VERSION ""

NS_ :

BS_:

BU_: Bat1 OpticalSensor TelemetryNode Master SensorF SensorR BrakeF BrakeR PDU TestBench MDB1 MDB2 MDB3 MDB4 MDB5 MDB6 Track CLU

BO_ 1474 SensorR_SDO_Req_Up: 8 TelemetryNode
 SG_ SensorR_OD_posDeviationOptic m3589 : 16|16@1+ (0.1,0) [0|6553.5] ""  SensorR
 SG_ SensorR_OD_posDeviationEncoder m3588 : 16|16@1+ (0.1,0) [0|6553.5] ""  SensorR
 SG_ SensorR_OD_velDeviationOptic m3587 : 16|16@1+ (0.1,0) [0|6553.5] ""  SensorR
 SG_ SensorR_OD_velDeviationEncoder m3586 : 16|16@1+ (0.1,0) [0|6553.5] ""  SensorR
 SG_ SensorR_OD_accDeviation m3585 : 16|16@1+ (0.1,0) [0|6553.5] ""  SensorR
 SG_ SensorR_OD_EnableSignalGene_0000 m3332 : 16|8@1+ (1,0) [0|255] ""  SensorR
 SG_ SensorR_OD_PositionGlitch m3331 : 16|16@1+ (0.1,0) [0|6553.5] ""  SensorR
 SG_ SensorR_OD_ReflectorDistance m3330 : 16|16@1+ (0.1,0) [0|6553.5] ""  SensorR
 SG_ SensorR_OD_StripeMode m3329 : 16|8@1+ (1,0) [0|255] ""  SensorR
 SG_ SensorR_OD_opc_lowpass_TcI m3123 : 16|16@1+ (0.01,0) [0|655.35] "s"  SensorR
 SG_ SensorR_OD_opc_lowpass_Tcf m3122 : 16|16@1+ (0.01,0) [0|655.35] "s"  SensorR
 SG_ SensorR_OD_opc_F_decrease m3121 : 16|16@1+ (0.01,0) [0|655.35] "F/s"  SensorR
 SG_ SensorR_OD_opc_v_threshold m3120 : 16|16@1+ (0.01,0) [0|655.35] "m/s"  SensorR
 SG_ SensorR_OD_opc_v_max m3113 : 16|16@1+ (0.01,0) [0|655.35] "m/s"  SensorR
 SG_ SensorR_OD_opc_T_acc m3112 : 16|16@1+ (0.1,0) [0|6553.5] "s"  SensorR
 SG_ SensorR_OD_opc_F_max m3111 : 16|16@1+ (1,0) [0|65535] "N"  SensorR
 SG_ SensorR_OD_opc_t_run_max m3110 : 16|16@1+ (0.1,0) [0|6553.5] "s"  SensorR
 SG_ SensorR_OD_opc_brakeFlag m3109 : 16|8@1+ (1,0) [0|255] ""  SensorR
 SG_ SensorR_OD_DebugCVOPCfreq m3108 : 16|16@1+ (0.1,-3200) [-3200|3353.5] ""  SensorR
 SG_ SensorR_OD_DebugCascadedIreq m3107 : 16|16@1+ (0.1,-3200) [-3200|3353.5] ""  SensorR
 SG_ SensorR_OD_opc_ratelimiter_f m3106 : 16|16@1+ (0.1,-3200) [-3200|3353.5] ""  SensorR
 SG_ SensorR_OD_maxRunDistance m3105 : 16|16@1+ (0.05,-1600) [-1600|1676.75] "m"  SensorR
 SG_ SensorR_OD_FinishedDelay m3104 : 16|16@1+ (1,0) [0|65535] "ms"  SensorR
 SG_ SensorR_OD_Current4Stopping m3097 : 16|16@1+ (0.1,0) [0|6553.5] "A"  SensorR
 SG_ SensorR_OD_AdaptModelByCurrent m3096 : 16|8@1+ (1,0) [0|255] ""  SensorR
 SG_ SensorR_OD_CVOPCTcFreq m3095 : 16|16@1+ (1,0) [0|65535] "ms"  SensorR
 SG_ SensorR_OD_CVOPCImin m3094 : 16|16@1+ (1,0) [0|65535] ""  SensorR
 SG_ SensorR_OD_CascadedKpDecrea_0000 m3093 : 16|16@1+ (0.1,0) [0|6553.5] "A/s"  SensorR
 SG_ SensorR_OD_CascadedKpIncrea_0000 m3092 : 16|16@1+ (0.1,0) [0|6553.5] "A/s"  SensorR
 SG_ SensorR_OD_CascadedFreqCurUpdate m3091 : 16|16@1+ (0.001,0) [0|65.535] "s"  SensorR
 SG_ SensorR_OD_CascadedMaxSetFo_0000 m3090 : 16|16@1+ (0.1,0) [0|6553.5] "Newton"  SensorR
 SG_ SensorR_OD_CurrentForConsta_0000 m3089 : 16|16@1+ (0.01,0) [0|655.35] "A"  SensorR
 SG_ SensorR_OD_AccAtCurrentMeasured m3088 : 16|16@1+ (0.01,0) [0|655.35] "m/s^2"  SensorR
 SG_ SensorR_OD_CVOPCHystereseF m3081 : 16|16@1+ (0.1,0) [0|6553.5] "Newton"  SensorR
 SG_ SensorR_OD_CVOPCReduceCurre_0000 m3080 : 16|16@1+ (0.01,0) [0|655.35] ""  SensorR
 SG_ SensorR_OD_CVOPCDeltaVelHig_0000 m3079 : 16|16@1+ (0.01,0) [0|655.35] "m/s"  SensorR
 SG_ SensorR_OD_CVOPCSmoothingDe_0000 m3078 : 16|16@1+ (0.01,0) [0|655.35] "m/s"  SensorR
 SG_ SensorR_OD_CVOPCTcI m3077 : 16|16@1+ (1,0) [0|65535] "ms"  SensorR
 SG_ SensorR_OD_CVOPCTcf m3076 : 16|16@1+ (1,0) [0|65535] "ms"  SensorR
 SG_ SensorR_OD_CVOPCImax m3075 : 16|16@1+ (1,0) [0|65535] ""  SensorR
 SG_ SensorR_OD_VelocityController m3074 : 16|8@1+ (1,0) [0|255] ""  SensorR
 SG_ SensorR_OD_TC_f m3073 : 16|16@1+ (1,0) [0|65535] "ms"  SensorR
 SG_ SensorR_OD_TC_I m3072 : 16|16@1+ (1,0) [0|65535] "ms"  SensorR
 SG_ SensorR_OD_EstimatedRunLength m2826 : 16|16@1+ (0.05,-1600) [-1600|1676.75] "m"  SensorR
 SG_ SensorR_OD_RunProfile_V4 m2825 : 16|16@1+ (0.01,-327) [-327|328.35] "m/s"  SensorR
 SG_ SensorR_OD_RunProfile_T4 m2824 : 16|16@1+ (10,0) [0|655350] "ms"  SensorR
 SG_ SensorR_OD_RunProfile_V3 m2823 : 16|16@1+ (0.01,-327) [-327|328.35] "m/s"  SensorR
 SG_ SensorR_OD_RunProfile_T3 m2822 : 16|16@1+ (10,0) [0|655350] "ms"  SensorR
 SG_ SensorR_OD_RunProfile_V2 m2821 : 16|16@1+ (0.01,-327) [-327|328.35] "m/s"  SensorR
 SG_ SensorR_OD_RunProfile_T2 m2820 : 16|16@1+ (10,0) [0|655350] "ms"  SensorR
 SG_ SensorR_OD_RunProfile_V1 m2819 : 16|16@1+ (0.01,-327) [-327|328.35] "m/s"  SensorR
 SG_ SensorR_OD_RunProfile_T1 m2818 : 16|16@1+ (10,0) [0|655350] "ms"  SensorR
 SG_ SensorR_OD_RunProfile_V0 m2817 : 16|16@1+ (0.01,-327) [-327|328.35] "m/s"  SensorR
 SG_ SensorR_OD_RunProfile_T0 m2816 : 16|16@1+ (10,0) [0|655350] "ms"  SensorR
 SG_ SensorR_OD_SetFinish m2637 : 16|8@1+ (1,0) [0|255] ""  SensorR
 SG_ SensorR_OD_RunMode m2636 : 16|8@1+ (1,0) [0|255] ""  SensorR
 SG_ SensorR_OD_VdcReduceFactor m2635 : 16|16@1+ (0.1,0) [0|6553.5] ""  SensorR
 SG_ SensorR_OD_MaxRequiredVelocity m2634 : 16|16@1+ (0.1,0) [0|6553.5] "m/s"  SensorR
 SG_ SensorR_OD_WarningThreshhol_0000 m2633 : 16|16@1+ (0.001,0) [0|65.535] "s"  SensorR
 SG_ SensorR_OD_MaxCtrlErrorDuration m2632 : 16|16@1+ (0.01,0) [0|655.35] "s"  SensorR
 SG_ SensorR_OD_MaxCtrlError m2631 : 16|16@1+ (0.01,0) [0|655.35] "m/s"  SensorR
 SG_ SensorR_OD_FminCtrl m2630 : 16|16@1+ (1.0,0) [0|65535.0] "N"  SensorR
 SG_ SensorR_OD_FmaxCtrl m2629 : 16|16@1+ (1.0,0) [0|65535.0] "N"  SensorR
 SG_ SensorR_OD_PodMass m2628 : 16|16@1+ (0.1,0) [0|6553.5] "kg"  SensorR
 SG_ SensorR_OD_CurrentReq m2627 : 16|16@1+ (0.1,0) [0|6553.5] "A"  SensorR
 SG_ SensorR_OD_CtrlMode m2626 : 16|8@1+ (1,0) [0|255] ""  SensorR
 SG_ SensorR_OD_OpcKi m2625 : 16|16@1+ (0.01,0) [0|655.35] ""  SensorR
 SG_ SensorR_OD_OpcKp m2624 : 16|16@1+ (0.01,0) [0|655.35] ""  SensorR
 SG_ SensorR_OD_ExecTimeReadSensors m2611 : 16|16@1+ (0.01,0) [0|655.35] "ms"  SensorR
 SG_ SensorR_OD_ExecTimeControl m2610 : 16|16@1+ (0.01,0) [0|655.35] "ms"  SensorR
 SG_ SensorR_OD_ExecTimeStateEst m2609 : 16|16@1+ (0.01,0) [0|655.35] "ms"  SensorR
 SG_ SensorR_OD_ExecTimeOverall m2608 : 16|16@1+ (0.01,0) [0|655.35] "ms"  SensorR
 SG_ SensorR_OD_IMU3_Temperature m2599 : 16|16@1+ (0.01,-100) [-100|555.35] ""  SensorR
 SG_ SensorR_OD_IMU2_Temperature m2598 : 16|16@1+ (0.01,-100) [-100|555.35] ""  SensorR
 SG_ SensorR_OD_IMU1_Temperature m2597 : 16|16@1+ (0.01,-100) [-100|555.35] ""  SensorR
 SG_ SensorR_OD_IMU_number m2592 : 16|8@1+ (1,0) [0|255] ""  SensorR
 SG_ SensorR_OD_EncoderResetPosition m2586 : 16|8@1+ (1,0) [0|255] ""  SensorR
 SG_ SensorR_OD_EncoderWheelDiameter m2576 : 16|16@1+ (0.005,0) [1|300] "mm"  SensorR
 SG_ SensorR_OD_samplingInterval m2048 : 16|16@1+ (0.01,0) [0.01|100] "ms"  SensorR
 SG_ SensorR_OD_CAN2_DelayedTxMe_0000 m1129 : 16|24@1+ (1,0) [0|16777215] ""  SensorR
 SG_ SensorR_OD_CAN2_ErrorStatus m1128 : 16|8@1+ (1,0) [0|255] ""  SensorR
 SG_ SensorR_OD_CAN2_DiscardedTx_0000 m1127 : 16|24@1+ (1,0) [0|16777215] ""  SensorR
 SG_ SensorR_OD_CAN2_Status m1126 : 16|8@1+ (1,0) [0|255] ""  SensorR
 SG_ SensorR_OD_CAN2_Baudrate m1124 : 16|16@1+ (1,0) [125|1000] "kbps"  SensorR
 SG_ SensorR_OD_CAN2_autoErrorReset m1123 : 16|8@1+ (1,0) [0|255] ""  SensorR
 SG_ SensorR_OD_CAN2_lastErrorCode m1122 : 16|32@1+ (1,0) [0|4294967295] ""  SensorR
 SG_ SensorR_OD_CAN2_RxErrCnt m1121 : 16|8@1+ (1,0) [0|255] ""  SensorR
 SG_ SensorR_OD_CAN2_TxErrCnt m1120 : 16|8@1+ (1,0) [0|255] ""  SensorR
 SG_ SensorR_OD_CAN1_DelayedTxMe_0000 m1113 : 16|24@1+ (1,0) [0|16777215] ""  SensorR
 SG_ SensorR_OD_CAN1_ErrorStatus m1112 : 16|8@1+ (1,0) [0|255] ""  SensorR
 SG_ SensorR_OD_CAN1_DiscardedTx_0000 m1111 : 16|24@1+ (1,0) [0|16777215] ""  SensorR
 SG_ SensorR_OD_CAN1_Status m1110 : 16|8@1+ (1,0) [0|255] ""  SensorR
 SG_ SensorR_OD_CAN1_Baudrate m1108 : 16|16@1+ (1,0) [125|1000] "kbps"  SensorR
 SG_ SensorR_OD_CAN1_autoErrorReset m1107 : 16|8@1+ (1,0) [0|255] ""  SensorR
 SG_ SensorR_OD_CAN1_lastErrorCode m1106 : 16|32@1+ (1,0) [0|4294967295] ""  SensorR
 SG_ SensorR_OD_CAN1_RxErrCnt m1105 : 16|8@1+ (1,0) [0|255] ""  SensorR
 SG_ SensorR_OD_CAN1_TxErrCnt m1104 : 16|8@1+ (1,0) [0|255] ""  SensorR
 SG_ SensorR_OD_BuildTime m1073 : 16|24@1+ (1,0) [0|16777215] ""  SensorR
 SG_ SensorR_OD_BuildDate m1072 : 16|32@1+ (1,0) [0|4294967295] ""  SensorR
 SG_ SensorR_OD_ChipUID2 m1057 : 16|48@1+ (1,0) [0|281474976710655] ""  SensorR
 SG_ SensorR_OD_ChipUID1 m1056 : 16|48@1+ (1,0) [0|281474976710655] ""  SensorR
 SG_ SensorR_OD_SdcOut m1046 : 16|8@1+ (1,0) [0|255] ""  SensorR
 SG_ SensorR_OD_SdcIn m1045 : 16|8@1+ (1,0) [0|255] ""  SensorR
 SG_ SensorR_OD_runtime m1044 : 16|24@1+ (1,0) [0|16777215] "ms"  SensorR
 SG_ SensorR_OD_InputVoltage m1043 : 16|16@1+ (0.001,0) [0|65.535] "V"  SensorR
 SG_ SensorR_OD_BoardTemp m1042 : 16|16@1+ (0.01,-30) [-30|625.35] "°C"  SensorR
 SG_ SensorR_OD_MemFree m1041 : 16|16@1+ (4,0) [0|262140] "bytes"  SensorR
 SG_ SensorR_OD_CpuUsage m1040 : 16|8@1+ (0.5,0) [0|100] "%"  SensorR
 SG_ SensorR_OD_OdEntrySendInterval m33 : 16|16@1+ (1,0) [0|65535] "ms"  SensorR
 SG_ SensorR_OD_SendOdOnBootup m32 : 16|8@1+ (1,0) [0|255] ""  SensorR
 SG_ SensorR_OD_HeartbeatInterval m16 : 16|16@1+ (1,0) [0|65535] "ms"  SensorR
 SG_ SensorR_OD_DbcVersion m5 : 16|16@1+ (1,0) [0|65535] ""  SensorR
 SG_ SensorR_OD_StackVersion m4 : 16|16@1+ (1,0) [0|65535] ""  SensorR
 SG_ SensorR_OD_ProtocolVersion m3 : 16|16@1+ (1,0) [0|65535] ""  SensorR
 SG_ SensorR_OD_NodeStatus m2 : 16|8@1+ (1,0) [0|255] ""  SensorR
 SG_ SensorR_OD_NodeID m1 : 16|8@1+ (1,0) [0|255] ""  SensorR
 SG_ SensorR_SDO_ID M : 0|12@1+ (1,0) [0|4095] ""  SensorR

BO_ 1538 SensorR_SDO_Req_Down: 2 TelemetryNode
 SG_ SensorR_SDO_ID M : 0|12@1+ (1,0) [0|4095] ""  SensorR

BO_ 1794 SensorR_Heartbeat: 1 SensorR
 SG_ SensorR_NodeState : 0|8@1+ (1,0) [0|0] ""  Master,TelemetryNode

BO_ 1858 SensorR_BTL_TX: 8 SensorR

BO_ 1922 SensorR_BTL_RX: 8 TelemetryNode

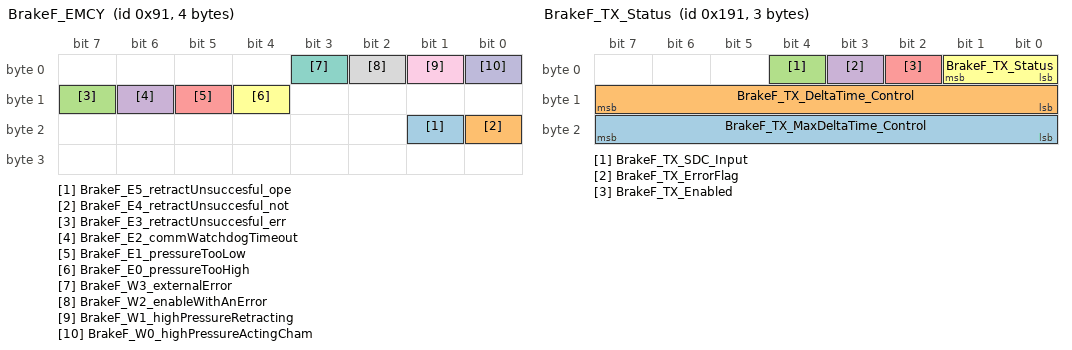
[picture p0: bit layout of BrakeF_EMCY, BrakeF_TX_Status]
BO_ 145 BrakeF_EMCY: 4 BrakeF
 SG_ BrakeF_E5_retractUnsuccesful_ope : 17|1@1+ (1,0) [0|0] ""  Master,TelemetryNode
 SG_ BrakeF_E4_retractUnsuccesful_not : 16|1@1+ (1,0) [0|0] ""  Master,TelemetryNode
 SG_ BrakeF_E3_retractUnsuccesful_err : 15|1@1+ (1,0) [0|0] ""  Master,TelemetryNode
 SG_ BrakeF_E2_commWatchdogTimeout : 14|1@1+ (1,0) [0|0] ""  Master,TelemetryNode
 SG_ BrakeF_E1_pressureTooLow : 13|1@1+ (1,0) [0|0] ""  Master,TelemetryNode
 SG_ BrakeF_E0_pressureTooHigh : 12|1@1+ (1,0) [0|0] ""  Master,TelemetryNode
 SG_ BrakeF_W3_externalError : 3|1@1+ (1,0) [0|0] ""  Master,TelemetryNode
 SG_ BrakeF_W2_enableWithAnError : 2|1@1+ (1,0) [0|0] ""  Master,TelemetryNode
 SG_ BrakeF_W1_highPressureRetracting : 1|1@1+ (1,0) [0|0] ""  Master,TelemetryNode
 SG_ BrakeF_W0_highPressureActingCham : 0|1@1+ (1,0) [0|0] ""  Master,TelemetryNode

BO_ 401 BrakeF_TX_Status: 3 BrakeF
 SG_ BrakeF_TX_MaxDeltaTime_Control : 16|8@1+ (1,0) [0|255] "ms" Vector__XXX
 SG_ BrakeF_TX_DeltaTime_Control : 8|8@1+ (1,0) [0|255] "ms" Vector__XXX
 SG_ BrakeF_TX_SDC_Input : 4|1@1+ (1,0) [0|0] "" Vector__XXX
 SG_ BrakeF_TX_ErrorFlag : 3|1@1+ (1,0) [0|0] ""  SensorF
 SG_ BrakeF_TX_Enabled : 2|1@1+ (1,0) [0|0] ""  SensorF
 SG_ BrakeF_TX_Status : 0|2@1+ (1,0) [0|0] ""  SensorF

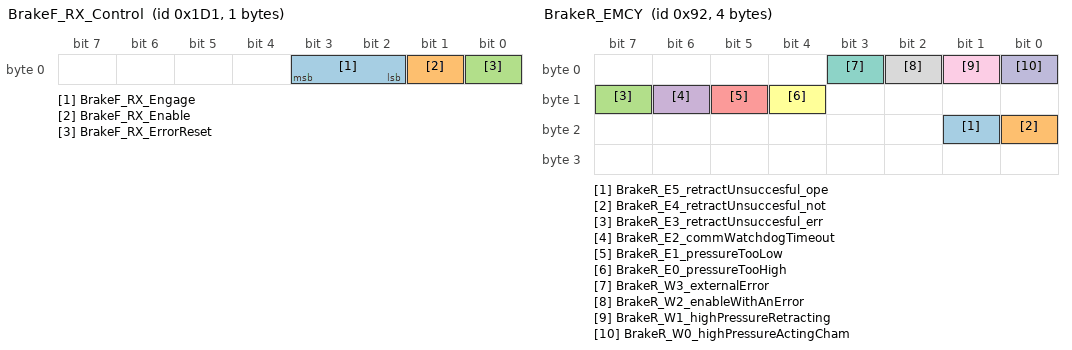
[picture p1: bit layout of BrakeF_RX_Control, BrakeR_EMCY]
BO_ 465 BrakeF_RX_Control: 1 SensorF
 SG_ BrakeF_RX_Engage : 2|2@1+ (1,0) [0|0] "" Vector__XXX
 SG_ BrakeF_RX_Enable : 1|1@1+ (1,0) [0|0] "" Vector__XXX
 SG_ BrakeF_RX_ErrorReset : 0|1@1+ (1,0) [0|0] "" Vector__XXX

BO_ 529 BrakeF_TX_PDO2: 0 BrakeF

BO_ 593 BrakeF_RX_PDO2: 0 Vector__XXX

BO_ 657 BrakeF_TX_PDO3: 0 BrakeF

BO_ 721 BrakeF_RX_PDO3: 0 Vector__XXX

BO_ 785 BrakeF_TX_PDO4: 0 BrakeF

BO_ 849 BrakeF_RX_PDO4: 0 Vector__XXX

BO_ 913 BrakeF_TX_PDO5: 0 BrakeF

BO_ 977 BrakeF_TX_PDO6: 0 BrakeF

BO_ 1105 BrakeF_TX_PDO8: 0 BrakeF

BO_ 1169 BrakeF_TX_PDO9: 0 BrakeF

BO_ 1233 BrakeF_TX_PDO10: 0 BrakeF

BO_ 1297 BrakeF_TX_PDO11: 0 BrakeF

BO_ 1361 BrakeF_TX_PDO12: 0 BrakeF

BO_ 1425 BrakeF_SDO_Resp: 8 BrakeF
 SG_ BrakeF_OD_BrakeStatus m2304 : 16|8@1+ (1,0) [0|255] ""  TelemetryNode
 SG_ BrakeF_OD_CoolingPressure m2816 : 16|16@1+ (0.01,-100) [-100|555.35] ""  TelemetryNode
 SG_ BrakeF_OD_valveUpperTolerance m2053 : 16|16@1+ (0.005,0) [0|327.675] "bar"  TelemetryNode
 SG_ BrakeF_OD_commWatchdog m2052 : 16|16@1+ (1,0) [0|65535] "ms"  TelemetryNode
 SG_ BrakeF_OD_counterLimit m2051 : 16|8@1+ (1,0) [0|255] ""  TelemetryNode
 SG_ BrakeF_OD_delay m2050 : 16|8@1+ (0.5,0) [0|127.5] "ms"  TelemetryNode
 SG_ BrakeF_OD_tankUpperControlLimit m2049 : 16|16@1+ (0.005,0) [0|327.675] "bar"  TelemetryNode
 SG_ BrakeF_OD_tankLowerControlLimit m2048 : 16|16@1+ (0.005,0) [0|327.675] "bar"  TelemetryNode
 SG_ BrakeF_OD_CAN2_DelayedTxMessages m1129 : 16|24@1+ (1,0) [0|16777215] ""  TelemetryNode
 SG_ BrakeF_OD_CAN2_ErrorStatus m1128 : 16|8@1+ (1,0) [0|255] ""  TelemetryNode
 SG_ BrakeF_OD_CAN2_DiscardedTxMessag m1127 : 16|24@1+ (1,0) [0|16777215] ""  TelemetryNode
 SG_ BrakeF_OD_CAN2_Status m1126 : 16|8@1+ (1,0) [0|255] ""  TelemetryNode
 SG_ BrakeF_OD_CAN2_Baudrate m1124 : 16|16@1+ (1,0) [125|1000] "kbps"  TelemetryNode
 SG_ BrakeF_OD_CAN2_autoErrorReset m1123 : 16|8@1+ (1,0) [0|255] ""  TelemetryNode
 SG_ BrakeF_OD_CAN2_lastErrorCode m1122 : 16|32@1+ (1,0) [0|4294967295] ""  TelemetryNode
 SG_ BrakeF_OD_CAN2_RxErrCnt m1121 : 16|8@1+ (1,0) [0|255] ""  TelemetryNode
 SG_ BrakeF_OD_CAN2_TxErrCnt m1120 : 16|8@1+ (1,0) [0|255] ""  TelemetryNode
 SG_ BrakeF_OD_CAN1_DelayedTxMessages m1113 : 16|24@1+ (1,0) [0|16777215] ""  TelemetryNode
 SG_ BrakeF_OD_CAN1_ErrorStatus m1112 : 16|8@1+ (1,0) [0|255] ""  TelemetryNode
 SG_ BrakeF_OD_CAN1_DiscardedTxMessag m1111 : 16|24@1+ (1,0) [0|16777215] ""  TelemetryNode
 SG_ BrakeF_OD_CAN1_Status m1110 : 16|8@1+ (1,0) [0|255] ""  TelemetryNode
 SG_ BrakeF_OD_CAN1_Baudrate m1108 : 16|16@1+ (1,0) [125|1000] "kbps"  TelemetryNode
 SG_ BrakeF_OD_CAN1_autoErrorReset m1107 : 16|8@1+ (1,0) [0|255] ""  TelemetryNode
 SG_ BrakeF_OD_CAN1_lastErrorCode m1106 : 16|32@1+ (1,0) [0|4294967295] ""  TelemetryNode
 SG_ BrakeF_OD_CAN1_RxErrCnt m1105 : 16|8@1+ (1,0) [0|255] ""  TelemetryNode
 SG_ BrakeF_OD_CAN1_TxErrCnt m1104 : 16|8@1+ (1,0) [0|255] ""  TelemetryNode
 SG_ BrakeF_OD_BuildTime m1073 : 16|24@1+ (1,0) [0|16777215] ""  TelemetryNode
 SG_ BrakeF_OD_BuildDate m1072 : 16|32@1+ (1,0) [0|4294967295] ""  TelemetryNode
 SG_ BrakeF_OD_ChipUID2 m1057 : 16|48@1+ (1,0) [0|281474976710655] ""  TelemetryNode
 SG_ BrakeF_OD_ChipUID1 m1056 : 16|48@1+ (1,0) [0|281474976710655] ""  TelemetryNode
 SG_ BrakeF_OD_SdcOut m1046 : 16|8@1+ (1,0) [0|255] ""  TelemetryNode
 SG_ BrakeF_OD_SdcIn m1045 : 16|8@1+ (1,0) [0|255] ""  TelemetryNode
 SG_ BrakeF_OD_runtime m1044 : 16|24@1+ (1,0) [0|16777215] "ms"  TelemetryNode
 SG_ BrakeF_OD_InputVoltage m1043 : 16|16@1+ (0.001,0) [0|65.535] "V"  TelemetryNode
 SG_ BrakeF_OD_BoardTemp m1042 : 16|16@1+ (0.01,-30) [-30|625.35] "°C"  TelemetryNode
 SG_ BrakeF_OD_MemFree m1041 : 16|16@1+ (4,0) [0|262140] "bytes"  TelemetryNode
 SG_ BrakeF_OD_CpuUsage m1040 : 16|8@1+ (0.5,0) [0|100] "%"  TelemetryNode
 SG_ BrakeF_OD_OdEntrySendInterval m33 : 16|16@1+ (1,0) [0|65535] "ms"  TelemetryNode
 SG_ BrakeF_OD_SendOdOnBootup m32 : 16|8@1+ (1,0) [0|255] ""  TelemetryNode
 SG_ BrakeF_OD_HeartbeatInterval m16 : 16|16@1+ (1,0) [0|65535] "ms"  TelemetryNode
 SG_ BrakeF_OD_DbcVersion m5 : 16|16@1+ (1,0) [0|65535] ""  TelemetryNode
 SG_ BrakeF_OD_StackVersion m4 : 16|16@1+ (1,0) [0|65535] ""  TelemetryNode
 SG_ BrakeF_OD_ProtocolVersion m3 : 16|16@1+ (1,0) [0|65535] ""  TelemetryNode
 SG_ BrakeF_OD_NodeStatus m2 : 16|8@1+ (1,0) [0|255] ""  TelemetryNode
 SG_ BrakeF_OD_NodeID m1 : 16|8@1+ (1,0) [0|255] ""  TelemetryNode
 SG_ BrakeF_SDO_RespCode : 12|4@1+ (1,0) [0|0] ""  TelemetryNode
 SG_ BrakeF_SDO_ID M : 0|12@1+ (1,0) [0|4095] ""  TelemetryNode

BO_ 1489 BrakeF_SDO_Req_Up: 8 TelemetryNode
 SG_ BrakeF_OD_BrakeStatus m2304 : 16|8@1+ (1,0) [0|255] ""  BrakeF
 SG_ BrakeF_OD_CoolingPressure m2816 : 16|16@1+ (0.01,-100) [-100|555.35] ""  BrakeF
 SG_ BrakeF_OD_valveUpperTolerance m2053 : 16|16@1+ (0.005,0) [0|327.675] "bar"  BrakeF
 SG_ BrakeF_OD_commWatchdog m2052 : 16|16@1+ (1,0) [0|65535] "ms"  BrakeF
 SG_ BrakeF_OD_counterLimit m2051 : 16|8@1+ (1,0) [0|255] ""  BrakeF
 SG_ BrakeF_OD_delay m2050 : 16|8@1+ (0.5,0) [0|127.5] "ms"  BrakeF
 SG_ BrakeF_OD_tankUpperControlLimit m2049 : 16|16@1+ (0.005,0) [0|327.675] "bar"  BrakeF
 SG_ BrakeF_OD_tankLowerControlLimit m2048 : 16|16@1+ (0.005,0) [0|327.675] "bar"  BrakeF
 SG_ BrakeF_OD_CAN2_DelayedTxMessages m1129 : 16|24@1+ (1,0) [0|16777215] ""  BrakeF
 SG_ BrakeF_OD_CAN2_ErrorStatus m1128 : 16|8@1+ (1,0) [0|255] ""  BrakeF
 SG_ BrakeF_OD_CAN2_DiscardedTxM_0000 m1127 : 16|24@1+ (1,0) [0|16777215] ""  BrakeF
 SG_ BrakeF_OD_CAN2_Status m1126 : 16|8@1+ (1,0) [0|255] ""  BrakeF
 SG_ BrakeF_OD_CAN2_Baudrate m1124 : 16|16@1+ (1,0) [125|1000] "kbps"  BrakeF
 SG_ BrakeF_OD_CAN2_autoErrorReset m1123 : 16|8@1+ (1,0) [0|255] ""  BrakeF
 SG_ BrakeF_OD_CAN2_lastErrorCode m1122 : 16|32@1+ (1,0) [0|4294967295] ""  BrakeF
 SG_ BrakeF_OD_CAN2_RxErrCnt m1121 : 16|8@1+ (1,0) [0|255] ""  BrakeF
 SG_ BrakeF_OD_CAN2_TxErrCnt m1120 : 16|8@1+ (1,0) [0|255] ""  BrakeF
 SG_ BrakeF_OD_CAN1_DelayedTxMessages m1113 : 16|24@1+ (1,0) [0|16777215] ""  BrakeF
 SG_ BrakeF_OD_CAN1_ErrorStatus m1112 : 16|8@1+ (1,0) [0|255] ""  BrakeF
 SG_ BrakeF_OD_CAN1_DiscardedTxM_0000 m1111 : 16|24@1+ (1,0) [0|16777215] ""  BrakeF
 SG_ BrakeF_OD_CAN1_Status m1110 : 16|8@1+ (1,0) [0|255] ""  BrakeF
 SG_ BrakeF_OD_CAN1_Baudrate m1108 : 16|16@1+ (1,0) [125|1000] "kbps"  BrakeF
 SG_ BrakeF_OD_CAN1_autoErrorReset m1107 : 16|8@1+ (1,0) [0|255] ""  BrakeF
 SG_ BrakeF_OD_CAN1_lastErrorCode m1106 : 16|32@1+ (1,0) [0|4294967295] ""  BrakeF
 SG_ BrakeF_OD_CAN1_RxErrCnt m1105 : 16|8@1+ (1,0) [0|255] ""  BrakeF
 SG_ BrakeF_OD_CAN1_TxErrCnt m1104 : 16|8@1+ (1,0) [0|255] ""  BrakeF
 SG_ BrakeF_OD_BuildTime m1073 : 16|24@1+ (1,0) [0|16777215] ""  BrakeF
 SG_ BrakeF_OD_BuildDate m1072 : 16|32@1+ (1,0) [0|4294967295] ""  BrakeF
 SG_ BrakeF_OD_ChipUID2 m1057 : 16|48@1+ (1,0) [0|281474976710655] ""  BrakeF
 SG_ BrakeF_OD_ChipUID1 m1056 : 16|48@1+ (1,0) [0|281474976710655] ""  BrakeF
 SG_ BrakeF_OD_SdcOut m1046 : 16|8@1+ (1,0) [0|255] ""  BrakeF
 SG_ BrakeF_OD_SdcIn m1045 : 16|8@1+ (1,0) [0|255] ""  BrakeF
 SG_ BrakeF_OD_runtime m1044 : 16|24@1+ (1,0) [0|16777215] "ms"  BrakeF
 SG_ BrakeF_OD_InputVoltage m1043 : 16|16@1+ (0.001,0) [0|65.535] "V"  BrakeF
 SG_ BrakeF_OD_BoardTemp m1042 : 16|16@1+ (0.01,-30) [-30|625.35] "°C"  BrakeF
 SG_ BrakeF_OD_MemFree m1041 : 16|16@1+ (4,0) [0|262140] "bytes"  BrakeF
 SG_ BrakeF_OD_CpuUsage m1040 : 16|8@1+ (0.5,0) [0|100] "%"  BrakeF
 SG_ BrakeF_OD_OdEntrySendInterval m33 : 16|16@1+ (1,0) [0|65535] "ms"  BrakeF
 SG_ BrakeF_OD_SendOdOnBootup m32 : 16|8@1+ (1,0) [0|255] ""  BrakeF
 SG_ BrakeF_OD_HeartbeatInterval m16 : 16|16@1+ (1,0) [0|65535] "ms"  BrakeF
 SG_ BrakeF_OD_DbcVersion m5 : 16|16@1+ (1,0) [0|65535] ""  BrakeF
 SG_ BrakeF_OD_StackVersion m4 : 16|16@1+ (1,0) [0|65535] ""  BrakeF
 SG_ BrakeF_OD_ProtocolVersion m3 : 16|16@1+ (1,0) [0|65535] ""  BrakeF
 SG_ BrakeF_OD_NodeStatus m2 : 16|8@1+ (1,0) [0|255] ""  BrakeF
 SG_ BrakeF_OD_NodeID m1 : 16|8@1+ (1,0) [0|255] ""  BrakeF
 SG_ BrakeF_SDO_ID M : 0|12@1+ (1,0) [0|4095] ""  BrakeF

BO_ 1553 BrakeF_SDO_Req_Down: 2 TelemetryNode
 SG_ BrakeF_SDO_ID M : 0|12@1+ (1,0) [0|4095] ""  BrakeF

BO_ 1809 BrakeF_Heartbeat: 1 BrakeF
 SG_ BrakeF_NodeState : 0|8@1+ (1,0) [0|0] ""  SensorF,Master,TelemetryNode

BO_ 1873 BrakeF_BTL_TX: 8 BrakeF

BO_ 1937 BrakeF_BTL_RX: 8 TelemetryNode

BO_ 146 BrakeR_EMCY: 4 BrakeR
 SG_ BrakeR_E5_retractUnsuccesful_ope : 17|1@1+ (1,0) [0|0] ""  Master,TelemetryNode
 SG_ BrakeR_E4_retractUnsuccesful_not : 16|1@1+ (1,0) [0|0] ""  Master,TelemetryNode
 SG_ BrakeR_E3_retractUnsuccesful_err : 15|1@1+ (1,0) [0|0] ""  Master,TelemetryNode
 SG_ BrakeR_E2_commWatchdogTimeout : 14|1@1+ (1,0) [0|0] ""  Master,TelemetryNode
 SG_ BrakeR_E1_pressureTooLow : 13|1@1+ (1,0) [0|0] ""  Master,TelemetryNode
 SG_ BrakeR_E0_pressureTooHigh : 12|1@1+ (1,0) [0|0] ""  Master,TelemetryNode
 SG_ BrakeR_W3_externalError : 3|1@1+ (1,0) [0|0] ""  Master,TelemetryNode
 SG_ BrakeR_W2_enableWithAnError : 2|1@1+ (1,0) [0|0] ""  Master,TelemetryNode
 SG_ BrakeR_W1_highPressureRetracting : 1|1@1+ (1,0) [0|0] ""  Master,TelemetryNode
 SG_ BrakeR_W0_highPressureActingCham : 0|1@1+ (1,0) [0|0] ""  Master,TelemetryNode

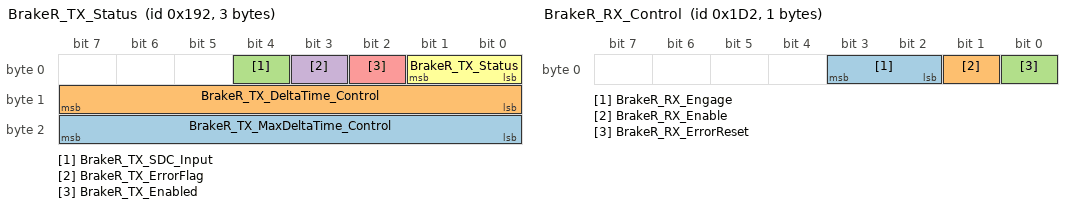
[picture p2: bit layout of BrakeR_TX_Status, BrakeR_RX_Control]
BO_ 402 BrakeR_TX_Status: 3 BrakeR
 SG_ BrakeR_TX_MaxDeltaTime_Control : 16|8@1+ (1,0) [0|255] "ms" Vector__XXX
 SG_ BrakeR_TX_DeltaTime_Control : 8|8@1+ (1,0) [0|255] "ms" Vector__XXX
 SG_ BrakeR_TX_SDC_Input : 4|1@1+ (1,0) [0|0] "" Vector__XXX
 SG_ BrakeR_TX_ErrorFlag : 3|1@1+ (1,0) [0|0] "" Vector__XXX
 SG_ BrakeR_TX_Enabled : 2|1@1+ (1,0) [0|0] "" Vector__XXX
 SG_ BrakeR_TX_Status : 0|2@1+ (1,0) [0|0] "" Vector__XXX

BO_ 466 BrakeR_RX_Control: 1 SensorF
 SG_ BrakeR_RX_Engage : 2|2@1+ (1,0) [0|0] "" Vector__XXX
 SG_ BrakeR_RX_Enable : 1|1@1+ (1,0) [0|0] "" Vector__XXX
 SG_ BrakeR_RX_ErrorReset : 0|1@1+ (1,0) [0|0] "" Vector__XXX

BO_ 530 BrakeR_TX_PDO2: 0 BrakeR

BO_ 594 BrakeR_RX_PDO2: 0 Vector__XXX

BO_ 658 BrakeR_TX_PDO3: 0 BrakeR

BO_ 722 BrakeR_RX_PDO3: 0 Vector__XXX

BO_ 786 BrakeR_TX_PDO4: 0 BrakeR

BO_ 850 BrakeR_RX_PDO4: 0 Vector__XXX

BO_ 914 BrakeR_TX_PDO5: 0 BrakeR

BO_ 978 BrakeR_TX_PDO6: 0 BrakeR

BO_ 1042 BrakeR_TX_PDO7: 0 BrakeR

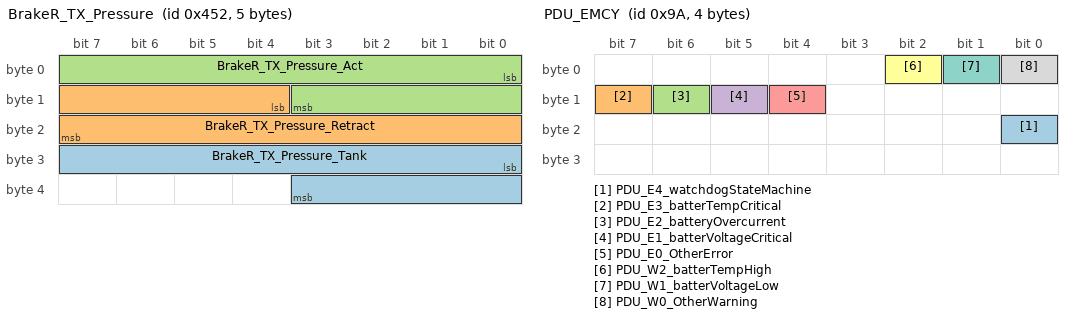
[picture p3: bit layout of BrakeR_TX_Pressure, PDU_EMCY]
BO_ 1106 BrakeR_TX_Pressure: 5 BrakeR
 SG_ BrakeR_TX_Pressure_Tank : 24|12@1+ (0.005,-2) [-2|18.475] "bar" Vector__XXX
 SG_ BrakeR_TX_Pressure_Retract : 12|12@1+ (0.005,-2) [-2|18.475] "bar" Vector__XXX
 SG_ BrakeR_TX_Pressure_Act : 0|12@1+ (0.005,-2) [-2|18.475] "bar" Vector__XXX

BO_ 1170 BrakeR_TX_PDO9: 0 BrakeR

BO_ 1234 BrakeR_TX_PDO10: 0 BrakeR

BO_ 1298 BrakeR_TX_PDO11: 0 BrakeR

BO_ 1362 BrakeR_TX_PDO12: 0 BrakeR

BO_ 1426 BrakeR_SDO_Resp: 8 BrakeR
 SG_ BrakeR_OD_valveUpperTolerance m2053 : 16|16@1+ (0.005,0) [0|327.675] "bar"  TelemetryNode
 SG_ BrakeR_OD_commWatchdog m2052 : 16|16@1+ (1,0) [0|65535] "ms"  TelemetryNode
 SG_ BrakeR_OD_counterLimit m2051 : 16|8@1+ (1,0) [0|255] ""  TelemetryNode
 SG_ BrakeR_OD_delay m2050 : 16|8@1+ (0.5,0) [0|127.5] "ms"  TelemetryNode
 SG_ BrakeR_OD_tankUpperControlLimit m2049 : 16|16@1+ (0.005,0) [0|327.675] "bar"  TelemetryNode
 SG_ BrakeR_OD_tankLowerControlLimit m2048 : 16|16@1+ (0.005,0) [0|327.675] "bar"  TelemetryNode
 SG_ BrakeR_OD_CAN2_DelayedTxMessages m1129 : 16|24@1+ (1,0) [0|16777215] ""  TelemetryNode
 SG_ BrakeR_OD_CAN2_ErrorStatus m1128 : 16|8@1+ (1,0) [0|255] ""  TelemetryNode
 SG_ BrakeR_OD_CAN2_DiscardedTxMessag m1127 : 16|24@1+ (1,0) [0|16777215] ""  TelemetryNode
 SG_ BrakeR_OD_CAN2_Status m1126 : 16|8@1+ (1,0) [0|255] ""  TelemetryNode
 SG_ BrakeR_OD_CAN2_Baudrate m1124 : 16|16@1+ (1,0) [125|1000] "kbps"  TelemetryNode
 SG_ BrakeR_OD_CAN2_autoErrorReset m1123 : 16|8@1+ (1,0) [0|255] ""  TelemetryNode
 SG_ BrakeR_OD_CAN2_lastErrorCode m1122 : 16|32@1+ (1,0) [0|4294967295] ""  TelemetryNode
 SG_ BrakeR_OD_CAN2_RxErrCnt m1121 : 16|8@1+ (1,0) [0|255] ""  TelemetryNode
 SG_ BrakeR_OD_CAN2_TxErrCnt m1120 : 16|8@1+ (1,0) [0|255] ""  TelemetryNode
 SG_ BrakeR_OD_CAN1_DelayedTxMessages m1113 : 16|24@1+ (1,0) [0|16777215] ""  TelemetryNode
 SG_ BrakeR_OD_CAN1_ErrorStatus m1112 : 16|8@1+ (1,0) [0|255] ""  TelemetryNode
 SG_ BrakeR_OD_CAN1_DiscardedTxMessag m1111 : 16|24@1+ (1,0) [0|16777215] ""  TelemetryNode
 SG_ BrakeR_OD_CAN1_Status m1110 : 16|8@1+ (1,0) [0|255] ""  TelemetryNode
 SG_ BrakeR_OD_CAN1_Baudrate m1108 : 16|16@1+ (1,0) [125|1000] "kbps"  TelemetryNode
 SG_ BrakeR_OD_CAN1_autoErrorReset m1107 : 16|8@1+ (1,0) [0|255] ""  TelemetryNode
 SG_ BrakeR_OD_CAN1_lastErrorCode m1106 : 16|32@1+ (1,0) [0|4294967295] ""  TelemetryNode
 SG_ BrakeR_OD_CAN1_RxErrCnt m1105 : 16|8@1+ (1,0) [0|255] ""  TelemetryNode
 SG_ BrakeR_OD_CAN1_TxErrCnt m1104 : 16|8@1+ (1,0) [0|255] ""  TelemetryNode
 SG_ BrakeR_OD_BuildTime m1073 : 16|24@1+ (1,0) [0|16777215] ""  TelemetryNode
 SG_ BrakeR_OD_BuildDate m1072 : 16|32@1+ (1,0) [0|4294967295] ""  TelemetryNode
 SG_ BrakeR_OD_ChipUID2 m1057 : 16|48@1+ (1,0) [0|281474976710655] ""  TelemetryNode
 SG_ BrakeR_OD_ChipUID1 m1056 : 16|48@1+ (1,0) [0|281474976710655] ""  TelemetryNode
 SG_ BrakeR_OD_SdcOut m1046 : 16|8@1+ (1,0) [0|255] ""  TelemetryNode
 SG_ BrakeR_OD_SdcIn m1045 : 16|8@1+ (1,0) [0|255] ""  TelemetryNode
 SG_ BrakeR_OD_runtime m1044 : 16|24@1+ (1,0) [0|16777215] "ms"  TelemetryNode
 SG_ BrakeR_OD_InputVoltage m1043 : 16|16@1+ (0.001,0) [0|65.535] "V"  TelemetryNode
 SG_ BrakeR_OD_BoardTemp m1042 : 16|16@1+ (0.01,-30) [-30|625.35] "°C"  TelemetryNode
 SG_ BrakeR_OD_MemFree m1041 : 16|16@1+ (4,0) [0|262140] "bytes"  TelemetryNode
 SG_ BrakeR_OD_CpuUsage m1040 : 16|8@1+ (0.5,0) [0|100] "%"  TelemetryNode
 SG_ BrakeR_OD_OdEntrySendInterval m33 : 16|16@1+ (1,0) [0|65535] "ms"  TelemetryNode
 SG_ BrakeR_OD_SendOdOnBootup m32 : 16|8@1+ (1,0) [0|255] ""  TelemetryNode
 SG_ BrakeR_OD_HeartbeatInterval m16 : 16|16@1+ (1,0) [0|65535] "ms"  TelemetryNode
 SG_ BrakeR_OD_DbcVersion m5 : 16|16@1+ (1,0) [0|65535] ""  TelemetryNode
 SG_ BrakeR_OD_StackVersion m4 : 16|16@1+ (1,0) [0|65535] ""  TelemetryNode
 SG_ BrakeR_OD_ProtocolVersion m3 : 16|16@1+ (1,0) [0|65535] ""  TelemetryNode
 SG_ BrakeR_OD_NodeStatus m2 : 16|8@1+ (1,0) [0|255] ""  TelemetryNode
 SG_ BrakeR_OD_NodeID m1 : 16|8@1+ (1,0) [0|255] ""  TelemetryNode
 SG_ BrakeR_SDO_RespCode : 12|4@1+ (1,0) [0|0] ""  TelemetryNode
 SG_ BrakeR_SDO_ID M : 0|12@1+ (1,0) [0|4095] ""  TelemetryNode

BO_ 1490 BrakeR_SDO_Req_Up: 8 TelemetryNode
 SG_ BrakeR_OD_valveUpperTolerance m2053 : 16|16@1+ (0.005,0) [0|327.675] "bar"  BrakeR
 SG_ BrakeR_OD_commWatchdog m2052 : 16|16@1+ (1,0) [0|65535] "ms"  BrakeR
 SG_ BrakeR_OD_counterLimit m2051 : 16|8@1+ (1,0) [0|255] ""  BrakeR
 SG_ BrakeR_OD_delay m2050 : 16|8@1+ (0.5,0) [0|127.5] "ms"  BrakeR
 SG_ BrakeR_OD_tankUpperControlLimit m2049 : 16|16@1+ (0.005,0) [0|327.675] "bar"  BrakeR
 SG_ BrakeR_OD_tankLowerControlLimit m2048 : 16|16@1+ (0.005,0) [0|327.675] "bar"  BrakeR
 SG_ BrakeR_OD_CAN2_DelayedTxMessages m1129 : 16|24@1+ (1,0) [0|16777215] ""  BrakeR
 SG_ BrakeR_OD_CAN2_ErrorStatus m1128 : 16|8@1+ (1,0) [0|255] ""  BrakeR
 SG_ BrakeR_OD_CAN2_DiscardedTxM_0000 m1127 : 16|24@1+ (1,0) [0|16777215] ""  BrakeR
 SG_ BrakeR_OD_CAN2_Status m1126 : 16|8@1+ (1,0) [0|255] ""  BrakeR
 SG_ BrakeR_OD_CAN2_Baudrate m1124 : 16|16@1+ (1,0) [125|1000] "kbps"  BrakeR
 SG_ BrakeR_OD_CAN2_autoErrorReset m1123 : 16|8@1+ (1,0) [0|255] ""  BrakeR
 SG_ BrakeR_OD_CAN2_lastErrorCode m1122 : 16|32@1+ (1,0) [0|4294967295] ""  BrakeR
 SG_ BrakeR_OD_CAN2_RxErrCnt m1121 : 16|8@1+ (1,0) [0|255] ""  BrakeR
 SG_ BrakeR_OD_CAN2_TxErrCnt m1120 : 16|8@1+ (1,0) [0|255] ""  BrakeR
 SG_ BrakeR_OD_CAN1_DelayedTxMessages m1113 : 16|24@1+ (1,0) [0|16777215] ""  BrakeR
 SG_ BrakeR_OD_CAN1_ErrorStatus m1112 : 16|8@1+ (1,0) [0|255] ""  BrakeR
 SG_ BrakeR_OD_CAN1_DiscardedTxM_0000 m1111 : 16|24@1+ (1,0) [0|16777215] ""  BrakeR
 SG_ BrakeR_OD_CAN1_Status m1110 : 16|8@1+ (1,0) [0|255] ""  BrakeR
 SG_ BrakeR_OD_CAN1_Baudrate m1108 : 16|16@1+ (1,0) [125|1000] "kbps"  BrakeR
 SG_ BrakeR_OD_CAN1_autoErrorReset m1107 : 16|8@1+ (1,0) [0|255] ""  BrakeR
 SG_ BrakeR_OD_CAN1_lastErrorCode m1106 : 16|32@1+ (1,0) [0|4294967295] ""  BrakeR
 SG_ BrakeR_OD_CAN1_RxErrCnt m1105 : 16|8@1+ (1,0) [0|255] ""  BrakeR
 SG_ BrakeR_OD_CAN1_TxErrCnt m1104 : 16|8@1+ (1,0) [0|255] ""  BrakeR
 SG_ BrakeR_OD_BuildTime m1073 : 16|24@1+ (1,0) [0|16777215] ""  BrakeR
 SG_ BrakeR_OD_BuildDate m1072 : 16|32@1+ (1,0) [0|4294967295] ""  BrakeR
 SG_ BrakeR_OD_ChipUID2 m1057 : 16|48@1+ (1,0) [0|281474976710655] ""  BrakeR
 SG_ BrakeR_OD_ChipUID1 m1056 : 16|48@1+ (1,0) [0|281474976710655] ""  BrakeR
 SG_ BrakeR_OD_SdcOut m1046 : 16|8@1+ (1,0) [0|255] ""  BrakeR
 SG_ BrakeR_OD_SdcIn m1045 : 16|8@1+ (1,0) [0|255] ""  BrakeR
 SG_ BrakeR_OD_runtime m1044 : 16|24@1+ (1,0) [0|16777215] "ms"  BrakeR
 SG_ BrakeR_OD_InputVoltage m1043 : 16|16@1+ (0.001,0) [0|65.535] "V"  BrakeR
 SG_ BrakeR_OD_BoardTemp m1042 : 16|16@1+ (0.01,-30) [-30|625.35] "°C"  BrakeR
 SG_ BrakeR_OD_MemFree m1041 : 16|16@1+ (4,0) [0|262140] "bytes"  BrakeR
 SG_ BrakeR_OD_CpuUsage m1040 : 16|8@1+ (0.5,0) [0|100] "%"  BrakeR
 SG_ BrakeR_OD_OdEntrySendInterval m33 : 16|16@1+ (1,0) [0|65535] "ms"  BrakeR
 SG_ BrakeR_OD_SendOdOnBootup m32 : 16|8@1+ (1,0) [0|255] ""  BrakeR
 SG_ BrakeR_OD_HeartbeatInterval m16 : 16|16@1+ (1,0) [0|65535] "ms"  BrakeR
 SG_ BrakeR_OD_DbcVersion m5 : 16|16@1+ (1,0) [0|65535] ""  BrakeR
 SG_ BrakeR_OD_StackVersion m4 : 16|16@1+ (1,0) [0|65535] ""  BrakeR
 SG_ BrakeR_OD_ProtocolVersion m3 : 16|16@1+ (1,0) [0|65535] ""  BrakeR
 SG_ BrakeR_OD_NodeStatus m2 : 16|8@1+ (1,0) [0|255] ""  BrakeR
 SG_ BrakeR_OD_NodeID m1 : 16|8@1+ (1,0) [0|255] ""  BrakeR
 SG_ BrakeR_SDO_ID M : 0|12@1+ (1,0) [0|4095] ""  BrakeR

BO_ 1554 BrakeR_SDO_Req_Down: 2 TelemetryNode
 SG_ BrakeR_SDO_ID M : 0|12@1+ (1,0) [0|4095] ""  BrakeR

BO_ 1810 BrakeR_Heartbeat: 1 BrakeR
 SG_ BrakeR_NodeState : 0|8@1+ (1,0) [0|0] ""  Master,TelemetryNode

BO_ 1874 BrakeR_BTL_TX: 8 BrakeR

BO_ 1938 BrakeR_BTL_RX: 8 TelemetryNode

BO_ 154 PDU_EMCY: 4 PDU
 SG_ PDU_E4_watchdogStateMachine : 16|1@1+ (1,0) [0|0] ""  Master,TelemetryNode
 SG_ PDU_E3_batterTempCritical : 15|1@1+ (1,0) [0|0] ""  Master,TelemetryNode
 SG_ PDU_E2_batteryOvercurrent : 14|1@1+ (1,0) [0|0] ""  Master,TelemetryNode
 SG_ PDU_E1_batterVoltageCritical : 13|1@1+ (1,0) [0|0] ""  Master,TelemetryNode
 SG_ PDU_E0_OtherError : 12|1@1+ (1,0) [0|0] ""  Master,TelemetryNode
 SG_ PDU_W2_batterTempHigh : 2|1@1+ (1,0) [0|0] ""  Master,TelemetryNode
 SG_ PDU_W1_batterVoltageLow : 1|1@1+ (1,0) [0|0] ""  Master,TelemetryNode
 SG_ PDU_W0_OtherWarning : 0|1@1+ (1,0) [0|0] ""  Master,TelemetryNode

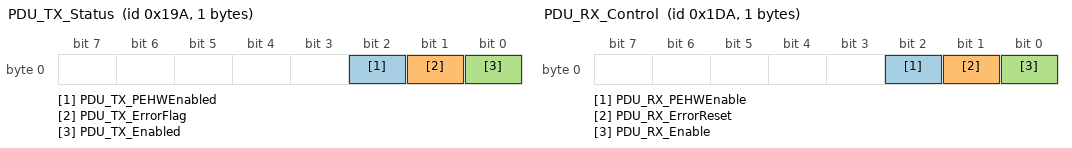
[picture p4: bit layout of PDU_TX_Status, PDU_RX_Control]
BO_ 410 PDU_TX_Status: 1 PDU
 SG_ PDU_TX_PEHWEnabled : 2|1@1+ (1,0) [0|0] ""  SensorF
 SG_ PDU_TX_ErrorFlag : 1|1@1+ (1,0) [0|0] ""  SensorF
 SG_ PDU_TX_Enabled : 0|1@1+ (1,0) [0|0] ""  SensorF

BO_ 474 PDU_RX_Control: 1 SensorF
 SG_ PDU_RX_PEHWEnable : 2|1@1+ (1,0) [0|0] ""  PDU
 SG_ PDU_RX_ErrorReset : 1|1@1+ (1,0) [0|0] ""  PDU
 SG_ PDU_RX_Enable : 0|1@1+ (1,0) [0|0] ""  PDU

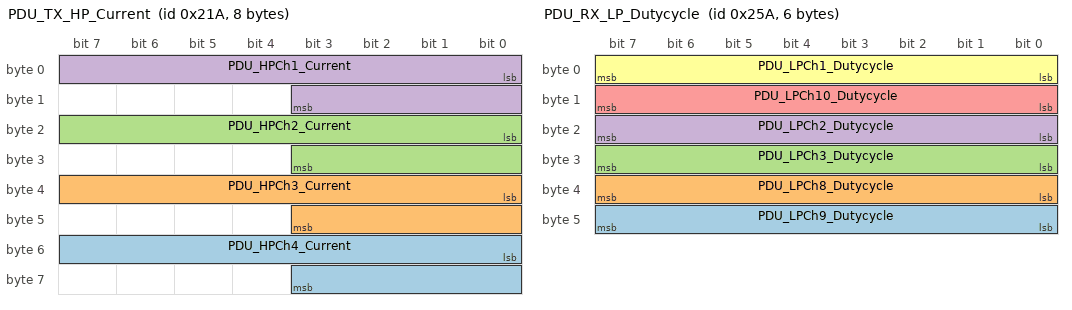
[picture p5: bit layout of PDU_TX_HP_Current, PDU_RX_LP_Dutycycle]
BO_ 538 PDU_TX_HP_Current: 8 PDU
 SG_ PDU_HPCh4_Current : 48|12@1+ (0.004,0) [0|16.38] "A"  SensorF
 SG_ PDU_HPCh3_Current : 32|12@1+ (0.004,0) [0|16.38] "A"  SensorF
 SG_ PDU_HPCh2_Current : 16|12@1+ (0.004,0) [0|16.38] "A"  SensorF
 SG_ PDU_HPCh1_Current : 0|12@1+ (0.004,0) [0|16.38] "A"  SensorF

BO_ 602 PDU_RX_LP_Dutycycle: 6 SensorF
 SG_ PDU_LPCh9_Dutycycle : 40|8@1+ (0.5,0) [0|100] "%" Vector__XXX
 SG_ PDU_LPCh8_Dutycycle : 32|8@1+ (0.5,0) [0|100] "%" Vector__XXX
 SG_ PDU_LPCh3_Dutycycle : 24|8@1+ (0.5,0) [0|100] "%" Vector__XXX
 SG_ PDU_LPCh2_Dutycycle : 16|8@1+ (0.5,0) [0|100] "%" Vector__XXX
 SG_ PDU_LPCh10_Dutycycle : 8|8@1+ (0.5,0) [0|100] "%" Vector__XXX
 SG_ PDU_LPCh1_Dutycycle : 0|8@1+ (0.5,0) [0|100] "%" Vector__XXX

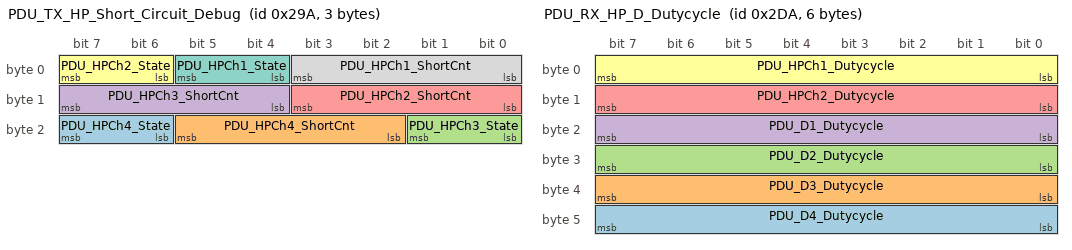
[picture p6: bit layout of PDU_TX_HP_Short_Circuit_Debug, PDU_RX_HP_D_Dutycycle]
BO_ 666 PDU_TX_HP_Short_Circuit_Debug: 3 PDU
 SG_ PDU_HPCh4_State : 22|2@1+ (1,0) [0|3] "" Vector__XXX
 SG_ PDU_HPCh4_ShortCnt : 18|4@1+ (1,0) [0|15] "" Vector__XXX
 SG_ PDU_HPCh3_State : 16|2@1+ (1,0) [0|3] "" Vector__XXX
 SG_ PDU_HPCh3_ShortCnt : 12|4@1+ (1,0) [0|15] "" Vector__XXX
 SG_ PDU_HPCh2_ShortCnt : 8|4@1+ (1,0) [0|15] "" Vector__XXX
 SG_ PDU_HPCh2_State : 6|2@1+ (1,0) [0|3] "" Vector__XXX
 SG_ PDU_HPCh1_State : 4|2@1+ (1,0) [0|3] "" Vector__XXX
 SG_ PDU_HPCh1_ShortCnt : 0|4@1+ (1,0) [0|15] "" Vector__XXX

BO_ 730 PDU_RX_HP_D_Dutycycle: 6 SensorF
 SG_ PDU_D4_Dutycycle : 40|8@1+ (0.5,0) [0|100] "%" Vector__XXX
 SG_ PDU_D3_Dutycycle : 32|8@1+ (0.5,0) [0|100] "%" Vector__XXX
 SG_ PDU_D2_Dutycycle : 24|8@1+ (0.5,0) [0|100] "%" Vector__XXX
 SG_ PDU_D1_Dutycycle : 16|8@1+ (0.5,0) [0|100] "%" Vector__XXX
 SG_ PDU_HPCh2_Dutycycle : 8|8@1+ (0.5,0) [0|100] "%" Vector__XXX
 SG_ PDU_HPCh1_Dutycycle : 0|8@1+ (0.5,0) [0|100] "%" Vector__XXX

BO_ 794 PDU_TX_PDO4: 0 PDU

BO_ 858 PDU_RX_Manual_Control: 3 Vector__XXX
 SG_ PDU_SDC_Enable : 18|1@1+ (1,0) [0|0] "" Vector__XXX
 SG_ PDU_D4_Enable : 17|1@1+ (1,0) [0|1] "" Vector__XXX
 SG_ PDU_D3_Enable : 16|1@1+ (1,0) [0|1] "" Vector__XXX
 SG_ PDU_D2_Enable : 15|1@1+ (1,0) [0|1] "" Vector__XXX
 SG_ PDU_D1_Enable : 14|1@1+ (1,0) [0|1] "" Vector__XXX
 SG_ PDU_HPCh4_Enable : 13|1@1+ (1,0) [0|1] "" Vector__XXX
 SG_ PDU_HPCh3_Enable : 12|1@1+ (1,0) [0|1] "" Vector__XXX
 SG_ PDU_HPCh2_Enable : 11|1@1+ (1,0) [0|1] "" Vector__XXX
 SG_ PDU_HPCh1_Enable : 10|1@1+ (1,0) [0|1] "" Vector__XXX
 SG_ PDU_LPCh10_Enable : 9|1@1+ (1,0) [0|1] "" Vector__XXX
 SG_ PDU_LPCh9_Enable : 8|1@1+ (1,0) [0|1] "" Vector__XXX
 SG_ PDU_LPCh8_Enable : 7|1@1+ (1,0) [0|1] "" Vector__XXX
 SG_ PDU_LPCh7_Enable : 6|1@1+ (1,0) [0|1] "" Vector__XXX
 SG_ PDU_LPCh6_Enable : 5|1@1+ (1,0) [0|1] "" Vector__XXX
 SG_ PDU_LPCh5_Enable : 4|1@1+ (1,0) [0|1] "" Vector__XXX
 SG_ PDU_LPCh4_Enable : 3|1@1+ (1,0) [0|1] "" Vector__XXX
 SG_ PDU_LPCh3_Enable : 2|1@1+ (1,0) [0|1] "" Vector__XXX
 SG_ PDU_LPCh2_Enable : 1|1@1+ (1,0) [0|1] "" Vector__XXX
 SG_ PDU_LPCh1_Enable : 0|1@1+ (1,0) [0|1] "" Vector__XXX

BO_ 922 PDU_TX_PDO5: 0 PDU

BO_ 986 PDU_TX_PDO6: 0 PDU

BO_ 1050 PDU_TX_PDO7: 0 PDU

BO_ 1114 PDU_TX_PDO8: 0 PDU

BO_ 1178 PDU_TX_LP_Short_Circuit_Debug: 8 PDU
 SG_ PDU_LPCh9_State : 58|2@1+ (1,0) [0|3] "" Vector__XXX
 SG_ PDU_LPCh8_State : 56|2@1+ (1,0) [0|3] "" Vector__XXX
 SG_ PDU_LPCh7_State : 54|2@1+ (1,0) [0|3] "" Vector__XXX
 SG_ PDU_LPCh6_State : 52|2@1+ (1,0) [0|3] "" Vector__XXX
 SG_ PDU_LPCh5_State : 50|2@1+ (1,0) [0|3] "" Vector__XXX
 SG_ PDU_LPCh4_State : 48|2@1+ (1,0) [0|3] "" Vector__XXX
 SG_ PDU_LPCh3_State : 46|2@1+ (1,0) [0|3] "" Vector__XXX
 SG_ PDU_LPCh2_State : 44|2@1+ (1,0) [0|3] "" Vector__XXX
 SG_ PDU_LPCh1_State : 42|2@1+ (1,0) [0|3] "" Vector__XXX
 SG_ PDU_LPCh10_State : 40|2@1+ (1,0) [0|3] "" Vector__XXX
 SG_ PDU_LPCh9_ShortCnt : 36|4@1+ (1,0) [0|15] "" Vector__XXX
 SG_ PDU_LPCh8_ShortCnt : 32|4@1+ (1,0) [0|15] "" Vector__XXX
 SG_ PDU_LPCh7_ShortCnt : 28|4@1+ (1,0) [0|15] "" Vector__XXX
 SG_ PDU_LPCh6_ShortCnt : 24|4@1+ (1,0) [0|15] "" Vector__XXX
 SG_ PDU_LPCh5_ShortCnt : 20|4@1+ (1,0) [0|15] "" Vector__XXX
 SG_ PDU_LPCh4_ShortCnt : 16|4@1+ (1,0) [0|15] "" Vector__XXX
 SG_ PDU_LPCh3_ShortCnt : 12|4@1+ (1,0) [0|15] "" Vector__XXX
 SG_ PDU_LPCh2_ShortCnt : 8|4@1+ (1,0) [0|15] "" Vector__XXX
 SG_ PDU_LPCh1_ShortCnt : 4|4@1+ (1,0) [0|15] "" Vector__XXX
 SG_ PDU_LPCh10_ShortCnt : 0|4@1+ (1,0) [0|15] "" Vector__XXX

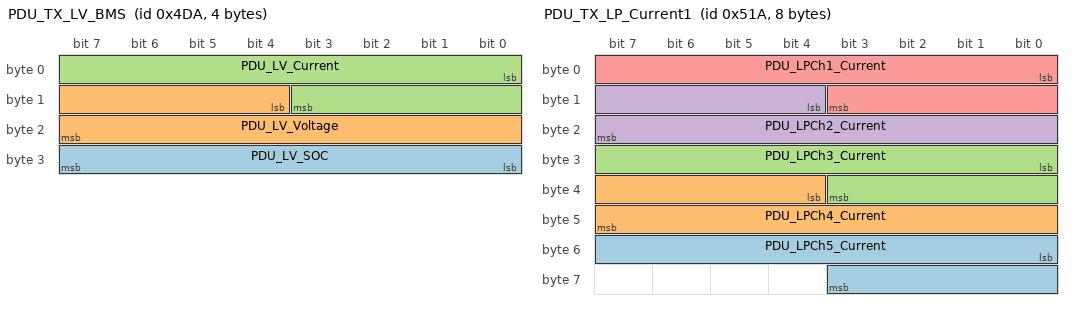
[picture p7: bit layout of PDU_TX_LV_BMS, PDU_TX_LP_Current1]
BO_ 1242 PDU_TX_LV_BMS: 4 PDU
 SG_ PDU_LV_SOC : 24|8@1- (1,0) [0|100] "%" Vector__XXX
 SG_ PDU_LV_Voltage : 12|12@1+ (0.01,0) [0|40.95] "V" Vector__XXX
 SG_ PDU_LV_Current : 0|12@1+ (0.01,0) [0|40.95] "A" Vector__XXX

BO_ 1306 PDU_TX_LP_Current1: 8 PDU
 SG_ PDU_LPCh5_Current : 48|12@1+ (0.002,0) [0|8.19] "A"  SensorF
 SG_ PDU_LPCh4_Current : 36|12@1+ (0.002,0) [0|8.19] "A"  SensorF
 SG_ PDU_LPCh3_Current : 24|12@1+ (0.002,0) [0|8.19] "A"  SensorF
 SG_ PDU_LPCh2_Current : 12|12@1+ (0.002,0) [0|8.19] "A"  SensorF
 SG_ PDU_LPCh1_Current : 0|12@1+ (0.002,0) [0|8.19] "A"  SensorF

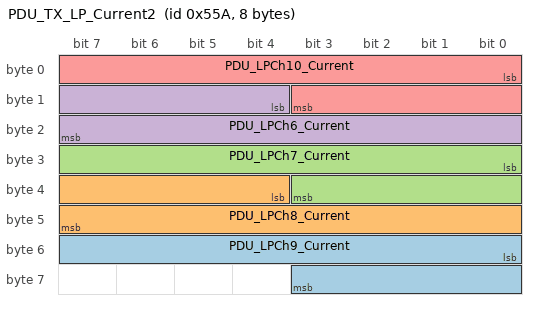
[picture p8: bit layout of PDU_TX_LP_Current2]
BO_ 1370 PDU_TX_LP_Current2: 8 PDU
 SG_ PDU_LPCh9_Current : 48|12@1+ (0.002,0) [0|8.19] "A"  SensorF
 SG_ PDU_LPCh8_Current : 36|12@1+ (0.002,0) [0|8.19] "A"  SensorF
 SG_ PDU_LPCh7_Current : 24|12@1+ (0.002,0) [0|8.19] "A"  SensorF
 SG_ PDU_LPCh6_Current : 12|12@1+ (0.002,0) [0|8.19] "A"  SensorF
 SG_ PDU_LPCh10_Current : 0|12@1+ (0.002,0) [0|8.19] "A"  SensorF

BO_ 1434 PDU_SDO_Resp: 8 PDU
 SG_ PDU_OD_CoolingPumpEnabled m2816 : 16|8@1+ (1,0) [0|255] ""  TelemetryNode
 SG_ PDU_OD_LedCommands m2562 : 16|16@1+ (1,0) [0|65535] ""  TelemetryNode
 SG_ PDU_OD_projectXXEnabled m2560 : 16|8@1+ (1,0) [0|255] ""  TelemetryNode
 SG_ PDU_OD_watchdogTimeout m2306 : 16|16@1+ (1,0) [0|65535] "ms"  TelemetryNode
 SG_ PDU_OD_statusSendInterval m2305 : 16|16@1+ (1,0) [0|65535] "ms"  TelemetryNode
 SG_ PDU_OD_currentReadInterval m2304 : 16|16@1+ (1,0) [0|65535] "ms"  TelemetryNode
 SG_ PDU_OD_batteryOvercurrent m2128 : 16|16@1+ (0.01,0) [0|655.35] "A"  TelemetryNode
 SG_ PDU_OD_overTempCritical m2051 : 16|16@1+ (0.1,0) [0|6553.5] "degrees"  TelemetryNode
 SG_ PDU_OD_overTempWarn m2050 : 16|16@1+ (0.1,0) [0|6553.5] "degrees"  TelemetryNode
 SG_ PDU_OD_batterVoltageCritical m2049 : 16|16@1+ (0.01,0) [0|655.35] "V"  TelemetryNode
 SG_ PDU_OD_batterVoltageLow m2048 : 16|16@1+ (0.01,0) [0|655.35] "V"  TelemetryNode
 SG_ PDU_OD_CAN2_DelayedTxMessages m1129 : 16|24@1+ (1,0) [0|16777215] ""  TelemetryNode
 SG_ PDU_OD_CAN2_ErrorStatus m1128 : 16|8@1+ (1,0) [0|255] ""  TelemetryNode
 SG_ PDU_OD_CAN2_DiscardedTxMessages m1127 : 16|24@1+ (1,0) [0|16777215] ""  TelemetryNode
 SG_ PDU_OD_CAN2_Status m1126 : 16|8@1+ (1,0) [0|255] ""  TelemetryNode
 SG_ PDU_OD_CAN2_Baudrate m1124 : 16|16@1+ (1,0) [125|1000] "kbps"  TelemetryNode
 SG_ PDU_OD_CAN2_autoErrorReset m1123 : 16|8@1+ (1,0) [0|255] ""  TelemetryNode
 SG_ PDU_OD_CAN2_lastErrorCode m1122 : 16|32@1+ (1,0) [0|4294967295] ""  TelemetryNode
 SG_ PDU_OD_CAN2_RxErrCnt m1121 : 16|8@1+ (1,0) [0|255] ""  TelemetryNode
 SG_ PDU_OD_CAN2_TxErrCnt m1120 : 16|8@1+ (1,0) [0|255] ""  TelemetryNode
 SG_ PDU_OD_CAN1_DelayedTxMessages m1113 : 16|24@1+ (1,0) [0|16777215] ""  TelemetryNode
 SG_ PDU_OD_CAN1_ErrorStatus m1112 : 16|8@1+ (1,0) [0|255] ""  TelemetryNode
 SG_ PDU_OD_CAN1_DiscardedTxMessages m1111 : 16|24@1+ (1,0) [0|16777215] ""  TelemetryNode
 SG_ PDU_OD_CAN1_Status m1110 : 16|8@1+ (1,0) [0|255] ""  TelemetryNode
 SG_ PDU_OD_CAN1_Baudrate m1108 : 16|16@1+ (1,0) [125|1000] "kbps"  TelemetryNode
 SG_ PDU_OD_CAN1_autoErrorReset m1107 : 16|8@1+ (1,0) [0|255] ""  TelemetryNode
 SG_ PDU_OD_CAN1_lastErrorCode m1106 : 16|32@1+ (1,0) [0|4294967295] ""  TelemetryNode
 SG_ PDU_OD_CAN1_RxErrCnt m1105 : 16|8@1+ (1,0) [0|255] ""  TelemetryNode
 SG_ PDU_OD_CAN1_TxErrCnt m1104 : 16|8@1+ (1,0) [0|255] ""  TelemetryNode
 SG_ PDU_OD_BuildTime m1073 : 16|24@1+ (1,0) [0|16777215] ""  TelemetryNode
 SG_ PDU_OD_BuildDate m1072 : 16|32@1+ (1,0) [0|4294967295] ""  TelemetryNode
 SG_ PDU_OD_ChipUID2 m1057 : 16|48@1+ (1,0) [0|281474976710655] ""  TelemetryNode
 SG_ PDU_OD_ChipUID1 m1056 : 16|48@1+ (1,0) [0|281474976710655] ""  TelemetryNode
 SG_ PDU_OD_SdcOut m1046 : 16|8@1+ (1,0) [0|255] ""  TelemetryNode
 SG_ PDU_OD_SdcIn m1045 : 16|8@1+ (1,0) [0|255] ""  TelemetryNode
 SG_ PDU_OD_runtime m1044 : 16|24@1+ (1,0) [0|16777215] "ms"  TelemetryNode
 SG_ PDU_OD_InputVoltage m1043 : 16|16@1+ (0.001,0) [0|65.535] "V"  TelemetryNode
 SG_ PDU_OD_BoardTemp m1042 : 16|16@1+ (0.01,-30) [-30|625.35] "°C"  TelemetryNode
 SG_ PDU_OD_MemFree m1041 : 16|16@1+ (4,0) [0|262140] "bytes"  TelemetryNode
 SG_ PDU_OD_CpuUsage m1040 : 16|8@1+ (0.5,0) [0|100] "%"  TelemetryNode
 SG_ PDU_OD_OdEntrySendInterval m33 : 16|16@1+ (1,0) [0|65535] "ms"  TelemetryNode
 SG_ PDU_OD_SendOdOnBootup m32 : 16|8@1+ (1,0) [0|255] ""  TelemetryNode
 SG_ PDU_OD_HeartbeatInterval m16 : 16|16@1+ (1,0) [0|65535] "ms"  TelemetryNode
 SG_ PDU_OD_DbcVersion m5 : 16|16@1+ (1,0) [0|65535] ""  TelemetryNode
 SG_ PDU_OD_StackVersion m4 : 16|16@1+ (1,0) [0|65535] ""  TelemetryNode
 SG_ PDU_OD_ProtocolVersion m3 : 16|16@1+ (1,0) [0|65535] ""  TelemetryNode
 SG_ PDU_OD_NodeStatus m2 : 16|8@1+ (1,0) [0|255] ""  TelemetryNode
 SG_ PDU_OD_NodeID m1 : 16|8@1+ (1,0) [0|255] ""  TelemetryNode
 SG_ PDU_SDO_RespCode : 12|4@1+ (1,0) [0|0] ""  TelemetryNode
 SG_ PDU_SDO_ID M : 0|12@1+ (1,0) [0|4095] ""  TelemetryNode

CM_ BO_ 1474 "DO NOT CHANGE ANYTHING HERE!
SDO Request Upload to node SensorR with Node-ID 0x2";
CM_ SG_ 1474 SensorR_OD_posDeviationOptic "allowed deviation of position measurment of optical sensor";
CM_ SG_ 1474 SensorR_OD_posDeviationEncoder "allowed deviation of position measurment of encoders";
CM_ SG_ 1474 SensorR_OD_velDeviationOptic "allowed deviation of velocity measurment of optical sensor";
CM_ SG_ 1474 SensorR_OD_velDeviationEncoder "allowed deviation of velocity measurment of encoders";
CM_ SG_ 1474 SensorR_OD_accDeviation "allowed deviation of IMUs";
CM_ SG_ 1474 SensorR_OD_EnableSignalGene_0000 "enable signalgeneration for testing SE";
CM_ SG_ 1474 SensorR_OD_PositionGlitch "allowed difference in m between estimated pod position and stripe position";
CM_ SG_ 1474 SensorR_OD_ReflectorDistance "distance between 2 reflectors in m";
CM_ SG_ 1474 SensorR_OD_StripeMode "0 means left, 1 means right, 2 means both";
CM_ SG_ 1474 SensorR_OD_opc_lowpass_TcI "timeconstant of PT1 for current adjustment of OPC";
CM_ SG_ 1474 SensorR_OD_opc_lowpass_Tcf "timeconstant of PT1 for frequency adjustment of OPC";
CM_ SG_ 1474 SensorR_OD_opc_F_decrease "parameter of how quickly force is decreased while breaking";
CM_ SG_ 1474 SensorR_OD_opc_v_threshold "Velocity when to reduce to current. FIXME Add parameter how much to reduce the current.";
CM_ SG_ 1474 SensorR_OD_opc_v_max "Velocity when to stop accelerating.";
CM_ SG_ 1474 SensorR_OD_opc_T_acc "Time to accelerate.";
CM_ SG_ 1474 SensorR_OD_opc_F_max "Maximum force to set for acceleration. (Is internally used as a maximum current.)";
CM_ SG_ 1474 SensorR_OD_opc_t_run_max "Max time to check the flip flop";
CM_ SG_ 1474 SensorR_OD_opc_brakeFlag "Manual setting of brakes flag.";
CM_ SG_ 1474 SensorR_OD_DebugCVOPCfreq "Debugging";
CM_ SG_ 1474 SensorR_OD_DebugCascadedIreq "Debugging";
CM_ SG_ 1474 SensorR_OD_opc_ratelimiter_f "Rate Limiter Freq.";
CM_ SG_ 1474 SensorR_OD_maxRunDistance "Estimated run length based on the velocity profile.";
CM_ SG_ 1474 SensorR_OD_FinishedDelay "Time to stay in launching mode after end of trajectory..";
CM_ SG_ 1474 SensorR_OD_Current4Stopping "Current set for stopping (in A).";
CM_ SG_ 1474 SensorR_OD_AdaptModelByCurrent "Select whether to use the measured current to adapt the model.";
CM_ SG_ 1474 SensorR_OD_CVOPCTcFreq "Lowpass filter constant of F_req.";
CM_ SG_ 1474 SensorR_OD_CVOPCImin "Minimum current for current varied OPC.";
CM_ SG_ 1474 SensorR_OD_CascadedKpDecrea_0000 "Specify the factor to decreae current (in A/s).";
CM_ SG_ 1474 SensorR_OD_CascadedKpIncrea_0000 "Specify the factor to increase current (in A/s).";
CM_ SG_ 1474 SensorR_OD_CascadedFreqCurUpdate "Specify how often to update the required current in the cascaded control.";
CM_ SG_ 1474 SensorR_OD_CascadedMaxSetFo_0000 "Specify the max force delta when no current is modified.";
CM_ SG_ 1474 SensorR_OD_CurrentForConsta_0000 "Current for cruising (in FFCC).";
CM_ SG_ 1474 SensorR_OD_AccAtCurrentMeasured "Acceleration with a specified constant current (Default 230 / 3=76.7) (FFCVOPC).";
CM_ SG_ 1474 SensorR_OD_CVOPCHystereseF "Specify the Hysterese amplitude when to change for acc or dec.";
CM_ SG_ 1474 SensorR_OD_CVOPCReduceCurre_0000 "Specify by which factor to reduce the const current while cruising with const current control.";
CM_ SG_ 1474 SensorR_OD_CVOPCDeltaVelHig_0000 "Specify at which absolute velocity error the higher current should be selected (although v_req = const).";
CM_ SG_ 1474 SensorR_OD_CVOPCSmoothingDe_0000 "Specify at which velocity deviation stronger low pass filtering should end. FIXME Do not use a hard boundary.";
CM_ SG_ 1474 SensorR_OD_CVOPCTcI "Lowpass filter constant of current (for CVOPC and FFCVOPC).";
CM_ SG_ 1474 SensorR_OD_CVOPCTcf "Lowpass filter constant of frequency.";
CM_ SG_ 1474 SensorR_OD_CVOPCImax "Maximum current for current varied OPC.";
CM_ SG_ 1474 SensorR_OD_VelocityController "Select which velocity controller to choose (CC ConstantCurrent, CVFF CurrentVariedFeedForward, CVFB VariedCurrentFeedBack, CAS Cascaded)";
CM_ SG_ 1474 SensorR_OD_TC_f "Time constant for the required frequency.";
CM_ SG_ 1474 SensorR_OD_TC_I "Time constant for the required current.";
CM_ SG_ 1474 SensorR_OD_EstimatedRunLength "Estimated run length based on the velocity profile.";
CM_ SG_ 1474 SensorR_OD_RunProfile_V4 "Velocity for the fith point in the velocity profile.";
CM_ SG_ 1474 SensorR_OD_RunProfile_T4 "Time for the fith point in the velocity profile.";
CM_ SG_ 1474 SensorR_OD_RunProfile_V3 "Velocity for the forth point in the velocity profile.";
CM_ SG_ 1474 SensorR_OD_RunProfile_T3 "Time for the forth point in the velocity profile.";
CM_ SG_ 1474 SensorR_OD_RunProfile_V2 "Velocity for the third point in the velocity profile.";
CM_ SG_ 1474 SensorR_OD_RunProfile_T2 "Time for the third point in the velocity profile.";
CM_ SG_ 1474 SensorR_OD_RunProfile_V1 "Velocity for the second point in the velocity profile.";
CM_ SG_ 1474 SensorR_OD_RunProfile_T1 "Time for the second point in the velocity profile.";
CM_ SG_ 1474 SensorR_OD_RunProfile_V0 "Velocity for the first point in the velocity profile.";
CM_ SG_ 1474 SensorR_OD_RunProfile_T0 "Time for the first point in the velocity profile.";
CM_ SG_ 1474 SensorR_OD_SetFinish "Manual setting of finished flag.";
CM_ SG_ 1474 SensorR_OD_RunMode "Whether to do dynamic run (0), levitation (1) or manual control (2).";
CM_ SG_ 1474 SensorR_OD_VdcReduceFactor "Factor to tune Vdc.";
CM_ SG_ 1474 SensorR_OD_MaxRequiredVelocity "Maximum required velocity the OPC accepts.";
CM_ SG_ 1474 SensorR_OD_WarningThreshhol_0000 "Time where deviation from the required velocity is considered.";
CM_ SG_ 1474 SensorR_OD_MaxCtrlErrorDuration "Time where deviation from the required velocity is considered. (Done by high level control.) FIXME";
CM_ SG_ 1474 SensorR_OD_MaxCtrlError "Maximum deviation from the required velocity for a specified time. (Done by high level control.) FIXME";
CM_ SG_ 1474 SensorR_OD_FminCtrl "Force saturation in OPC (lower boundary). Scaled by (-1). 922 is maximum.";
CM_ SG_ 1474 SensorR_OD_FmaxCtrl "Force saturation in OPC (upper boundary). 1004 is maximum.";
CM_ SG_ 1474 SensorR_OD_PodMass "Mass of pod.";
CM_ SG_ 1474 SensorR_OD_CurrentReq "Required current for LIM (AC RMS coil current controlled by current controller).";
CM_ SG_ 1474 SensorR_OD_CtrlMode "Whether to use V-control (0) or I-control (1).";
CM_ SG_ 1474 SensorR_OD_OpcKi "Integrator gain for OPC.";
CM_ SG_ 1474 SensorR_OD_OpcKp "Product gain for OPC.";
CM_ SG_ 1474 SensorR_OD_ExecTimeReadSensors "Execution time of the sensor readings in milliseconds.";
CM_ SG_ 1474 SensorR_OD_ExecTimeControl "Execution time of the control in milliseconds.";
CM_ SG_ 1474 SensorR_OD_ExecTimeStateEst "Execution time of the State Estimation in milliseconds.";
CM_ SG_ 1474 SensorR_OD_ExecTimeOverall "Execution time of the whole TrajectoryControl task.";
CM_ SG_ 1474 SensorR_OD_IMU3_Temperature "Internal temperature of IMU3.";
CM_ SG_ 1474 SensorR_OD_IMU2_Temperature "Internal temperature of IMU2.";
CM_ SG_ 1474 SensorR_OD_IMU1_Temperature "Internal temperature of IMU1.";
CM_ SG_ 1474 SensorR_OD_IMU_number "Number of IMUs that are online.";
CM_ SG_ 1474 SensorR_OD_EncoderResetPosition "Reset the position of the encoder to zero.";
CM_ SG_ 1474 SensorR_OD_EncoderWheelDiameter "Diameter of the encoder wheel in mm.";
CM_ SG_ 1474 SensorR_OD_samplingInterval "Sensor sampling interval in ms.";
CM_ SG_ 1474 SensorR_OD_CAN2_DelayedTxMe_0000 "Number of delayed TX messages on CAN2 because no messagebox was free.";
CM_ SG_ 1474 SensorR_OD_CAN2_ErrorStatus "Internal error status (e.g. Error active, Error passive, Bus Off)";
CM_ SG_ 1474 SensorR_OD_CAN2_DiscardedTx_0000 "Number of discarded TX messages on CAN2 because all messageboxes were full";
CM_ SG_ 1474 SensorR_OD_CAN2_Status "Status of CAN2.";
CM_ SG_ 1474 SensorR_OD_CAN2_Baudrate "Baudrate of CAN.";
CM_ SG_ 1474 SensorR_OD_CAN2_autoErrorReset "Automatic reset of errors.";
CM_ SG_ 1474 SensorR_OD_CAN2_lastErrorCode "Last error code.";
CM_ SG_ 1474 SensorR_OD_CAN2_RxErrCnt "Receive error count of CAN1.";
CM_ SG_ 1474 SensorR_OD_CAN2_TxErrCnt "Transmit error count of CAN1.";
CM_ SG_ 1474 SensorR_OD_CAN1_DelayedTxMe_0000 "Number of delayed TX messages on CAN1 because no messagebox was free.";
CM_ SG_ 1474 SensorR_OD_CAN1_ErrorStatus "Internal error status (e.g. Error active, Error passive, Bus Off)";
CM_ SG_ 1474 SensorR_OD_CAN1_DiscardedTx_0000 "Number of discarded TX messages on CAN1 because all messageboxes were full";
CM_ SG_ 1474 SensorR_OD_CAN1_Status "Status of CAN1.";
CM_ SG_ 1474 SensorR_OD_CAN1_Baudrate "Baudrate of CAN.";
CM_ SG_ 1474 SensorR_OD_CAN1_autoErrorReset "Automatic reset of errors.";
CM_ SG_ 1474 SensorR_OD_CAN1_lastErrorCode "Last error code.";
CM_ SG_ 1474 SensorR_OD_CAN1_RxErrCnt "Receive error count of CAN1.";
CM_ SG_ 1474 SensorR_OD_CAN1_TxErrCnt "Transmit error count of CAN1.";
CM_ SG_ 1474 SensorR_OD_BuildTime "Software build time in the format HHMMSS.";
CM_ SG_ 1474 SensorR_OD_BuildDate "Software build date in the format YYYYMMDD.";
CM_ SG_ 1474 SensorR_OD_ChipUID2 "Seccond part of unique ID of microcontroller.";
CM_ SG_ 1474 SensorR_OD_ChipUID1 "First part of unique ID of microcontroller.";
CM_ SG_ 1474 SensorR_OD_SdcOut "Measurement of Shutdown Circuit Output";
CM_ SG_ 1474 SensorR_OD_SdcIn "Measurement of Shutdown Circuit Input";
CM_ SG_ 1474 SensorR_OD_runtime "Runtime of chip in milliseconds.";
CM_ SG_ 1474 SensorR_OD_InputVoltage "Board supply voltage.";
CM_ SG_ 1474 SensorR_OD_BoardTemp "Temperature of board";
CM_ SG_ 1474 SensorR_OD_MemFree "Free memory in bytes.";
CM_ SG_ 1474 SensorR_OD_CpuUsage "Current CPU usage in %.";
CM_ SG_ 1474 SensorR_OD_OdEntrySendInterval "Interval for sending all readable OD entries. Sending is disabled if less than 5 ms.";
CM_ SG_ 1474 SensorR_OD_SendOdOnBootup "Whether to send all OD entries on bootup.";
CM_ SG_ 1474 SensorR_OD_HeartbeatInterval "Heartbeat Interval in milliseconds.";
CM_ SG_ 1474 SensorR_OD_DbcVersion "CANzero DBC version.";
CM_ SG_ 1474 SensorR_OD_StackVersion "CANzero stack version.";
CM_ SG_ 1474 SensorR_OD_ProtocolVersion "CANzero Protocol Version.";
CM_ SG_ 1474 SensorR_OD_NodeStatus "State of the node.";
CM_ SG_ 1474 SensorR_OD_NodeID "CANzero Node-ID.";
CM_ SG_ 1474 SensorR_SDO_ID "Specifies SDO-ID of SensorR";
CM_ BO_ 1538 "DO NOT CHANGE ANYTHING HERE!
SDO Request Download from node SensorR with Node-ID 0x2";
CM_ SG_ 1538 SensorR_SDO_ID "Specifies SDO-ID of SensorR";
CM_ BO_ 1794 "Heartbeat of node SensorR with Node-ID 0x2";
CM_ SG_ 1794 SensorR_NodeState "Heartbeat status of node SensorR";
CM_ BO_ 1858 "Bootloader transmit from node SensorR with Node-ID 0x2";
CM_ BO_ 1922 "Bootloader receive by node SensorR with Node-ID 0x2";
CM_ BO_ 145 "Emergency message of node BrakeF with Node-ID 0x11";
CM_ SG_ 145 BrakeF_E5_retractUnsuccesful_ope "Instruction to retract was received, but the SDC is detected to be open";
CM_ SG_ 145 BrakeF_E4_retractUnsuccesful_not "Instruction to retract was received, but the ECU is not enabled";
CM_ SG_ 145 BrakeF_E3_retractUnsuccesful_err "Instruction to retract was received, but an error flag inhibited retraction";
CM_ SG_ 145 BrakeF_E2_commWatchdogTimeout "Communication Watchdog timeout. It took more than the time set to receive a new message from the state machine";
CM_ SG_ 145 BrakeF_E1_pressureTooLow "Pressure tank has a lower value than the provided LowerControlLimit";
CM_ SG_ 145 BrakeF_E0_pressureTooHigh "Pressure tank has a higher value than the provided UpperControlLimit";
CM_ SG_ 145 BrakeF_W3_externalError "SDC reading indicates it's open, but there's no internal error in the ECU";
CM_ SG_ 145 BrakeF_W2_enableWithAnError "The ECU was enabled with an error flag";
CM_ SG_ 145 BrakeF_W1_highPressureRetracting "Pressure higher than desired was measured in the acting chamber";
CM_ SG_ 145 BrakeF_W0_highPressureActingCham "Pressure higher than desired was measured in the acting chamber";
CM_ BO_ 401 "Transmit PDO 1 of node BrakeF with Node-ID 0x11";
CM_ SG_ 401 BrakeF_TX_SDC_Input "Sends the current value of the SDC received by BrakeF.
";
CM_ SG_ 401 BrakeF_TX_ErrorFlag "Error status of BrakeF.";
CM_ SG_ 401 BrakeF_TX_Enabled "Enable status of BrakeF.";
CM_ SG_ 401 BrakeF_TX_Status "Status signal of BrakeF.";
CM_ BO_ 465 "Receive PDO 1 of node BrakeF with Node-ID 0x11";
CM_ SG_ 465 BrakeF_RX_Engage "Engage signal for BrakeF.";
CM_ SG_ 465 BrakeF_RX_Enable "Enable signal for BrakeF.";
CM_ SG_ 465 BrakeF_RX_ErrorReset "Error reset signal for BrakeF.";
CM_ BO_ 529 "Transmit PDO 2 of node BrakeF with Node-ID 0x11";
CM_ BO_ 593 "Receive PDO 2 of node BrakeF with Node-ID 0x11";
CM_ BO_ 657 "Transmit PDO 3 of node BrakeF with Node-ID 0x11";
CM_ BO_ 721 "Receive PDO 3 of node BrakeF with Node-ID 0x11";
CM_ BO_ 785 "Transmit PDO 4 of node BrakeF with Node-ID 0x11";
CM_ BO_ 849 "Receive PDO 4 of node BrakeF with Node-ID 0x11";
CM_ BO_ 913 "Transmit PDO 5 of node BrakeF with Node-ID 0x11";
CM_ BO_ 977 "Transmit PDO 6 of node BrakeF with Node-ID 0x11";
CM_ BO_ 1105 "Transmit PDO 8 of node BrakeF with Node-ID 0x11";
CM_ BO_ 1169 "Transmit PDO 9 of node BrakeF with Node-ID 0x11";
CM_ BO_ 1233 "Transmit PDO 10 of node BrakeF with Node-ID 0x11";
CM_ BO_ 1297 "Transmit PDO 11 of node BrakeF with Node-ID 0x11";
CM_ BO_ 1361 "Transmit PDO 12 of node BrakeF with Node-ID 0x11";
CM_ BO_ 1425 "DO NOT CHANGE ANYTHING HERE!
SDO Response of node BrakeF with Node-ID 0x11";
CM_ SG_ 1425 BrakeF_OD_BrakeStatus "State of the Brakes";
CM_ SG_ 1425 BrakeF_OD_CoolingPressure "Cooling cycle Pressure";
CM_ SG_ 1425 BrakeF_OD_valveUpperTolerance "Tolerance of the lower pressure pneumatic circuit";
CM_ SG_ 1425 BrakeF_OD_commWatchdog "Max. number of ms to receive a new message";
CM_ SG_ 1425 BrakeF_OD_counterLimit "Number of cycles in the loop to measure pressure once";
CM_ SG_ 1425 BrakeF_OD_delay "Delay used in every cycle of the loop.";
CM_ SG_ 1425 BrakeF_OD_tankUpperControlLimit "Maximum pressure of tank in bar.";
CM_ SG_ 1425 BrakeF_OD_tankLowerControlLimit "Minimum pressure of tank in bar.";
CM_ SG_ 1425 BrakeF_OD_CAN2_DelayedTxMessages "Number of delayed TX messages on CAN2 because no messagebox was free.";
CM_ SG_ 1425 BrakeF_OD_CAN2_ErrorStatus "Internal error status (e.g. Error active, Error passive, Bus Off)";
CM_ SG_ 1425 BrakeF_OD_CAN2_DiscardedTxMessag "Number of discarded TX messages on CAN2 because all messageboxes were full";
CM_ SG_ 1425 BrakeF_OD_CAN2_Status "Status of CAN2.";
CM_ SG_ 1425 BrakeF_OD_CAN2_Baudrate "Baudrate of CAN.";
CM_ SG_ 1425 BrakeF_OD_CAN2_autoErrorReset "Automatic reset of errors.";
CM_ SG_ 1425 BrakeF_OD_CAN2_lastErrorCode "Last error code.";
CM_ SG_ 1425 BrakeF_OD_CAN2_RxErrCnt "Receive error count of CAN1.";
CM_ SG_ 1425 BrakeF_OD_CAN2_TxErrCnt "Transmit error count of CAN1.";
CM_ SG_ 1425 BrakeF_OD_CAN1_DelayedTxMessages "Number of delayed TX messages on CAN1 because no messagebox was free.";
CM_ SG_ 1425 BrakeF_OD_CAN1_ErrorStatus "Internal error status (e.g. Error active, Error passive, Bus Off)";
CM_ SG_ 1425 BrakeF_OD_CAN1_DiscardedTxMessag "Number of discarded TX messages on CAN1 because all messageboxes were full";
CM_ SG_ 1425 BrakeF_OD_CAN1_Status "Status of CAN1.";
CM_ SG_ 1425 BrakeF_OD_CAN1_Baudrate "Baudrate of CAN.";
CM_ SG_ 1425 BrakeF_OD_CAN1_autoErrorReset "Automatic reset of errors.";
CM_ SG_ 1425 BrakeF_OD_CAN1_lastErrorCode "Last error code.";
CM_ SG_ 1425 BrakeF_OD_CAN1_RxErrCnt "Receive error count of CAN1.";
CM_ SG_ 1425 BrakeF_OD_CAN1_TxErrCnt "Transmit error count of CAN1.";
CM_ SG_ 1425 BrakeF_OD_BuildTime "Software build time in the format HHMMSS.";
CM_ SG_ 1425 BrakeF_OD_BuildDate "Software build date in the format YYYYMMDD.";
CM_ SG_ 1425 BrakeF_OD_ChipUID2 "Seccond part of unique ID of microcontroller.";
CM_ SG_ 1425 BrakeF_OD_ChipUID1 "First part of unique ID of microcontroller.";
CM_ SG_ 1425 BrakeF_OD_SdcOut "Measurement of Shutdown Circuit Output";
CM_ SG_ 1425 BrakeF_OD_SdcIn "Measurement of Shutdown Circuit Input";
CM_ SG_ 1425 BrakeF_OD_runtime "Runtime of chip in milliseconds.";
CM_ SG_ 1425 BrakeF_OD_InputVoltage "Board supply voltage.";
CM_ SG_ 1425 BrakeF_OD_BoardTemp "Temperature of board";
CM_ SG_ 1425 BrakeF_OD_MemFree "Free memory in bytes.";
CM_ SG_ 1425 BrakeF_OD_CpuUsage "Current CPU usage in %.";
CM_ SG_ 1425 BrakeF_OD_OdEntrySendInterval "Interval for sending all readable OD entries. Sending is disabled if less than 5 ms.";
CM_ SG_ 1425 BrakeF_OD_SendOdOnBootup "Whether to send all OD entries on bootup.";
CM_ SG_ 1425 BrakeF_OD_HeartbeatInterval "Heartbeat Interval in milliseconds.";
CM_ SG_ 1425 BrakeF_OD_DbcVersion "CANzero DBC version.";
CM_ SG_ 1425 BrakeF_OD_StackVersion "CANzero stack version.";
CM_ SG_ 1425 BrakeF_OD_ProtocolVersion "CANzero Protocol Version.";
CM_ SG_ 1425 BrakeF_OD_NodeStatus "State of the node.";
CM_ SG_ 1425 BrakeF_OD_NodeID "CANzero Node-ID.";
CM_ SG_ 1425 BrakeF_SDO_RespCode "Response code of SDO access.";
CM_ SG_ 1425 BrakeF_SDO_ID "Specifies SDO-ID of BrakeF";
CM_ BO_ 1489 "DO NOT CHANGE ANYTHING HERE!
SDO Request Upload to node BrakeF with Node-ID 0x11";
CM_ SG_ 1489 BrakeF_OD_BrakeStatus "State of the Brakes";
CM_ SG_ 1489 BrakeF_OD_CoolingPressure "Cooling cycle Pressure";
CM_ SG_ 1489 BrakeF_OD_valveUpperTolerance "Tolerance of the lower pressure pneumatic circuit";
CM_ SG_ 1489 BrakeF_OD_commWatchdog "Max. number of ms to receive a new message";
CM_ SG_ 1489 BrakeF_OD_counterLimit "Number of cycles in the loop to measure pressure once";
CM_ SG_ 1489 BrakeF_OD_delay "Delay used in every cycle of the loop.";
CM_ SG_ 1489 BrakeF_OD_tankUpperControlLimit "Maximum pressure of tank in bar.";
CM_ SG_ 1489 BrakeF_OD_tankLowerControlLimit "Minimum pressure of tank in bar.";
CM_ SG_ 1489 BrakeF_OD_CAN2_DelayedTxMessages "Number of delayed TX messages on CAN2 because no messagebox was free.";
CM_ SG_ 1489 BrakeF_OD_CAN2_ErrorStatus "Internal error status (e.g. Error active, Error passive, Bus Off)";
CM_ SG_ 1489 BrakeF_OD_CAN2_DiscardedTxM_0000 "Number of discarded TX messages on CAN2 because all messageboxes were full";
CM_ SG_ 1489 BrakeF_OD_CAN2_Status "Status of CAN2.";
CM_ SG_ 1489 BrakeF_OD_CAN2_Baudrate "Baudrate of CAN.";
CM_ SG_ 1489 BrakeF_OD_CAN2_autoErrorReset "Automatic reset of errors.";
CM_ SG_ 1489 BrakeF_OD_CAN2_lastErrorCode "Last error code.";
CM_ SG_ 1489 BrakeF_OD_CAN2_RxErrCnt "Receive error count of CAN1.";
CM_ SG_ 1489 BrakeF_OD_CAN2_TxErrCnt "Transmit error count of CAN1.";
CM_ SG_ 1489 BrakeF_OD_CAN1_DelayedTxMessages "Number of delayed TX messages on CAN1 because no messagebox was free.";
CM_ SG_ 1489 BrakeF_OD_CAN1_ErrorStatus "Internal error status (e.g. Error active, Error passive, Bus Off)";
CM_ SG_ 1489 BrakeF_OD_CAN1_DiscardedTxM_0000 "Number of discarded TX messages on CAN1 because all messageboxes were full";
CM_ SG_ 1489 BrakeF_OD_CAN1_Status "Status of CAN1.";
CM_ SG_ 1489 BrakeF_OD_CAN1_Baudrate "Baudrate of CAN.";
CM_ SG_ 1489 BrakeF_OD_CAN1_autoErrorReset "Automatic reset of errors.";
CM_ SG_ 1489 BrakeF_OD_CAN1_lastErrorCode "Last error code.";
CM_ SG_ 1489 BrakeF_OD_CAN1_RxErrCnt "Receive error count of CAN1.";
CM_ SG_ 1489 BrakeF_OD_CAN1_TxErrCnt "Transmit error count of CAN1.";
CM_ SG_ 1489 BrakeF_OD_BuildTime "Software build time in the format HHMMSS.";
CM_ SG_ 1489 BrakeF_OD_BuildDate "Software build date in the format YYYYMMDD.";
CM_ SG_ 1489 BrakeF_OD_ChipUID2 "Seccond part of unique ID of microcontroller.";
CM_ SG_ 1489 BrakeF_OD_ChipUID1 "First part of unique ID of microcontroller.";
CM_ SG_ 1489 BrakeF_OD_SdcOut "Measurement of Shutdown Circuit Output";
CM_ SG_ 1489 BrakeF_OD_SdcIn "Measurement of Shutdown Circuit Input";
CM_ SG_ 1489 BrakeF_OD_runtime "Runtime of chip in milliseconds.";
CM_ SG_ 1489 BrakeF_OD_InputVoltage "Board supply voltage.";
CM_ SG_ 1489 BrakeF_OD_BoardTemp "Temperature of board";
CM_ SG_ 1489 BrakeF_OD_MemFree "Free memory in bytes.";
CM_ SG_ 1489 BrakeF_OD_CpuUsage "Current CPU usage in %.";
CM_ SG_ 1489 BrakeF_OD_OdEntrySendInterval "Interval for sending all readable OD entries. Sending is disabled if less than 5 ms.";
CM_ SG_ 1489 BrakeF_OD_SendOdOnBootup "Whether to send all OD entries on bootup.";
CM_ SG_ 1489 BrakeF_OD_HeartbeatInterval "Heartbeat Interval in milliseconds.";
CM_ SG_ 1489 BrakeF_OD_DbcVersion "CANzero DBC version.";
CM_ SG_ 1489 BrakeF_OD_StackVersion "CANzero stack version.";
CM_ SG_ 1489 BrakeF_OD_ProtocolVersion "CANzero Protocol Version.";
CM_ SG_ 1489 BrakeF_OD_NodeStatus "State of the node.";
CM_ SG_ 1489 BrakeF_OD_NodeID "CANzero Node-ID.";
CM_ SG_ 1489 BrakeF_SDO_ID "Specifies SDO-ID of BrakeF";
CM_ BO_ 1553 "DO NOT CHANGE ANYTHING HERE!
SDO Request Download from node BrakeF with Node-ID 0x11";
CM_ SG_ 1553 BrakeF_SDO_ID "Specifies SDO-ID of BrakeF";
CM_ BO_ 1809 "Heartbeat of node BrakeF with Node-ID 0x11";
CM_ SG_ 1809 BrakeF_NodeState "Heartbeat status of node BrakeF";
CM_ BO_ 1873 "Bootloader transmit from node BrakeF with Node-ID 0x11";
CM_ BO_ 1937 "Bootloader receive by node BrakeF with Node-ID 0x11";
CM_ BO_ 146 "Emergency message of node BrakeR with Node-ID 0x12";
CM_ SG_ 146 BrakeR_E5_retractUnsuccesful_ope "Instruction to retract was received, but the SDC is detected to be open";
CM_ SG_ 146 BrakeR_E4_retractUnsuccesful_not "Instruction to retract was received, but the ECU is not enabled";
CM_ SG_ 146 BrakeR_E3_retractUnsuccesful_err "Instruction to retract was received, but an error flag inhibited retraction";
CM_ SG_ 146 BrakeR_E2_commWatchdogTimeout "Communication Watchdog timeout. It took more than the time set to receive a new message from the state machine";
CM_ SG_ 146 BrakeR_E1_pressureTooLow "Pressure tank has a lower value than the provided LowerControlLimit";
CM_ SG_ 146 BrakeR_E0_pressureTooHigh "Pressure tank has a higher value than the provided UpperControlLimit";
CM_ SG_ 146 BrakeR_W3_externalError "SDC reading indicates it's open, but there's no internal error in the ECU";
CM_ SG_ 146 BrakeR_W2_enableWithAnError "The ECU was enabled with an error flag";
CM_ SG_ 146 BrakeR_W1_highPressureRetracting "Pressure higher than desired was measured in the acting chamber";
CM_ SG_ 146 BrakeR_W0_highPressureActingCham "Pressure higher than desired was measured in the acting chamber";
CM_ BO_ 402 "Transmit PDO 1 of node BrakeR with Node-ID 0x12";
CM_ SG_ 402 BrakeR_TX_SDC_Input "Sends the current value of the SDC received by BrakeR.
";
CM_ SG_ 402 BrakeR_TX_ErrorFlag "Error status of BrakeR.";
CM_ SG_ 402 BrakeR_TX_Enabled "Enable status of BrakeR.";
CM_ SG_ 402 BrakeR_TX_Status "Status signal of BrakeR.";
CM_ BO_ 466 "Receive PDO 1 of node BrakeR with Node-ID 0x12";
CM_ SG_ 466 BrakeR_RX_Engage "Engage signal for BrakeR.";
CM_ SG_ 466 BrakeR_RX_Enable "Enable signal for BrakeR.";
CM_ SG_ 466 BrakeR_RX_ErrorReset "Error reset signal for BrakeR.";
CM_ BO_ 530 "Transmit PDO 2 of node BrakeR with Node-ID 0x12";
CM_ BO_ 594 "Receive PDO 2 of node BrakeR with Node-ID 0x12";
CM_ BO_ 658 "Transmit PDO 3 of node BrakeR with Node-ID 0x12";
CM_ BO_ 722 "Receive PDO 3 of node BrakeR with Node-ID 0x12";
CM_ BO_ 786 "Transmit PDO 4 of node BrakeR with Node-ID 0x12";
CM_ BO_ 850 "Receive PDO 4 of node BrakeR with Node-ID 0x12";
CM_ BO_ 914 "Transmit PDO 5 of node BrakeR with Node-ID 0x12";
CM_ BO_ 978 "Transmit PDO 6 of node BrakeR with Node-ID 0x12";
CM_ BO_ 1042 "Transmit PDO 7 of node BrakeR with Node-ID 0x12";
CM_ BO_ 1106 "Transmit PDO 8 of node BrakeR with Node-ID 0x12";
CM_ BO_ 1170 "Transmit PDO 9 of node BrakeR with Node-ID 0x12";
CM_ BO_ 1234 "Transmit PDO 10 of node BrakeR with Node-ID 0x12";
CM_ BO_ 1298 "Transmit PDO 11 of node BrakeR with Node-ID 0x12";
CM_ BO_ 1362 "Transmit PDO 12 of node BrakeR with Node-ID 0x12";
CM_ BO_ 1426 "DO NOT CHANGE ANYTHING HERE!
SDO Response of node BrakeR with Node-ID 0x12";
CM_ SG_ 1426 BrakeR_OD_valveUpperTolerance "Tolerance of the lower pressure pneumatic circuit";
CM_ SG_ 1426 BrakeR_OD_commWatchdog "Max. number of ms to receive a new message";
CM_ SG_ 1426 BrakeR_OD_counterLimit "Number of cycles in the loop to measure pressure once";
CM_ SG_ 1426 BrakeR_OD_delay "Delay used in every cycle of the loop.";
CM_ SG_ 1426 BrakeR_OD_tankUpperControlLimit "Maximum pressure of tank in bar.";
CM_ SG_ 1426 BrakeR_OD_tankLowerControlLimit "Minimum pressure of tank in bar.";
CM_ SG_ 1426 BrakeR_OD_CAN2_DelayedTxMessages "Number of delayed TX messages on CAN2 because no messagebox was free.";
CM_ SG_ 1426 BrakeR_OD_CAN2_ErrorStatus "Internal error status (e.g. Error active, Error passive, Bus Off)";
CM_ SG_ 1426 BrakeR_OD_CAN2_DiscardedTxMessag "Number of discarded TX messages on CAN2 because all messageboxes were full";
CM_ SG_ 1426 BrakeR_OD_CAN2_Status "Status of CAN2.";
CM_ SG_ 1426 BrakeR_OD_CAN2_Baudrate "Baudrate of CAN.";
CM_ SG_ 1426 BrakeR_OD_CAN2_autoErrorReset "Automatic reset of errors.";
CM_ SG_ 1426 BrakeR_OD_CAN2_lastErrorCode "Last error code.";
CM_ SG_ 1426 BrakeR_OD_CAN2_RxErrCnt "Receive error count of CAN1.";
CM_ SG_ 1426 BrakeR_OD_CAN2_TxErrCnt "Transmit error count of CAN1.";
CM_ SG_ 1426 BrakeR_OD_CAN1_DelayedTxMessages "Number of delayed TX messages on CAN1 because no messagebox was free.";
CM_ SG_ 1426 BrakeR_OD_CAN1_ErrorStatus "Internal error status (e.g. Error active, Error passive, Bus Off)";
CM_ SG_ 1426 BrakeR_OD_CAN1_DiscardedTxMessag "Number of discarded TX messages on CAN1 because all messageboxes were full";
CM_ SG_ 1426 BrakeR_OD_CAN1_Status "Status of CAN1.";
CM_ SG_ 1426 BrakeR_OD_CAN1_Baudrate "Baudrate of CAN.";
CM_ SG_ 1426 BrakeR_OD_CAN1_autoErrorReset "Automatic reset of errors.";
CM_ SG_ 1426 BrakeR_OD_CAN1_lastErrorCode "Last error code.";
CM_ SG_ 1426 BrakeR_OD_CAN1_RxErrCnt "Receive error count of CAN1.";
CM_ SG_ 1426 BrakeR_OD_CAN1_TxErrCnt "Transmit error count of CAN1.";
CM_ SG_ 1426 BrakeR_OD_BuildTime "Software build time in the format HHMMSS.";
CM_ SG_ 1426 BrakeR_OD_BuildDate "Software build date in the format YYYYMMDD.";
CM_ SG_ 1426 BrakeR_OD_ChipUID2 "Seccond part of unique ID of microcontroller.";
CM_ SG_ 1426 BrakeR_OD_ChipUID1 "First part of unique ID of microcontroller.";
CM_ SG_ 1426 BrakeR_OD_SdcOut "Measurement of Shutdown Circuit Output";
CM_ SG_ 1426 BrakeR_OD_SdcIn "Measurement of Shutdown Circuit Input";
CM_ SG_ 1426 BrakeR_OD_runtime "Runtime of chip in milliseconds.";
CM_ SG_ 1426 BrakeR_OD_InputVoltage "Board supply voltage.";
CM_ SG_ 1426 BrakeR_OD_BoardTemp "Temperature of board";
CM_ SG_ 1426 BrakeR_OD_MemFree "Free memory in bytes.";
CM_ SG_ 1426 BrakeR_OD_CpuUsage "Current CPU usage in %.";
CM_ SG_ 1426 BrakeR_OD_OdEntrySendInterval "Interval for sending all readable OD entries. Sending is disabled if less than 5 ms.";
CM_ SG_ 1426 BrakeR_OD_SendOdOnBootup "Whether to send all OD entries on bootup.";
CM_ SG_ 1426 BrakeR_OD_HeartbeatInterval "Heartbeat Interval in milliseconds.";
CM_ SG_ 1426 BrakeR_OD_DbcVersion "CANzero DBC version.";
CM_ SG_ 1426 BrakeR_OD_StackVersion "CANzero stack version.";
CM_ SG_ 1426 BrakeR_OD_ProtocolVersion "CANzero Protocol Version.";
CM_ SG_ 1426 BrakeR_OD_NodeStatus "State of the node.";
CM_ SG_ 1426 BrakeR_OD_NodeID "CANzero Node-ID.";
CM_ SG_ 1426 BrakeR_SDO_RespCode "Response code of SDO access.";
CM_ SG_ 1426 BrakeR_SDO_ID "Specifies SDO-ID of BrakeR";
CM_ BO_ 1490 "DO NOT CHANGE ANYTHING HERE!
SDO Request Upload to node BrakeR with Node-ID 0x12";
CM_ SG_ 1490 BrakeR_OD_valveUpperTolerance "Tolerance of the lower pressure pneumatic circuit";
CM_ SG_ 1490 BrakeR_OD_commWatchdog "Max. number of ms to receive a new message";
CM_ SG_ 1490 BrakeR_OD_counterLimit "Number of cycles in the loop to measure pressure once";
CM_ SG_ 1490 BrakeR_OD_delay "Delay used in every cycle of the loop.";
CM_ SG_ 1490 BrakeR_OD_tankUpperControlLimit "Maximum pressure of tank in bar.";
CM_ SG_ 1490 BrakeR_OD_tankLowerControlLimit "Minimum pressure of tank in bar.";
CM_ SG_ 1490 BrakeR_OD_CAN2_DelayedTxMessages "Number of delayed TX messages on CAN2 because no messagebox was free.";
CM_ SG_ 1490 BrakeR_OD_CAN2_ErrorStatus "Internal error status (e.g. Error active, Error passive, Bus Off)";
CM_ SG_ 1490 BrakeR_OD_CAN2_DiscardedTxM_0000 "Number of discarded TX messages on CAN2 because all messageboxes were full";
CM_ SG_ 1490 BrakeR_OD_CAN2_Status "Status of CAN2.";
CM_ SG_ 1490 BrakeR_OD_CAN2_Baudrate "Baudrate of CAN.";
CM_ SG_ 1490 BrakeR_OD_CAN2_autoErrorReset "Automatic reset of errors.";
CM_ SG_ 1490 BrakeR_OD_CAN2_lastErrorCode "Last error code.";
CM_ SG_ 1490 BrakeR_OD_CAN2_RxErrCnt "Receive error count of CAN1.";
CM_ SG_ 1490 BrakeR_OD_CAN2_TxErrCnt "Transmit error count of CAN1.";
CM_ SG_ 1490 BrakeR_OD_CAN1_DelayedTxMessages "Number of delayed TX messages on CAN1 because no messagebox was free.";
CM_ SG_ 1490 BrakeR_OD_CAN1_ErrorStatus "Internal error status (e.g. Error active, Error passive, Bus Off)";
CM_ SG_ 1490 BrakeR_OD_CAN1_DiscardedTxM_0000 "Number of discarded TX messages on CAN1 because all messageboxes were full";
CM_ SG_ 1490 BrakeR_OD_CAN1_Status "Status of CAN1.";
CM_ SG_ 1490 BrakeR_OD_CAN1_Baudrate "Baudrate of CAN.";
CM_ SG_ 1490 BrakeR_OD_CAN1_autoErrorReset "Automatic reset of errors.";
CM_ SG_ 1490 BrakeR_OD_CAN1_lastErrorCode "Last error code.";
CM_ SG_ 1490 BrakeR_OD_CAN1_RxErrCnt "Receive error count of CAN1.";
CM_ SG_ 1490 BrakeR_OD_CAN1_TxErrCnt "Transmit error count of CAN1.";
CM_ SG_ 1490 BrakeR_OD_BuildTime "Software build time in the format HHMMSS.";
CM_ SG_ 1490 BrakeR_OD_BuildDate "Software build date in the format YYYYMMDD.";
CM_ SG_ 1490 BrakeR_OD_ChipUID2 "Seccond part of unique ID of microcontroller.";
CM_ SG_ 1490 BrakeR_OD_ChipUID1 "First part of unique ID of microcontroller.";
CM_ SG_ 1490 BrakeR_OD_SdcOut "Measurement of Shutdown Circuit Output";
CM_ SG_ 1490 BrakeR_OD_SdcIn "Measurement of Shutdown Circuit Input";
CM_ SG_ 1490 BrakeR_OD_runtime "Runtime of chip in milliseconds.";
CM_ SG_ 1490 BrakeR_OD_InputVoltage "Board supply voltage.";
CM_ SG_ 1490 BrakeR_OD_BoardTemp "Temperature of board";
CM_ SG_ 1490 BrakeR_OD_MemFree "Free memory in bytes.";
CM_ SG_ 1490 BrakeR_OD_CpuUsage "Current CPU usage in %.";
CM_ SG_ 1490 BrakeR_OD_OdEntrySendInterval "Interval for sending all readable OD entries. Sending is disabled if less than 5 ms.";
CM_ SG_ 1490 BrakeR_OD_SendOdOnBootup "Whether to send all OD entries on bootup.";
CM_ SG_ 1490 BrakeR_OD_HeartbeatInterval "Heartbeat Interval in milliseconds.";
CM_ SG_ 1490 BrakeR_OD_DbcVersion "CANzero DBC version.";
CM_ SG_ 1490 BrakeR_OD_StackVersion "CANzero stack version.";
CM_ SG_ 1490 BrakeR_OD_ProtocolVersion "CANzero Protocol Version.";
CM_ SG_ 1490 BrakeR_OD_NodeStatus "State of the node.";
CM_ SG_ 1490 BrakeR_OD_NodeID "CANzero Node-ID.";
CM_ SG_ 1490 BrakeR_SDO_ID "Specifies SDO-ID of BrakeR";
CM_ BO_ 1554 "DO NOT CHANGE ANYTHING HERE!
SDO Request Download from node BrakeR with Node-ID 0x12";
CM_ SG_ 1554 BrakeR_SDO_ID "Specifies SDO-ID of BrakeR";
CM_ BO_ 1810 "Heartbeat of node BrakeR with Node-ID 0x12";
CM_ SG_ 1810 BrakeR_NodeState "Heartbeat status of node BrakeR";
CM_ BO_ 1874 "Bootloader transmit from node BrakeR with Node-ID 0x12";
CM_ BO_ 1938 "Bootloader receive by node BrakeR with Node-ID 0x12";
CM_ BO_ 154 "Emergency message of node PDU with Node-ID 0x1A";
CM_ SG_ 154 PDU_E4_watchdogStateMachine "The watchdog for the state machine timed out.";
CM_ SG_ 154 PDU_E3_batterTempCritical "Temperature limit of the battery reached.";
CM_ SG_ 154 PDU_E2_batteryOvercurrent "Overcurrent limit of the battery reached.";
CM_ SG_ 154 PDU_E1_batterVoltageCritical "Error when battery voltage is getting critical low. Pod will be shut down";
CM_ SG_ 154 PDU_E0_OtherError "Other error.";
CM_ SG_ 154 PDU_W2_batterTempHigh "Warning when battery temperature is rising high";
CM_ SG_ 154 PDU_W1_batterVoltageLow "Warning when battery voltage is getting low";
CM_ SG_ 154 PDU_W0_OtherWarning "Other warning.";
CM_ BO_ 410 "Transmit PDO 1 of node PDU with Node-ID 0x1A";
CM_ SG_ 410 PDU_TX_PEHWEnabled "PE Hardware Enable status signal of PDU.";
CM_ SG_ 410 PDU_TX_ErrorFlag "Error status of PDU.";
CM_ SG_ 410 PDU_TX_Enabled "Enable status of PDU.";
CM_ BO_ 474 "Control message of the PDU sent by the State Machine.";
CM_ SG_ 474 PDU_RX_PEHWEnable "PE Hardware Enable signal of PDU.";
CM_ SG_ 474 PDU_RX_ErrorReset "Error reset signal for PDU.";
CM_ SG_ 474 PDU_RX_Enable "Enable signal for PDU.";
CM_ BO_ 538 "Transmit PDO 2 of node PDU with Node-ID 0x1A";
CM_ BO_ 602 "Dutycycle for the channels of the PDU that support PWM.";
CM_ BO_ 666 "Transmit PDO 3 of node PDU with Node-ID 0x1A";
CM_ BO_ 730 "Receive PDO 3 of node PDU with Node-ID 0x1A";
CM_ BO_ 794 "Transmit PDO 4 of node PDU with Node-ID 0x1A";
CM_ BO_ 858 "Receive PDO 4 of node PDU with Node-ID 0x1A";
CM_ BO_ 922 "Transmit PDO 5 of node PDU with Node-ID 0x1A";
CM_ BO_ 986 "Transmit PDO 6 of node PDU with Node-ID 0x1A";
CM_ BO_ 1050 "Transmit PDO 7 of node PDU with Node-ID 0x1A";
CM_ BO_ 1114 "Transmit PDO 8 of node PDU with Node-ID 0x1A";
CM_ BO_ 1178 "Transmit PDO 9 of node PDU with Node-ID 0x1A";
CM_ BO_ 1242 "Transmit PDO 10 of node PDU with Node-ID 0x1A";
CM_ BO_ 1306 "Transmit PDO 11 of node PDU with Node-ID 0x1A";
CM_ BO_ 1370 "Transmit PDO 12 of node PDU with Node-ID 0x1A";
CM_ BO_ 1434 "DO NOT CHANGE ANYTHING HERE!
SDO Response of node PDU with Node-ID 0x1A";
CM_ SG_ 1434 PDU_OD_CoolingPumpEnabled "Enable the Cooling Pump.";
CM_ SG_ 1434 PDU_OD_LedCommands "Commands from Telemetry to leds";
CM_ SG_ 1434 PDU_OD_projectXXEnabled "Enable the Project XX leds.";
CM_ SG_ 1434 PDU_OD_watchdogTimeout "Timeout for the state machine watchdog in milliseconds.";
CM_ SG_ 1434 PDU_OD_statusSendInterval "Sending intervall for the status in milliseconds.";
CM_ SG_ 1434 PDU_OD_currentReadInterval "Sampling time in millisecconds for reading the currents.";
CM_ SG_ 1434 PDU_OD_batteryOvercurrent "Overcurrent limit in ampere of the low voltage battery.";
CM_ SG_ 1434 PDU_OD_overTempCritical "Error when battery temperature is getting critical high. Pod will be shut down";
CM_ SG_ 1434 PDU_OD_overTempWarn "Warning when battery temperature is getting high";
CM_ SG_ 1434 PDU_OD_batterVoltageCritical "Error when battery voltage is getting critical low. Pod will be shut down";
CM_ SG_ 1434 PDU_OD_batterVoltageLow "Warning when battery voltage is getting low";
CM_ SG_ 1434 PDU_OD_CAN2_DelayedTxMessages "Number of delayed TX messages on CAN2 because no messagebox was free.";
CM_ SG_ 1434 PDU_OD_CAN2_ErrorStatus "Internal error status (e.g. Error active, Error passive, Bus Off)";
CM_ SG_ 1434 PDU_OD_CAN2_DiscardedTxMessages "Number of discarded TX messages on CAN2 because all messageboxes were full";
CM_ SG_ 1434 PDU_OD_CAN2_Status "Status of CAN2.";
CM_ SG_ 1434 PDU_OD_CAN2_Baudrate "Baudrate of CAN.";
CM_ SG_ 1434 PDU_OD_CAN2_autoErrorReset "Automatic reset of errors.";
CM_ SG_ 1434 PDU_OD_CAN2_lastErrorCode "Last error code.";
CM_ SG_ 1434 PDU_OD_CAN2_RxErrCnt "Receive error count of CAN1.";
CM_ SG_ 1434 PDU_OD_CAN2_TxErrCnt "Transmit error count of CAN1.";
CM_ SG_ 1434 PDU_OD_CAN1_DelayedTxMessages "Number of delayed TX messages on CAN1 because no messagebox was free.";
CM_ SG_ 1434 PDU_OD_CAN1_ErrorStatus "Internal error status (e.g. Error active, Error passive, Bus Off)";
CM_ SG_ 1434 PDU_OD_CAN1_DiscardedTxMessages "Number of discarded TX messages on CAN1 because all messageboxes were full";
CM_ SG_ 1434 PDU_OD_CAN1_Status "Status of CAN1.";
CM_ SG_ 1434 PDU_OD_CAN1_Baudrate "Baudrate of CAN.";
CM_ SG_ 1434 PDU_OD_CAN1_autoErrorReset "Automatic reset of errors.";
CM_ SG_ 1434 PDU_OD_CAN1_lastErrorCode "Last error code.";
CM_ SG_ 1434 PDU_OD_CAN1_RxErrCnt "Receive error count of CAN1.";
CM_ SG_ 1434 PDU_OD_CAN1_TxErrCnt "Transmit error count of CAN1.";
CM_ SG_ 1434 PDU_OD_BuildTime "Software build time in the format HHMMSS.";
CM_ SG_ 1434 PDU_OD_BuildDate "Software build date in the format YYYYMMDD.";
CM_ SG_ 1434 PDU_OD_ChipUID2 "Seccond part of unique ID of microcontroller.";
CM_ SG_ 1434 PDU_OD_ChipUID1 "First part of unique ID of microcontroller.";
CM_ SG_ 1434 PDU_OD_SdcOut "Measurement of Shutdown Circuit Output";
CM_ SG_ 1434 PDU_OD_SdcIn "Measurement of Shutdown Circuit Input";
CM_ SG_ 1434 PDU_OD_runtime "Runtime of chip in milliseconds.";
CM_ SG_ 1434 PDU_OD_InputVoltage "Board supply voltage.";
CM_ SG_ 1434 PDU_OD_BoardTemp "Temperature of board";
CM_ SG_ 1434 PDU_OD_MemFree "Free memory in bytes.";
CM_ SG_ 1434 PDU_OD_CpuUsage "Current CPU usage in %.";
CM_ SG_ 1434 PDU_OD_OdEntrySendInterval "Interval for sending all readable OD entries. Sending is disabled if less than 5 ms.";
CM_ SG_ 1434 PDU_OD_SendOdOnBootup "Whether to send all OD entries on bootup.";
CM_ SG_ 1434 PDU_OD_HeartbeatInterval "Heartbeat Interval in milliseconds.";
CM_ SG_ 1434 PDU_OD_DbcVersion "CANzero DBC version.";
CM_ SG_ 1434 PDU_OD_StackVersion "CANzero stack version.";
CM_ SG_ 1434 PDU_OD_ProtocolVersion "CANzero Protocol Version.";
CM_ SG_ 1434 PDU_OD_NodeStatus "State of the node.";
CM_ SG_ 1434 PDU_OD_NodeID "CANzero Node-ID.";
CM_ SG_ 1434 PDU_SDO_RespCode "Response code of SDO access.";
CM_ SG_ 1434 PDU_SDO_ID "Specifies SDO-ID of PDU";
BA_DEF_ SG_  "GenSigSendType" ENUM  "Cyclic","OnWrite","OnWriteWithRepetition","OnChange","OnChangeWithRepetition","IfActive","IfActiveWithRepetition","NoSigSendType";
BA_DEF_ BO_  "GenMsgSendType" ENUM  "Cyclic","not_used","not_used","not_used","not_used","Cyclic","not_used","IfActive","NoMsgSendType";
BA_DEF_ BO_  "GenMsgCycleTime" INT 2 50000;
BA_DEF_ BO_  "GenMsgDelayTime" INT 1 1000;
BA_DEF_ BO_  "GenMsgNrOfRepetitions" INT 1 999999;
BA_DEF_ SG_  "GenSigStartValue" FLOAT 0 100000000000;
BA_DEF_ SG_  "CANzero_SDO_Group" STRING ;
BA_DEF_ SG_  "CANzero_SDO_AccessIfOperational" ENUM  "No","Yes";
BA_DEF_ SG_  "CANzero_SDO_AccessType" ENUM  "Read Write","Read Only","Write Only";
BA_DEF_ SG_  "CANzero_SDO_Default" FLOAT 0 0;
BA_DEF_ SG_  "SystemSignalLongSymbol" STRING ;
BA_DEF_DEF_  "GenSigSendType" "Cyclic";
BA_DEF_DEF_  "GenMsgSendType" "NoMsgSendType";
BA_DEF_DEF_  "GenMsgCycleTime" 100;
BA_DEF_DEF_  "GenMsgDelayTime" 1;
BA_DEF_DEF_  "GenMsgNrOfRepetitions" 1;
BA_DEF_DEF_  "GenSigStartValue" 0;
BA_DEF_DEF_  "CANzero_SDO_Group" "";
BA_DEF_DEF_  "CANzero_SDO_AccessIfOperational" "No";
BA_DEF_DEF_  "CANzero_SDO_AccessType" "Read Write";
BA_DEF_DEF_  "CANzero_SDO_Default" 0;
BA_DEF_DEF_  "SystemSignalLongSymbol" "";
BA_ "CANzero_SDO_AccessIfOperational" SG_ 1474 SensorR_OD_posDeviationOptic 1;
BA_ "GenSigStartValue" SG_ 1474 SensorR_OD_posDeviationOptic 40.0;
BA_ "CANzero_SDO_Default" SG_ 1474 SensorR_OD_posDeviationOptic 4;
BA_ "CANzero_SDO_AccessIfOperational" SG_ 1474 SensorR_OD_posDeviationEncoder 1;
BA_ "GenSigStartValue" SG_ 1474 SensorR_OD_posDeviationEncoder 40.0;
BA_ "CANzero_SDO_Default" SG_ 1474 SensorR_OD_posDeviationEncoder 4;
BA_ "CANzero_SDO_AccessIfOperational" SG_ 1474 SensorR_OD_velDeviationOptic 1;
BA_ "GenSigStartValue" SG_ 1474 SensorR_OD_velDeviationOptic 20.0;
BA_ "CANzero_SDO_Default" SG_ 1474 SensorR_OD_velDeviationOptic 2;
BA_ "CANzero_SDO_AccessIfOperational" SG_ 1474 SensorR_OD_velDeviationEncoder 1;
BA_ "GenSigStartValue" SG_ 1474 SensorR_OD_velDeviationEncoder 20.0;
BA_ "CANzero_SDO_Default" SG_ 1474 SensorR_OD_velDeviationEncoder 2;
BA_ "CANzero_SDO_AccessIfOperational" SG_ 1474 SensorR_OD_accDeviation 1;
BA_ "GenSigStartValue" SG_ 1474 SensorR_OD_accDeviation 40.0;
BA_ "CANzero_SDO_Default" SG_ 1474 SensorR_OD_accDeviation 4;
BA_ "CANzero_SDO_AccessIfOperational" SG_ 1474 SensorR_OD_EnableSignalGene_0000 1;
BA_ "SystemSignalLongSymbol" SG_ 1474 SensorR_OD_EnableSignalGene_0000 "SensorR_OD_EnableSignalGeneration";
BA_ "CANzero_SDO_AccessIfOperational" SG_ 1474 SensorR_OD_PositionGlitch 1;
BA_ "GenSigStartValue" SG_ 1474 SensorR_OD_PositionGlitch 50.0;
BA_ "CANzero_SDO_Default" SG_ 1474 SensorR_OD_PositionGlitch 5;
BA_ "CANzero_SDO_AccessIfOperational" SG_ 1474 SensorR_OD_ReflectorDistance 1;
BA_ "GenSigStartValue" SG_ 1474 SensorR_OD_ReflectorDistance 200.0;
BA_ "CANzero_SDO_Default" SG_ 1474 SensorR_OD_ReflectorDistance 20;
BA_ "CANzero_SDO_AccessIfOperational" SG_ 1474 SensorR_OD_StripeMode 1;
BA_ "GenSigStartValue" SG_ 1474 SensorR_OD_StripeMode 1.0;
BA_ "CANzero_SDO_Default" SG_ 1474 SensorR_OD_StripeMode 1;
BA_ "CANzero_SDO_AccessIfOperational" SG_ 1474 SensorR_OD_opc_lowpass_TcI 1;
BA_ "GenSigStartValue" SG_ 1474 SensorR_OD_opc_lowpass_TcI 2.0;
BA_ "CANzero_SDO_Default" SG_ 1474 SensorR_OD_opc_lowpass_TcI 0.02;
BA_ "CANzero_SDO_AccessIfOperational" SG_ 1474 SensorR_OD_opc_lowpass_Tcf 1;
BA_ "GenSigStartValue" SG_ 1474 SensorR_OD_opc_lowpass_Tcf 2.0;
BA_ "CANzero_SDO_Default" SG_ 1474 SensorR_OD_opc_lowpass_Tcf 0.02;
BA_ "CANzero_SDO_AccessIfOperational" SG_ 1474 SensorR_OD_opc_F_decrease 1;
BA_ "GenSigStartValue" SG_ 1474 SensorR_OD_opc_F_decrease 25.0;
BA_ "CANzero_SDO_Default" SG_ 1474 SensorR_OD_opc_F_decrease 0.25;
BA_ "CANzero_SDO_AccessIfOperational" SG_ 1474 SensorR_OD_opc_v_threshold 1;
BA_ "GenSigStartValue" SG_ 1474 SensorR_OD_opc_v_threshold 25.0;
BA_ "CANzero_SDO_Default" SG_ 1474 SensorR_OD_opc_v_threshold 0.25;
BA_ "CANzero_SDO_AccessIfOperational" SG_ 1474 SensorR_OD_opc_v_max 1;
BA_ "GenSigStartValue" SG_ 1474 SensorR_OD_opc_v_max 200.0;
BA_ "CANzero_SDO_Default" SG_ 1474 SensorR_OD_opc_v_max 2.0;
BA_ "CANzero_SDO_AccessIfOperational" SG_ 1474 SensorR_OD_opc_T_acc 1;
BA_ "GenSigStartValue" SG_ 1474 SensorR_OD_opc_T_acc 20.0;
BA_ "CANzero_SDO_Default" SG_ 1474 SensorR_OD_opc_T_acc 2.0;
BA_ "CANzero_SDO_AccessIfOperational" SG_ 1474 SensorR_OD_opc_F_max 1;
BA_ "GenSigStartValue" SG_ 1474 SensorR_OD_opc_F_max 90.0;
BA_ "CANzero_SDO_Default" SG_ 1474 SensorR_OD_opc_F_max 90;
BA_ "CANzero_SDO_AccessIfOperational" SG_ 1474 SensorR_OD_opc_t_run_max 1;
BA_ "GenSigStartValue" SG_ 1474 SensorR_OD_opc_t_run_max 40.0;
BA_ "CANzero_SDO_Default" SG_ 1474 SensorR_OD_opc_t_run_max 4.0;
BA_ "CANzero_SDO_AccessIfOperational" SG_ 1474 SensorR_OD_opc_brakeFlag 1;
BA_ "CANzero_SDO_AccessIfOperational" SG_ 1474 SensorR_OD_DebugCVOPCfreq 1;
BA_ "GenSigStartValue" SG_ 1474 SensorR_OD_DebugCVOPCfreq 32000.0;
BA_ "CANzero_SDO_AccessIfOperational" SG_ 1474 SensorR_OD_DebugCascadedIreq 1;
BA_ "GenSigStartValue" SG_ 1474 SensorR_OD_DebugCascadedIreq 32000.0;
BA_ "CANzero_SDO_AccessIfOperational" SG_ 1474 SensorR_OD_opc_ratelimiter_f 1;
BA_ "GenSigStartValue" SG_ 1474 SensorR_OD_opc_ratelimiter_f 37000.0;
BA_ "CANzero_SDO_Default" SG_ 1474 SensorR_OD_opc_ratelimiter_f 500;
BA_ "CANzero_SDO_AccessIfOperational" SG_ 1474 SensorR_OD_maxRunDistance 1;
BA_ "GenSigStartValue" SG_ 1474 SensorR_OD_maxRunDistance 38000.0;
BA_ "CANzero_SDO_Default" SG_ 1474 SensorR_OD_maxRunDistance 300;
BA_ "CANzero_SDO_AccessIfOperational" SG_ 1474 SensorR_OD_FinishedDelay 1;
BA_ "GenSigStartValue" SG_ 1474 SensorR_OD_FinishedDelay 2500.0;
BA_ "CANzero_SDO_Default" SG_ 1474 SensorR_OD_FinishedDelay 2500;
BA_ "CANzero_SDO_AccessIfOperational" SG_ 1474 SensorR_OD_Current4Stopping 1;
BA_ "GenSigStartValue" SG_ 1474 SensorR_OD_Current4Stopping 500.0;
BA_ "CANzero_SDO_Default" SG_ 1474 SensorR_OD_Current4Stopping 50.0;
BA_ "CANzero_SDO_AccessIfOperational" SG_ 1474 SensorR_OD_AdaptModelByCurrent 1;
BA_ "CANzero_SDO_AccessIfOperational" SG_ 1474 SensorR_OD_CVOPCTcFreq 1;
BA_ "GenSigStartValue" SG_ 1474 SensorR_OD_CVOPCTcFreq 100.0;
BA_ "CANzero_SDO_Default" SG_ 1474 SensorR_OD_CVOPCTcFreq 100;
BA_ "CANzero_SDO_AccessIfOperational" SG_ 1474 SensorR_OD_CVOPCImin 1;
BA_ "GenSigStartValue" SG_ 1474 SensorR_OD_CVOPCImin 50.0;
BA_ "CANzero_SDO_Default" SG_ 1474 SensorR_OD_CVOPCImin 50;
BA_ "CANzero_SDO_AccessIfOperational" SG_ 1474 SensorR_OD_CascadedKpDecrea_0000 1;
BA_ "GenSigStartValue" SG_ 1474 SensorR_OD_CascadedKpDecrea_0000 400.0;
BA_ "CANzero_SDO_Default" SG_ 1474 SensorR_OD_CascadedKpDecrea_0000 40.0;
BA_ "SystemSignalLongSymbol" SG_ 1474 SensorR_OD_CascadedKpDecrea_0000 "SensorR_OD_CascadedKpDecreaseCurrent";
BA_ "CANzero_SDO_AccessIfOperational" SG_ 1474 SensorR_OD_CascadedKpIncrea_0000 1;
BA_ "GenSigStartValue" SG_ 1474 SensorR_OD_CascadedKpIncrea_0000 400.0;
BA_ "CANzero_SDO_Default" SG_ 1474 SensorR_OD_CascadedKpIncrea_0000 40.0;
BA_ "SystemSignalLongSymbol" SG_ 1474 SensorR_OD_CascadedKpIncrea_0000 "SensorR_OD_CascadedKpIncreaseCurrent";
BA_ "CANzero_SDO_AccessIfOperational" SG_ 1474 SensorR_OD_CascadedFreqCurUpdate 1;
BA_ "GenSigStartValue" SG_ 1474 SensorR_OD_CascadedFreqCurUpdate 100.0;
BA_ "CANzero_SDO_Default" SG_ 1474 SensorR_OD_CascadedFreqCurUpdate 0.1;
BA_ "CANzero_SDO_AccessIfOperational" SG_ 1474 SensorR_OD_CascadedMaxSetFo_0000 1;
BA_ "GenSigStartValue" SG_ 1474 SensorR_OD_CascadedMaxSetFo_0000 1000.0;
BA_ "CANzero_SDO_Default" SG_ 1474 SensorR_OD_CascadedMaxSetFo_0000 100;
BA_ "SystemSignalLongSymbol" SG_ 1474 SensorR_OD_CascadedMaxSetFo_0000 "SensorR_OD_CascadedMaxSetForceDelta";
BA_ "CANzero_SDO_AccessIfOperational" SG_ 1474 SensorR_OD_CurrentForConsta_0000 1;
BA_ "GenSigStartValue" SG_ 1474 SensorR_OD_CurrentForConsta_0000 8000.0;
BA_ "CANzero_SDO_Default" SG_ 1474 SensorR_OD_CurrentForConsta_0000 80.0;
BA_ "SystemSignalLongSymbol" SG_ 1474 SensorR_OD_CurrentForConsta_0000 "SensorR_OD_CurrentForConstantVelocity";
BA_ "CANzero_SDO_AccessIfOperational" SG_ 1474 SensorR_OD_AccAtCurrentMeasured 1;
BA_ "GenSigStartValue" SG_ 1474 SensorR_OD_AccAtCurrentMeasured 7700.0;
BA_ "CANzero_SDO_Default" SG_ 1474 SensorR_OD_AccAtCurrentMeasured 77.0;
BA_ "CANzero_SDO_AccessIfOperational" SG_ 1474 SensorR_OD_CVOPCHystereseF 1;
BA_ "GenSigStartValue" SG_ 1474 SensorR_OD_CVOPCHystereseF 4000.0;
BA_ "CANzero_SDO_Default" SG_ 1474 SensorR_OD_CVOPCHystereseF 400;
BA_ "CANzero_SDO_AccessIfOperational" SG_ 1474 SensorR_OD_CVOPCReduceCurre_0000 1;
BA_ "GenSigStartValue" SG_ 1474 SensorR_OD_CVOPCReduceCurre_0000 90.0;
BA_ "CANzero_SDO_Default" SG_ 1474 SensorR_OD_CVOPCReduceCurre_0000 0.9;
BA_ "SystemSignalLongSymbol" SG_ 1474 SensorR_OD_CVOPCReduceCurre_0000 "SensorR_OD_CVOPCReduceCurrentWhileCruising";
BA_ "CANzero_SDO_AccessIfOperational" SG_ 1474 SensorR_OD_CVOPCDeltaVelHig_0000 1;
BA_ "GenSigStartValue" SG_ 1474 SensorR_OD_CVOPCDeltaVelHig_0000 30.0;
BA_ "CANzero_SDO_Default" SG_ 1474 SensorR_OD_CVOPCDeltaVelHig_0000 0.3;
BA_ "SystemSignalLongSymbol" SG_ 1474 SensorR_OD_CVOPCDeltaVelHig_0000 "SensorR_OD_CVOPCDeltaVelHigherCurrent";
BA_ "CANzero_SDO_AccessIfOperational" SG_ 1474 SensorR_OD_CVOPCSmoothingDe_0000 1;
BA_ "GenSigStartValue" SG_ 1474 SensorR_OD_CVOPCSmoothingDe_0000 5.0;
BA_ "CANzero_SDO_Default" SG_ 1474 SensorR_OD_CVOPCSmoothingDe_0000 0.05;
BA_ "SystemSignalLongSymbol" SG_ 1474 SensorR_OD_CVOPCSmoothingDe_0000 "SensorR_OD_CVOPCSmoothingDeltaVelocity";
BA_ "CANzero_SDO_AccessIfOperational" SG_ 1474 SensorR_OD_CVOPCTcI 1;
BA_ "GenSigStartValue" SG_ 1474 SensorR_OD_CVOPCTcI 300.0;
BA_ "CANzero_SDO_Default" SG_ 1474 SensorR_OD_CVOPCTcI 300;
BA_ "CANzero_SDO_AccessIfOperational" SG_ 1474 SensorR_OD_CVOPCTcf 1;
BA_ "GenSigStartValue" SG_ 1474 SensorR_OD_CVOPCTcf 1000.0;
BA_ "CANzero_SDO_Default" SG_ 1474 SensorR_OD_CVOPCTcf 1000;
BA_ "CANzero_SDO_AccessIfOperational" SG_ 1474 SensorR_OD_CVOPCImax 1;
BA_ "GenSigStartValue" SG_ 1474 SensorR_OD_CVOPCImax 200.0;
BA_ "CANzero_SDO_Default" SG_ 1474 SensorR_OD_CVOPCImax 200;
BA_ "CANzero_SDO_AccessIfOperational" SG_ 1474 SensorR_OD_VelocityController 1;
BA_ "CANzero_SDO_AccessIfOperational" SG_ 1474 SensorR_OD_TC_f 1;
BA_ "GenSigStartValue" SG_ 1474 SensorR_OD_TC_f 150.0;
BA_ "CANzero_SDO_Default" SG_ 1474 SensorR_OD_TC_f 150;
BA_ "CANzero_SDO_AccessIfOperational" SG_ 1474 SensorR_OD_TC_I 1;
BA_ "GenSigStartValue" SG_ 1474 SensorR_OD_TC_I 150.0;
BA_ "CANzero_SDO_Default" SG_ 1474 SensorR_OD_TC_I 150;
BA_ "CANzero_SDO_AccessType" SG_ 1474 SensorR_OD_EstimatedRunLength 1;
BA_ "CANzero_SDO_AccessIfOperational" SG_ 1474 SensorR_OD_EstimatedRunLength 1;
BA_ "GenSigStartValue" SG_ 1474 SensorR_OD_EstimatedRunLength 32000.0;
BA_ "CANzero_SDO_AccessIfOperational" SG_ 1474 SensorR_OD_RunProfile_V4 1;
BA_ "GenSigStartValue" SG_ 1474 SensorR_OD_RunProfile_V4 32700.0;
BA_ "CANzero_SDO_AccessIfOperational" SG_ 1474 SensorR_OD_RunProfile_T4 1;
BA_ "GenSigStartValue" SG_ 1474 SensorR_OD_RunProfile_T4 450.0;
BA_ "CANzero_SDO_Default" SG_ 1474 SensorR_OD_RunProfile_T4 4500;
BA_ "CANzero_SDO_AccessIfOperational" SG_ 1474 SensorR_OD_RunProfile_V3 1;
BA_ "GenSigStartValue" SG_ 1474 SensorR_OD_RunProfile_V3 32800.0;
BA_ "CANzero_SDO_Default" SG_ 1474 SensorR_OD_RunProfile_V3 1;
BA_ "CANzero_SDO_AccessIfOperational" SG_ 1474 SensorR_OD_RunProfile_T3 1;
BA_ "GenSigStartValue" SG_ 1474 SensorR_OD_RunProfile_T3 350.0;
BA_ "CANzero_SDO_Default" SG_ 1474 SensorR_OD_RunProfile_T3 3500;
BA_ "CANzero_SDO_AccessIfOperational" SG_ 1474 SensorR_OD_RunProfile_V2 1;
BA_ "GenSigStartValue" SG_ 1474 SensorR_OD_RunProfile_V2 32800.0;
BA_ "CANzero_SDO_Default" SG_ 1474 SensorR_OD_RunProfile_V2 1;
BA_ "CANzero_SDO_AccessIfOperational" SG_ 1474 SensorR_OD_RunProfile_T2 1;
BA_ "GenSigStartValue" SG_ 1474 SensorR_OD_RunProfile_T2 300.0;
BA_ "CANzero_SDO_Default" SG_ 1474 SensorR_OD_RunProfile_T2 3000;
BA_ "CANzero_SDO_AccessIfOperational" SG_ 1474 SensorR_OD_RunProfile_V1 1;
BA_ "GenSigStartValue" SG_ 1474 SensorR_OD_RunProfile_V1 32705.0;
BA_ "CANzero_SDO_Default" SG_ 1474 SensorR_OD_RunProfile_V1 0.05;
BA_ "CANzero_SDO_AccessIfOperational" SG_ 1474 SensorR_OD_RunProfile_T1 1;
BA_ "GenSigStartValue" SG_ 1474 SensorR_OD_RunProfile_T1 100.0;
BA_ "CANzero_SDO_Default" SG_ 1474 SensorR_OD_RunProfile_T1 1000;
BA_ "CANzero_SDO_AccessIfOperational" SG_ 1474 SensorR_OD_RunProfile_V0 1;
BA_ "GenSigStartValue" SG_ 1474 SensorR_OD_RunProfile_V0 32700.0;
BA_ "CANzero_SDO_AccessIfOperational" SG_ 1474 SensorR_OD_RunProfile_T0 1;
BA_ "CANzero_SDO_AccessIfOperational" SG_ 1474 SensorR_OD_SetFinish 1;
BA_ "CANzero_SDO_AccessIfOperational" SG_ 1474 SensorR_OD_RunMode 1;
BA_ "CANzero_SDO_AccessIfOperational" SG_ 1474 SensorR_OD_VdcReduceFactor 1;
BA_ "GenSigStartValue" SG_ 1474 SensorR_OD_VdcReduceFactor 9.499999999999998;
BA_ "CANzero_SDO_Default" SG_ 1474 SensorR_OD_VdcReduceFactor 0.95;
BA_ "CANzero_SDO_AccessIfOperational" SG_ 1474 SensorR_OD_MaxRequiredVelocity 1;
BA_ "GenSigStartValue" SG_ 1474 SensorR_OD_MaxRequiredVelocity 190.0;
BA_ "CANzero_SDO_Default" SG_ 1474 SensorR_OD_MaxRequiredVelocity 19;
BA_ "CANzero_SDO_AccessIfOperational" SG_ 1474 SensorR_OD_WarningThreshhol_0000 1;
BA_ "GenSigStartValue" SG_ 1474 SensorR_OD_WarningThreshhol_0000 900.0;
BA_ "CANzero_SDO_Default" SG_ 1474 SensorR_OD_WarningThreshhol_0000 0.9;
BA_ "SystemSignalLongSymbol" SG_ 1474 SensorR_OD_WarningThreshhol_0000 "SensorR_OD_WarningThreshholdForLimModelOutOfBoundaries";
BA_ "CANzero_SDO_AccessIfOperational" SG_ 1474 SensorR_OD_MaxCtrlErrorDuration 1;
BA_ "GenSigStartValue" SG_ 1474 SensorR_OD_MaxCtrlErrorDuration 50.0;
BA_ "CANzero_SDO_Default" SG_ 1474 SensorR_OD_MaxCtrlErrorDuration 0.5;
BA_ "CANzero_SDO_AccessIfOperational" SG_ 1474 SensorR_OD_MaxCtrlError 1;
BA_ "GenSigStartValue" SG_ 1474 SensorR_OD_MaxCtrlError 150.0;
BA_ "CANzero_SDO_Default" SG_ 1474 SensorR_OD_MaxCtrlError 1.5;
BA_ "CANzero_SDO_AccessIfOperational" SG_ 1474 SensorR_OD_FminCtrl 1;
BA_ "GenSigStartValue" SG_ 1474 SensorR_OD_FminCtrl 922.0;
BA_ "CANzero_SDO_Default" SG_ 1474 SensorR_OD_FminCtrl 922;
BA_ "CANzero_SDO_AccessIfOperational" SG_ 1474 SensorR_OD_FmaxCtrl 1;
BA_ "GenSigStartValue" SG_ 1474 SensorR_OD_FmaxCtrl 1004.0;
BA_ "CANzero_SDO_Default" SG_ 1474 SensorR_OD_FmaxCtrl 1004;
BA_ "CANzero_SDO_AccessIfOperational" SG_ 1474 SensorR_OD_PodMass 1;
BA_ "GenSigStartValue" SG_ 1474 SensorR_OD_PodMass 2300.0;
BA_ "CANzero_SDO_Default" SG_ 1474 SensorR_OD_PodMass 230.0;
BA_ "CANzero_SDO_AccessIfOperational" SG_ 1474 SensorR_OD_CurrentReq 1;
BA_ "GenSigStartValue" SG_ 1474 SensorR_OD_CurrentReq 1050.0;
BA_ "CANzero_SDO_Default" SG_ 1474 SensorR_OD_CurrentReq 105.0;
BA_ "CANzero_SDO_AccessIfOperational" SG_ 1474 SensorR_OD_CtrlMode 1;
BA_ "GenSigStartValue" SG_ 1474 SensorR_OD_CtrlMode 1.0;
BA_ "CANzero_SDO_Default" SG_ 1474 SensorR_OD_CtrlMode 1;
BA_ "CANzero_SDO_AccessIfOperational" SG_ 1474 SensorR_OD_OpcKi 1;
BA_ "GenSigStartValue" SG_ 1474 SensorR_OD_OpcKi 50.0;
BA_ "CANzero_SDO_Default" SG_ 1474 SensorR_OD_OpcKi 0.5;
BA_ "CANzero_SDO_AccessIfOperational" SG_ 1474 SensorR_OD_OpcKp 1;
BA_ "GenSigStartValue" SG_ 1474 SensorR_OD_OpcKp 600.0;
BA_ "CANzero_SDO_Default" SG_ 1474 SensorR_OD_OpcKp 6.0;
BA_ "CANzero_SDO_AccessIfOperational" SG_ 1474 SensorR_OD_ExecTimeReadSensors 1;
BA_ "CANzero_SDO_AccessIfOperational" SG_ 1474 SensorR_OD_ExecTimeControl 1;
BA_ "CANzero_SDO_AccessIfOperational" SG_ 1474 SensorR_OD_ExecTimeStateEst 1;
BA_ "CANzero_SDO_AccessIfOperational" SG_ 1474 SensorR_OD_ExecTimeOverall 1;
BA_ "CANzero_SDO_AccessType" SG_ 1474 SensorR_OD_IMU3_Temperature 1;
BA_ "CANzero_SDO_AccessIfOperational" SG_ 1474 SensorR_OD_IMU3_Temperature 1;
BA_ "GenSigStartValue" SG_ 1474 SensorR_OD_IMU3_Temperature 10000.0;
BA_ "CANzero_SDO_AccessType" SG_ 1474 SensorR_OD_IMU2_Temperature 1;
BA_ "CANzero_SDO_AccessIfOperational" SG_ 1474 SensorR_OD_IMU2_Temperature 1;
BA_ "GenSigStartValue" SG_ 1474 SensorR_OD_IMU2_Temperature 10000.0;
BA_ "CANzero_SDO_AccessType" SG_ 1474 SensorR_OD_IMU1_Temperature 1;
BA_ "CANzero_SDO_AccessIfOperational" SG_ 1474 SensorR_OD_IMU1_Temperature 1;
BA_ "GenSigStartValue" SG_ 1474 SensorR_OD_IMU1_Temperature 10000.0;
BA_ "CANzero_SDO_AccessType" SG_ 1474 SensorR_OD_IMU_number 1;
BA_ "CANzero_SDO_AccessIfOperational" SG_ 1474 SensorR_OD_IMU_number 1;
BA_ "CANzero_SDO_AccessType" SG_ 1474 SensorR_OD_EncoderResetPosition 2;
BA_ "CANzero_SDO_AccessIfOperational" SG_ 1474 SensorR_OD_EncoderResetPosition 1;
BA_ "CANzero_SDO_AccessIfOperational" SG_ 1474 SensorR_OD_EncoderWheelDiameter 1;
BA_ "GenSigStartValue" SG_ 1474 SensorR_OD_EncoderWheelDiameter 15000.0;
BA_ "CANzero_SDO_Default" SG_ 1474 SensorR_OD_EncoderWheelDiameter 75;
BA_ "CANzero_SDO_AccessIfOperational" SG_ 1474 SensorR_OD_samplingInterval 1;
BA_ "GenSigStartValue" SG_ 1474 SensorR_OD_samplingInterval 1000.0;
BA_ "CANzero_SDO_Default" SG_ 1474 SensorR_OD_samplingInterval 10;
BA_ "CANzero_SDO_Group" SG_ 1474 SensorR_OD_CAN2_DelayedTxMe_0000 "CAN";
BA_ "CANzero_SDO_AccessType" SG_ 1474 SensorR_OD_CAN2_DelayedTxMe_0000 1;
BA_ "CANzero_SDO_AccessIfOperational" SG_ 1474 SensorR_OD_CAN2_DelayedTxMe_0000 1;
BA_ "SystemSignalLongSymbol" SG_ 1474 SensorR_OD_CAN2_DelayedTxMe_0000 "SensorR_OD_CAN2_DelayedTxMessages";
BA_ "CANzero_SDO_Group" SG_ 1474 SensorR_OD_CAN2_ErrorStatus "CAN";
BA_ "CANzero_SDO_AccessType" SG_ 1474 SensorR_OD_CAN2_ErrorStatus 1;
BA_ "CANzero_SDO_AccessIfOperational" SG_ 1474 SensorR_OD_CAN2_ErrorStatus 1;
BA_ "CANzero_SDO_Group" SG_ 1474 SensorR_OD_CAN2_DiscardedTx_0000 "CAN";
BA_ "CANzero_SDO_AccessType" SG_ 1474 SensorR_OD_CAN2_DiscardedTx_0000 1;
BA_ "CANzero_SDO_AccessIfOperational" SG_ 1474 SensorR_OD_CAN2_DiscardedTx_0000 1;
BA_ "SystemSignalLongSymbol" SG_ 1474 SensorR_OD_CAN2_DiscardedTx_0000 "SensorR_OD_CAN2_DiscardedTxMessages";
BA_ "CANzero_SDO_Group" SG_ 1474 SensorR_OD_CAN2_Status "CAN";
BA_ "CANzero_SDO_AccessType" SG_ 1474 SensorR_OD_CAN2_Status 1;
BA_ "CANzero_SDO_AccessIfOperational" SG_ 1474 SensorR_OD_CAN2_Status 1;
BA_ "CANzero_SDO_Group" SG_ 1474 SensorR_OD_CAN2_Baudrate "CAN";
BA_ "CANzero_SDO_AccessIfOperational" SG_ 1474 SensorR_OD_CAN2_Baudrate 1;
BA_ "GenSigStartValue" SG_ 1474 SensorR_OD_CAN2_Baudrate 1000.0;
BA_ "CANzero_SDO_Default" SG_ 1474 SensorR_OD_CAN2_Baudrate 1000;
BA_ "CANzero_SDO_Group" SG_ 1474 SensorR_OD_CAN2_autoErrorReset "CAN";
BA_ "CANzero_SDO_AccessIfOperational" SG_ 1474 SensorR_OD_CAN2_autoErrorReset 1;
BA_ "GenSigStartValue" SG_ 1474 SensorR_OD_CAN2_autoErrorReset 1.0;
BA_ "CANzero_SDO_Default" SG_ 1474 SensorR_OD_CAN2_autoErrorReset 1;
BA_ "CANzero_SDO_Group" SG_ 1474 SensorR_OD_CAN2_lastErrorCode "CAN";
BA_ "CANzero_SDO_AccessType" SG_ 1474 SensorR_OD_CAN2_lastErrorCode 1;
BA_ "CANzero_SDO_AccessIfOperational" SG_ 1474 SensorR_OD_CAN2_lastErrorCode 1;
BA_ "CANzero_SDO_Group" SG_ 1474 SensorR_OD_CAN2_RxErrCnt "CAN";
BA_ "CANzero_SDO_AccessType" SG_ 1474 SensorR_OD_CAN2_RxErrCnt 1;
BA_ "CANzero_SDO_AccessIfOperational" SG_ 1474 SensorR_OD_CAN2_RxErrCnt 1;
BA_ "CANzero_SDO_Group" SG_ 1474 SensorR_OD_CAN2_TxErrCnt "CAN";
BA_ "CANzero_SDO_AccessType" SG_ 1474 SensorR_OD_CAN2_TxErrCnt 1;
BA_ "CANzero_SDO_AccessIfOperational" SG_ 1474 SensorR_OD_CAN2_TxErrCnt 1;
BA_ "CANzero_SDO_Group" SG_ 1474 SensorR_OD_CAN1_DelayedTxMe_0000 "CAN";
BA_ "CANzero_SDO_AccessType" SG_ 1474 SensorR_OD_CAN1_DelayedTxMe_0000 1;
BA_ "CANzero_SDO_AccessIfOperational" SG_ 1474 SensorR_OD_CAN1_DelayedTxMe_0000 1;
BA_ "SystemSignalLongSymbol" SG_ 1474 SensorR_OD_CAN1_DelayedTxMe_0000 "SensorR_OD_CAN1_DelayedTxMessages";
BA_ "CANzero_SDO_Group" SG_ 1474 SensorR_OD_CAN1_ErrorStatus "CAN";
BA_ "CANzero_SDO_AccessType" SG_ 1474 SensorR_OD_CAN1_ErrorStatus 1;
BA_ "CANzero_SDO_AccessIfOperational" SG_ 1474 SensorR_OD_CAN1_ErrorStatus 1;
BA_ "CANzero_SDO_Group" SG_ 1474 SensorR_OD_CAN1_DiscardedTx_0000 "CAN";
BA_ "CANzero_SDO_AccessType" SG_ 1474 SensorR_OD_CAN1_DiscardedTx_0000 1;
BA_ "CANzero_SDO_AccessIfOperational" SG_ 1474 SensorR_OD_CAN1_DiscardedTx_0000 1;
BA_ "SystemSignalLongSymbol" SG_ 1474 SensorR_OD_CAN1_DiscardedTx_0000 "SensorR_OD_CAN1_DiscardedTxMessages";
BA_ "CANzero_SDO_Group" SG_ 1474 SensorR_OD_CAN1_Status "CAN";
BA_ "CANzero_SDO_AccessType" SG_ 1474 SensorR_OD_CAN1_Status 1;
BA_ "CANzero_SDO_AccessIfOperational" SG_ 1474 SensorR_OD_CAN1_Status 1;
BA_ "CANzero_SDO_Group" SG_ 1474 SensorR_OD_CAN1_Baudrate "CAN";
BA_ "CANzero_SDO_AccessIfOperational" SG_ 1474 SensorR_OD_CAN1_Baudrate 1;
BA_ "GenSigStartValue" SG_ 1474 SensorR_OD_CAN1_Baudrate 1000.0;
BA_ "CANzero_SDO_Default" SG_ 1474 SensorR_OD_CAN1_Baudrate 1000;
BA_ "CANzero_SDO_Group" SG_ 1474 SensorR_OD_CAN1_autoErrorReset "CAN";
BA_ "CANzero_SDO_AccessIfOperational" SG_ 1474 SensorR_OD_CAN1_autoErrorReset 1;
BA_ "GenSigStartValue" SG_ 1474 SensorR_OD_CAN1_autoErrorReset 1.0;
BA_ "CANzero_SDO_Default" SG_ 1474 SensorR_OD_CAN1_autoErrorReset 1;
BA_ "CANzero_SDO_Group" SG_ 1474 SensorR_OD_CAN1_lastErrorCode "CAN";
BA_ "CANzero_SDO_AccessType" SG_ 1474 SensorR_OD_CAN1_lastErrorCode 1;
BA_ "CANzero_SDO_AccessIfOperational" SG_ 1474 SensorR_OD_CAN1_lastErrorCode 1;
BA_ "CANzero_SDO_Group" SG_ 1474 SensorR_OD_CAN1_RxErrCnt "CAN";
BA_ "CANzero_SDO_AccessType" SG_ 1474 SensorR_OD_CAN1_RxErrCnt 1;
BA_ "CANzero_SDO_AccessIfOperational" SG_ 1474 SensorR_OD_CAN1_RxErrCnt 1;
BA_ "CANzero_SDO_Group" SG_ 1474 SensorR_OD_CAN1_TxErrCnt "CAN";
BA_ "CANzero_SDO_AccessType" SG_ 1474 SensorR_OD_CAN1_TxErrCnt 1;
BA_ "CANzero_SDO_AccessIfOperational" SG_ 1474 SensorR_OD_CAN1_TxErrCnt 1;
BA_ "CANzero_SDO_AccessType" SG_ 1474 SensorR_OD_BuildTime 1;
BA_ "CANzero_SDO_AccessIfOperational" SG_ 1474 SensorR_OD_BuildTime 1;
BA_ "CANzero_SDO_AccessType" SG_ 1474 SensorR_OD_BuildDate 1;
BA_ "CANzero_SDO_AccessIfOperational" SG_ 1474 SensorR_OD_BuildDate 1;
BA_ "CANzero_SDO_AccessType" SG_ 1474 SensorR_OD_ChipUID2 1;
BA_ "CANzero_SDO_AccessIfOperational" SG_ 1474 SensorR_OD_ChipUID2 1;
BA_ "CANzero_SDO_AccessType" SG_ 1474 SensorR_OD_ChipUID1 1;
BA_ "CANzero_SDO_AccessIfOperational" SG_ 1474 SensorR_OD_ChipUID1 1;
BA_ "CANzero_SDO_AccessType" SG_ 1474 SensorR_OD_SdcOut 1;
BA_ "CANzero_SDO_AccessIfOperational" SG_ 1474 SensorR_OD_SdcOut 1;
BA_ "CANzero_SDO_AccessType" SG_ 1474 SensorR_OD_SdcIn 1;
BA_ "CANzero_SDO_AccessIfOperational" SG_ 1474 SensorR_OD_SdcIn 1;
BA_ "CANzero_SDO_AccessType" SG_ 1474 SensorR_OD_runtime 1;
BA_ "CANzero_SDO_AccessIfOperational" SG_ 1474 SensorR_OD_runtime 1;
BA_ "CANzero_SDO_AccessType" SG_ 1474 SensorR_OD_InputVoltage 1;
BA_ "CANzero_SDO_AccessIfOperational" SG_ 1474 SensorR_OD_InputVoltage 1;
BA_ "CANzero_SDO_AccessType" SG_ 1474 SensorR_OD_BoardTemp 1;
BA_ "CANzero_SDO_AccessIfOperational" SG_ 1474 SensorR_OD_BoardTemp 1;
BA_ "GenSigStartValue" SG_ 1474 SensorR_OD_BoardTemp 3000.0;
BA_ "CANzero_SDO_AccessType" SG_ 1474 SensorR_OD_MemFree 1;
BA_ "CANzero_SDO_AccessIfOperational" SG_ 1474 SensorR_OD_MemFree 1;
BA_ "CANzero_SDO_AccessType" SG_ 1474 SensorR_OD_CpuUsage 1;
BA_ "CANzero_SDO_AccessIfOperational" SG_ 1474 SensorR_OD_CpuUsage 1;
BA_ "CANzero_SDO_AccessIfOperational" SG_ 1474 SensorR_OD_OdEntrySendInterval 1;
BA_ "GenSigStartValue" SG_ 1474 SensorR_OD_OdEntrySendInterval 50.0;
BA_ "CANzero_SDO_Default" SG_ 1474 SensorR_OD_OdEntrySendInterval 50;
BA_ "CANzero_SDO_AccessIfOperational" SG_ 1474 SensorR_OD_SendOdOnBootup 1;
BA_ "CANzero_SDO_AccessIfOperational" SG_ 1474 SensorR_OD_HeartbeatInterval 1;
BA_ "GenSigStartValue" SG_ 1474 SensorR_OD_HeartbeatInterval 250.0;
BA_ "CANzero_SDO_Default" SG_ 1474 SensorR_OD_HeartbeatInterval 250;
BA_ "CANzero_SDO_AccessType" SG_ 1474 SensorR_OD_DbcVersion 1;
BA_ "CANzero_SDO_AccessIfOperational" SG_ 1474 SensorR_OD_DbcVersion 1;
BA_ "CANzero_SDO_AccessType" SG_ 1474 SensorR_OD_StackVersion 1;
BA_ "CANzero_SDO_AccessIfOperational" SG_ 1474 SensorR_OD_StackVersion 1;
BA_ "CANzero_SDO_AccessType" SG_ 1474 SensorR_OD_ProtocolVersion 1;
BA_ "CANzero_SDO_AccessIfOperational" SG_ 1474 SensorR_OD_ProtocolVersion 1;
BA_ "GenSigStartValue" SG_ 1474 SensorR_OD_ProtocolVersion 1.0;
BA_ "CANzero_SDO_Default" SG_ 1474 SensorR_OD_ProtocolVersion 1;
BA_ "CANzero_SDO_AccessType" SG_ 1474 SensorR_OD_NodeStatus 1;
BA_ "CANzero_SDO_AccessIfOperational" SG_ 1474 SensorR_OD_NodeStatus 1;
BA_ "CANzero_SDO_AccessType" SG_ 1474 SensorR_OD_NodeID 1;
BA_ "CANzero_SDO_AccessIfOperational" SG_ 1474 SensorR_OD_NodeID 1;
BA_ "SystemSignalLongSymbol" SG_ 145 BrakeF_E5_retractUnsuccesful_ope "BrakeF_E5_retractUnsuccesful_openSDC";
BA_ "SystemSignalLongSymbol" SG_ 145 BrakeF_E4_retractUnsuccesful_not "BrakeF_E4_retractUnsuccesful_notEnabled";
BA_ "SystemSignalLongSymbol" SG_ 145 BrakeF_E3_retractUnsuccesful_err "BrakeF_E3_retractUnsuccesful_errorFlag";
BA_ "SystemSignalLongSymbol" SG_ 145 BrakeF_W1_highPressureRetracting "BrakeF_W1_highPressureRetractingChamber";
BA_ "SystemSignalLongSymbol" SG_ 145 BrakeF_W0_highPressureActingCham "BrakeF_W0_highPressureActingChamber";
BA_ "CANzero_SDO_AccessIfOperational" SG_ 1425 BrakeF_OD_BrakeStatus 1;
BA_ "CANzero_SDO_AccessType" SG_ 1425 BrakeF_OD_CoolingPressure 1;
BA_ "CANzero_SDO_AccessIfOperational" SG_ 1425 BrakeF_OD_CoolingPressure 1;
BA_ "GenSigStartValue" SG_ 1425 BrakeF_OD_CoolingPressure 9810.0;
BA_ "CANzero_SDO_Default" SG_ 1425 BrakeF_OD_CoolingPressure -1.9;
BA_ "CANzero_SDO_AccessIfOperational" SG_ 1425 BrakeF_OD_valveUpperTolerance 1;
BA_ "GenSigStartValue" SG_ 1425 BrakeF_OD_valveUpperTolerance 2000.0;
BA_ "CANzero_SDO_Default" SG_ 1425 BrakeF_OD_valveUpperTolerance 10;
BA_ "CANzero_SDO_AccessIfOperational" SG_ 1425 BrakeF_OD_commWatchdog 1;
BA_ "GenSigStartValue" SG_ 1425 BrakeF_OD_commWatchdog 60.0;
BA_ "CANzero_SDO_Default" SG_ 1425 BrakeF_OD_commWatchdog 60;
BA_ "CANzero_SDO_AccessIfOperational" SG_ 1425 BrakeF_OD_counterLimit 1;
BA_ "GenSigStartValue" SG_ 1425 BrakeF_OD_counterLimit 5.0;
BA_ "CANzero_SDO_Default" SG_ 1425 BrakeF_OD_counterLimit 5;
BA_ "CANzero_SDO_AccessIfOperational" SG_ 1425 BrakeF_OD_delay 1;
BA_ "GenSigStartValue" SG_ 1425 BrakeF_OD_delay 10.0;
BA_ "CANzero_SDO_Default" SG_ 1425 BrakeF_OD_delay 5;
BA_ "CANzero_SDO_AccessIfOperational" SG_ 1425 BrakeF_OD_tankUpperControlLimit 1;
BA_ "GenSigStartValue" SG_ 1425 BrakeF_OD_tankUpperControlLimit 3800.0;
BA_ "CANzero_SDO_Default" SG_ 1425 BrakeF_OD_tankUpperControlLimit 19;
BA_ "CANzero_SDO_AccessIfOperational" SG_ 1425 BrakeF_OD_tankLowerControlLimit 1;
BA_ "GenSigStartValue" SG_ 1425 BrakeF_OD_tankLowerControlLimit 1400.0;
BA_ "CANzero_SDO_Default" SG_ 1425 BrakeF_OD_tankLowerControlLimit 7;
BA_ "CANzero_SDO_Group" SG_ 1425 BrakeF_OD_CAN2_DelayedTxMessages "CAN";
BA_ "CANzero_SDO_AccessType" SG_ 1425 BrakeF_OD_CAN2_DelayedTxMessages 1;
BA_ "CANzero_SDO_AccessIfOperational" SG_ 1425 BrakeF_OD_CAN2_DelayedTxMessages 1;
BA_ "CANzero_SDO_Group" SG_ 1425 BrakeF_OD_CAN2_ErrorStatus "CAN";
BA_ "CANzero_SDO_AccessType" SG_ 1425 BrakeF_OD_CAN2_ErrorStatus 1;
BA_ "CANzero_SDO_AccessIfOperational" SG_ 1425 BrakeF_OD_CAN2_ErrorStatus 1;
BA_ "CANzero_SDO_Group" SG_ 1425 BrakeF_OD_CAN2_DiscardedTxMessag "CAN";
BA_ "CANzero_SDO_AccessType" SG_ 1425 BrakeF_OD_CAN2_DiscardedTxMessag 1;
BA_ "CANzero_SDO_AccessIfOperational" SG_ 1425 BrakeF_OD_CAN2_DiscardedTxMessag 1;
BA_ "SystemSignalLongSymbol" SG_ 1425 BrakeF_OD_CAN2_DiscardedTxMessag "BrakeF_OD_CAN2_DiscardedTxMessages";
BA_ "CANzero_SDO_Group" SG_ 1425 BrakeF_OD_CAN2_Status "CAN";
BA_ "CANzero_SDO_AccessType" SG_ 1425 BrakeF_OD_CAN2_Status 1;
BA_ "CANzero_SDO_AccessIfOperational" SG_ 1425 BrakeF_OD_CAN2_Status 1;
BA_ "CANzero_SDO_Group" SG_ 1425 BrakeF_OD_CAN2_Baudrate "CAN";
BA_ "CANzero_SDO_AccessIfOperational" SG_ 1425 BrakeF_OD_CAN2_Baudrate 1;
BA_ "GenSigStartValue" SG_ 1425 BrakeF_OD_CAN2_Baudrate 1000.0;
BA_ "CANzero_SDO_Default" SG_ 1425 BrakeF_OD_CAN2_Baudrate 1000;
BA_ "CANzero_SDO_Group" SG_ 1425 BrakeF_OD_CAN2_autoErrorReset "CAN";
BA_ "CANzero_SDO_AccessIfOperational" SG_ 1425 BrakeF_OD_CAN2_autoErrorReset 1;
BA_ "GenSigStartValue" SG_ 1425 BrakeF_OD_CAN2_autoErrorReset 1.0;
BA_ "CANzero_SDO_Default" SG_ 1425 BrakeF_OD_CAN2_autoErrorReset 1;
BA_ "CANzero_SDO_Group" SG_ 1425 BrakeF_OD_CAN2_lastErrorCode "CAN";
BA_ "CANzero_SDO_AccessType" SG_ 1425 BrakeF_OD_CAN2_lastErrorCode 1;
BA_ "CANzero_SDO_AccessIfOperational" SG_ 1425 BrakeF_OD_CAN2_lastErrorCode 1;
BA_ "CANzero_SDO_Group" SG_ 1425 BrakeF_OD_CAN2_RxErrCnt "CAN";
BA_ "CANzero_SDO_AccessType" SG_ 1425 BrakeF_OD_CAN2_RxErrCnt 1;
BA_ "CANzero_SDO_AccessIfOperational" SG_ 1425 BrakeF_OD_CAN2_RxErrCnt 1;
BA_ "CANzero_SDO_Group" SG_ 1425 BrakeF_OD_CAN2_TxErrCnt "CAN";
BA_ "CANzero_SDO_AccessType" SG_ 1425 BrakeF_OD_CAN2_TxErrCnt 1;
BA_ "CANzero_SDO_AccessIfOperational" SG_ 1425 BrakeF_OD_CAN2_TxErrCnt 1;
BA_ "CANzero_SDO_Group" SG_ 1425 BrakeF_OD_CAN1_DelayedTxMessages "CAN";
BA_ "CANzero_SDO_AccessType" SG_ 1425 BrakeF_OD_CAN1_DelayedTxMessages 1;
BA_ "CANzero_SDO_AccessIfOperational" SG_ 1425 BrakeF_OD_CAN1_DelayedTxMessages 1;
BA_ "CANzero_SDO_Group" SG_ 1425 BrakeF_OD_CAN1_ErrorStatus "CAN";
BA_ "CANzero_SDO_AccessType" SG_ 1425 BrakeF_OD_CAN1_ErrorStatus 1;
BA_ "CANzero_SDO_AccessIfOperational" SG_ 1425 BrakeF_OD_CAN1_ErrorStatus 1;
BA_ "CANzero_SDO_Group" SG_ 1425 BrakeF_OD_CAN1_DiscardedTxMessag "CAN";
BA_ "CANzero_SDO_AccessType" SG_ 1425 BrakeF_OD_CAN1_DiscardedTxMessag 1;
BA_ "CANzero_SDO_AccessIfOperational" SG_ 1425 BrakeF_OD_CAN1_DiscardedTxMessag 1;
BA_ "SystemSignalLongSymbol" SG_ 1425 BrakeF_OD_CAN1_DiscardedTxMessag "BrakeF_OD_CAN1_DiscardedTxMessages";
BA_ "CANzero_SDO_Group" SG_ 1425 BrakeF_OD_CAN1_Status "CAN";
BA_ "CANzero_SDO_AccessType" SG_ 1425 BrakeF_OD_CAN1_Status 1;
BA_ "CANzero_SDO_AccessIfOperational" SG_ 1425 BrakeF_OD_CAN1_Status 1;
BA_ "CANzero_SDO_Group" SG_ 1425 BrakeF_OD_CAN1_Baudrate "CAN";
BA_ "CANzero_SDO_AccessIfOperational" SG_ 1425 BrakeF_OD_CAN1_Baudrate 1;
BA_ "GenSigStartValue" SG_ 1425 BrakeF_OD_CAN1_Baudrate 1000.0;
BA_ "CANzero_SDO_Default" SG_ 1425 BrakeF_OD_CAN1_Baudrate 1000;
BA_ "CANzero_SDO_Group" SG_ 1425 BrakeF_OD_CAN1_autoErrorReset "CAN";
BA_ "CANzero_SDO_AccessIfOperational" SG_ 1425 BrakeF_OD_CAN1_autoErrorReset 1;
BA_ "GenSigStartValue" SG_ 1425 BrakeF_OD_CAN1_autoErrorReset 1.0;
BA_ "CANzero_SDO_Default" SG_ 1425 BrakeF_OD_CAN1_autoErrorReset 1;
BA_ "CANzero_SDO_Group" SG_ 1425 BrakeF_OD_CAN1_lastErrorCode "CAN";
BA_ "CANzero_SDO_AccessType" SG_ 1425 BrakeF_OD_CAN1_lastErrorCode 1;
BA_ "CANzero_SDO_AccessIfOperational" SG_ 1425 BrakeF_OD_CAN1_lastErrorCode 1;
BA_ "CANzero_SDO_Group" SG_ 1425 BrakeF_OD_CAN1_RxErrCnt "CAN";
BA_ "CANzero_SDO_AccessType" SG_ 1425 BrakeF_OD_CAN1_RxErrCnt 1;
BA_ "CANzero_SDO_AccessIfOperational" SG_ 1425 BrakeF_OD_CAN1_RxErrCnt 1;
BA_ "CANzero_SDO_Group" SG_ 1425 BrakeF_OD_CAN1_TxErrCnt "CAN";
BA_ "CANzero_SDO_AccessType" SG_ 1425 BrakeF_OD_CAN1_TxErrCnt 1;
BA_ "CANzero_SDO_AccessIfOperational" SG_ 1425 BrakeF_OD_CAN1_TxErrCnt 1;
BA_ "CANzero_SDO_AccessType" SG_ 1425 BrakeF_OD_BuildTime 1;
BA_ "CANzero_SDO_AccessIfOperational" SG_ 1425 BrakeF_OD_BuildTime 1;
BA_ "CANzero_SDO_AccessType" SG_ 1425 BrakeF_OD_BuildDate 1;
BA_ "CANzero_SDO_AccessIfOperational" SG_ 1425 BrakeF_OD_BuildDate 1;
BA_ "CANzero_SDO_AccessType" SG_ 1425 BrakeF_OD_ChipUID2 1;
BA_ "CANzero_SDO_AccessIfOperational" SG_ 1425 BrakeF_OD_ChipUID2 1;
BA_ "CANzero_SDO_AccessType" SG_ 1425 BrakeF_OD_ChipUID1 1;
BA_ "CANzero_SDO_AccessIfOperational" SG_ 1425 BrakeF_OD_ChipUID1 1;
BA_ "CANzero_SDO_AccessType" SG_ 1425 BrakeF_OD_SdcOut 1;
BA_ "CANzero_SDO_AccessIfOperational" SG_ 1425 BrakeF_OD_SdcOut 1;
BA_ "CANzero_SDO_AccessType" SG_ 1425 BrakeF_OD_SdcIn 1;
BA_ "CANzero_SDO_AccessIfOperational" SG_ 1425 BrakeF_OD_SdcIn 1;
BA_ "CANzero_SDO_AccessType" SG_ 1425 BrakeF_OD_runtime 1;
BA_ "CANzero_SDO_AccessIfOperational" SG_ 1425 BrakeF_OD_runtime 1;
BA_ "CANzero_SDO_AccessType" SG_ 1425 BrakeF_OD_InputVoltage 1;
BA_ "CANzero_SDO_AccessIfOperational" SG_ 1425 BrakeF_OD_InputVoltage 1;
BA_ "CANzero_SDO_AccessType" SG_ 1425 BrakeF_OD_BoardTemp 1;
BA_ "CANzero_SDO_AccessIfOperational" SG_ 1425 BrakeF_OD_BoardTemp 1;
BA_ "GenSigStartValue" SG_ 1425 BrakeF_OD_BoardTemp 3000.0;
BA_ "CANzero_SDO_AccessType" SG_ 1425 BrakeF_OD_MemFree 1;
BA_ "CANzero_SDO_AccessIfOperational" SG_ 1425 BrakeF_OD_MemFree 1;
BA_ "CANzero_SDO_AccessType" SG_ 1425 BrakeF_OD_CpuUsage 1;
BA_ "CANzero_SDO_AccessIfOperational" SG_ 1425 BrakeF_OD_CpuUsage 1;
BA_ "CANzero_SDO_AccessIfOperational" SG_ 1425 BrakeF_OD_OdEntrySendInterval 1;
BA_ "GenSigStartValue" SG_ 1425 BrakeF_OD_OdEntrySendInterval 50.0;
BA_ "CANzero_SDO_Default" SG_ 1425 BrakeF_OD_OdEntrySendInterval 50;
BA_ "CANzero_SDO_AccessIfOperational" SG_ 1425 BrakeF_OD_SendOdOnBootup 1;
BA_ "CANzero_SDO_AccessIfOperational" SG_ 1425 BrakeF_OD_HeartbeatInterval 1;
BA_ "GenSigStartValue" SG_ 1425 BrakeF_OD_HeartbeatInterval 100.0;
BA_ "CANzero_SDO_Default" SG_ 1425 BrakeF_OD_HeartbeatInterval 100;
BA_ "CANzero_SDO_AccessType" SG_ 1425 BrakeF_OD_DbcVersion 1;
BA_ "CANzero_SDO_AccessIfOperational" SG_ 1425 BrakeF_OD_DbcVersion 1;
BA_ "CANzero_SDO_AccessType" SG_ 1425 BrakeF_OD_StackVersion 1;
BA_ "CANzero_SDO_AccessIfOperational" SG_ 1425 BrakeF_OD_StackVersion 1;
BA_ "CANzero_SDO_AccessType" SG_ 1425 BrakeF_OD_ProtocolVersion 1;
BA_ "CANzero_SDO_AccessIfOperational" SG_ 1425 BrakeF_OD_ProtocolVersion 1;
BA_ "GenSigStartValue" SG_ 1425 BrakeF_OD_ProtocolVersion 1.0;
BA_ "CANzero_SDO_Default" SG_ 1425 BrakeF_OD_ProtocolVersion 1;
BA_ "CANzero_SDO_AccessType" SG_ 1425 BrakeF_OD_NodeStatus 1;
BA_ "CANzero_SDO_AccessIfOperational" SG_ 1425 BrakeF_OD_NodeStatus 1;
BA_ "CANzero_SDO_AccessType" SG_ 1425 BrakeF_OD_NodeID 1;
BA_ "CANzero_SDO_AccessIfOperational" SG_ 1425 BrakeF_OD_NodeID 1;
BA_ "CANzero_SDO_AccessIfOperational" SG_ 1489 BrakeF_OD_BrakeStatus 1;
BA_ "CANzero_SDO_AccessType" SG_ 1489 BrakeF_OD_CoolingPressure 1;
BA_ "CANzero_SDO_AccessIfOperational" SG_ 1489 BrakeF_OD_CoolingPressure 1;
BA_ "GenSigStartValue" SG_ 1489 BrakeF_OD_CoolingPressure 9810.0;
BA_ "CANzero_SDO_Default" SG_ 1489 BrakeF_OD_CoolingPressure -1.9;
BA_ "CANzero_SDO_AccessIfOperational" SG_ 1489 BrakeF_OD_valveUpperTolerance 1;
BA_ "GenSigStartValue" SG_ 1489 BrakeF_OD_valveUpperTolerance 2000.0;
BA_ "CANzero_SDO_Default" SG_ 1489 BrakeF_OD_valveUpperTolerance 10;
BA_ "CANzero_SDO_AccessIfOperational" SG_ 1489 BrakeF_OD_commWatchdog 1;
BA_ "GenSigStartValue" SG_ 1489 BrakeF_OD_commWatchdog 60.0;
BA_ "CANzero_SDO_Default" SG_ 1489 BrakeF_OD_commWatchdog 60;
BA_ "CANzero_SDO_AccessIfOperational" SG_ 1489 BrakeF_OD_counterLimit 1;
BA_ "GenSigStartValue" SG_ 1489 BrakeF_OD_counterLimit 5.0;
BA_ "CANzero_SDO_Default" SG_ 1489 BrakeF_OD_counterLimit 5;
BA_ "CANzero_SDO_AccessIfOperational" SG_ 1489 BrakeF_OD_delay 1;
BA_ "GenSigStartValue" SG_ 1489 BrakeF_OD_delay 10.0;
BA_ "CANzero_SDO_Default" SG_ 1489 BrakeF_OD_delay 5;
BA_ "CANzero_SDO_AccessIfOperational" SG_ 1489 BrakeF_OD_tankUpperControlLimit 1;
BA_ "GenSigStartValue" SG_ 1489 BrakeF_OD_tankUpperControlLimit 3800.0;
BA_ "CANzero_SDO_Default" SG_ 1489 BrakeF_OD_tankUpperControlLimit 19;
BA_ "CANzero_SDO_AccessIfOperational" SG_ 1489 BrakeF_OD_tankLowerControlLimit 1;
BA_ "GenSigStartValue" SG_ 1489 BrakeF_OD_tankLowerControlLimit 1400.0;
BA_ "CANzero_SDO_Default" SG_ 1489 BrakeF_OD_tankLowerControlLimit 7;
BA_ "CANzero_SDO_Group" SG_ 1489 BrakeF_OD_CAN2_DelayedTxMessages "CAN";
BA_ "CANzero_SDO_AccessType" SG_ 1489 BrakeF_OD_CAN2_DelayedTxMessages 1;
BA_ "CANzero_SDO_AccessIfOperational" SG_ 1489 BrakeF_OD_CAN2_DelayedTxMessages 1;
BA_ "CANzero_SDO_Group" SG_ 1489 BrakeF_OD_CAN2_ErrorStatus "CAN";
BA_ "CANzero_SDO_AccessType" SG_ 1489 BrakeF_OD_CAN2_ErrorStatus 1;
BA_ "CANzero_SDO_AccessIfOperational" SG_ 1489 BrakeF_OD_CAN2_ErrorStatus 1;
BA_ "CANzero_SDO_Group" SG_ 1489 BrakeF_OD_CAN2_DiscardedTxM_0000 "CAN";
BA_ "CANzero_SDO_AccessType" SG_ 1489 BrakeF_OD_CAN2_DiscardedTxM_0000 1;
BA_ "CANzero_SDO_AccessIfOperational" SG_ 1489 BrakeF_OD_CAN2_DiscardedTxM_0000 1;
BA_ "SystemSignalLongSymbol" SG_ 1489 BrakeF_OD_CAN2_DiscardedTxM_0000 "BrakeF_OD_CAN2_DiscardedTxMessages";
BA_ "CANzero_SDO_Group" SG_ 1489 BrakeF_OD_CAN2_Status "CAN";
BA_ "CANzero_SDO_AccessType" SG_ 1489 BrakeF_OD_CAN2_Status 1;
BA_ "CANzero_SDO_AccessIfOperational" SG_ 1489 BrakeF_OD_CAN2_Status 1;
BA_ "CANzero_SDO_Group" SG_ 1489 BrakeF_OD_CAN2_Baudrate "CAN";
BA_ "CANzero_SDO_AccessIfOperational" SG_ 1489 BrakeF_OD_CAN2_Baudrate 1;
BA_ "GenSigStartValue" SG_ 1489 BrakeF_OD_CAN2_Baudrate 1000.0;
BA_ "CANzero_SDO_Default" SG_ 1489 BrakeF_OD_CAN2_Baudrate 1000;
BA_ "CANzero_SDO_Group" SG_ 1489 BrakeF_OD_CAN2_autoErrorReset "CAN";
BA_ "CANzero_SDO_AccessIfOperational" SG_ 1489 BrakeF_OD_CAN2_autoErrorReset 1;
BA_ "GenSigStartValue" SG_ 1489 BrakeF_OD_CAN2_autoErrorReset 1.0;
BA_ "CANzero_SDO_Default" SG_ 1489 BrakeF_OD_CAN2_autoErrorReset 1;
BA_ "CANzero_SDO_Group" SG_ 1489 BrakeF_OD_CAN2_lastErrorCode "CAN";
BA_ "CANzero_SDO_AccessType" SG_ 1489 BrakeF_OD_CAN2_lastErrorCode 1;
BA_ "CANzero_SDO_AccessIfOperational" SG_ 1489 BrakeF_OD_CAN2_lastErrorCode 1;
BA_ "CANzero_SDO_Group" SG_ 1489 BrakeF_OD_CAN2_RxErrCnt "CAN";
BA_ "CANzero_SDO_AccessType" SG_ 1489 BrakeF_OD_CAN2_RxErrCnt 1;
BA_ "CANzero_SDO_AccessIfOperational" SG_ 1489 BrakeF_OD_CAN2_RxErrCnt 1;
BA_ "CANzero_SDO_Group" SG_ 1489 BrakeF_OD_CAN2_TxErrCnt "CAN";
BA_ "CANzero_SDO_AccessType" SG_ 1489 BrakeF_OD_CAN2_TxErrCnt 1;
BA_ "CANzero_SDO_AccessIfOperational" SG_ 1489 BrakeF_OD_CAN2_TxErrCnt 1;
BA_ "CANzero_SDO_Group" SG_ 1489 BrakeF_OD_CAN1_DelayedTxMessages "CAN";
BA_ "CANzero_SDO_AccessType" SG_ 1489 BrakeF_OD_CAN1_DelayedTxMessages 1;
BA_ "CANzero_SDO_AccessIfOperational" SG_ 1489 BrakeF_OD_CAN1_DelayedTxMessages 1;
BA_ "CANzero_SDO_Group" SG_ 1489 BrakeF_OD_CAN1_ErrorStatus "CAN";
BA_ "CANzero_SDO_AccessType" SG_ 1489 BrakeF_OD_CAN1_ErrorStatus 1;
BA_ "CANzero_SDO_AccessIfOperational" SG_ 1489 BrakeF_OD_CAN1_ErrorStatus 1;
BA_ "CANzero_SDO_Group" SG_ 1489 BrakeF_OD_CAN1_DiscardedTxM_0000 "CAN";
BA_ "CANzero_SDO_AccessType" SG_ 1489 BrakeF_OD_CAN1_DiscardedTxM_0000 1;
BA_ "CANzero_SDO_AccessIfOperational" SG_ 1489 BrakeF_OD_CAN1_DiscardedTxM_0000 1;
BA_ "SystemSignalLongSymbol" SG_ 1489 BrakeF_OD_CAN1_DiscardedTxM_0000 "BrakeF_OD_CAN1_DiscardedTxMessages";
BA_ "CANzero_SDO_Group" SG_ 1489 BrakeF_OD_CAN1_Status "CAN";
BA_ "CANzero_SDO_AccessType" SG_ 1489 BrakeF_OD_CAN1_Status 1;
BA_ "CANzero_SDO_AccessIfOperational" SG_ 1489 BrakeF_OD_CAN1_Status 1;
BA_ "CANzero_SDO_Group" SG_ 1489 BrakeF_OD_CAN1_Baudrate "CAN";
BA_ "CANzero_SDO_AccessIfOperational" SG_ 1489 BrakeF_OD_CAN1_Baudrate 1;
BA_ "GenSigStartValue" SG_ 1489 BrakeF_OD_CAN1_Baudrate 1000.0;
BA_ "CANzero_SDO_Default" SG_ 1489 BrakeF_OD_CAN1_Baudrate 1000;
BA_ "CANzero_SDO_Group" SG_ 1489 BrakeF_OD_CAN1_autoErrorReset "CAN";
BA_ "CANzero_SDO_AccessIfOperational" SG_ 1489 BrakeF_OD_CAN1_autoErrorReset 1;
BA_ "GenSigStartValue" SG_ 1489 BrakeF_OD_CAN1_autoErrorReset 1.0;
BA_ "CANzero_SDO_Default" SG_ 1489 BrakeF_OD_CAN1_autoErrorReset 1;
BA_ "CANzero_SDO_Group" SG_ 1489 BrakeF_OD_CAN1_lastErrorCode "CAN";
BA_ "CANzero_SDO_AccessType" SG_ 1489 BrakeF_OD_CAN1_lastErrorCode 1;
BA_ "CANzero_SDO_AccessIfOperational" SG_ 1489 BrakeF_OD_CAN1_lastErrorCode 1;
BA_ "CANzero_SDO_Group" SG_ 1489 BrakeF_OD_CAN1_RxErrCnt "CAN";
BA_ "CANzero_SDO_AccessType" SG_ 1489 BrakeF_OD_CAN1_RxErrCnt 1;
BA_ "CANzero_SDO_AccessIfOperational" SG_ 1489 BrakeF_OD_CAN1_RxErrCnt 1;
BA_ "CANzero_SDO_Group" SG_ 1489 BrakeF_OD_CAN1_TxErrCnt "CAN";
BA_ "CANzero_SDO_AccessType" SG_ 1489 BrakeF_OD_CAN1_TxErrCnt 1;
BA_ "CANzero_SDO_AccessIfOperational" SG_ 1489 BrakeF_OD_CAN1_TxErrCnt 1;
BA_ "CANzero_SDO_AccessType" SG_ 1489 BrakeF_OD_BuildTime 1;
BA_ "CANzero_SDO_AccessIfOperational" SG_ 1489 BrakeF_OD_BuildTime 1;
BA_ "CANzero_SDO_AccessType" SG_ 1489 BrakeF_OD_BuildDate 1;
BA_ "CANzero_SDO_AccessIfOperational" SG_ 1489 BrakeF_OD_BuildDate 1;
BA_ "CANzero_SDO_AccessType" SG_ 1489 BrakeF_OD_ChipUID2 1;
BA_ "CANzero_SDO_AccessIfOperational" SG_ 1489 BrakeF_OD_ChipUID2 1;
BA_ "CANzero_SDO_AccessType" SG_ 1489 BrakeF_OD_ChipUID1 1;
BA_ "CANzero_SDO_AccessIfOperational" SG_ 1489 BrakeF_OD_ChipUID1 1;
BA_ "CANzero_SDO_AccessType" SG_ 1489 BrakeF_OD_SdcOut 1;
BA_ "CANzero_SDO_AccessIfOperational" SG_ 1489 BrakeF_OD_SdcOut 1;
BA_ "CANzero_SDO_AccessType" SG_ 1489 BrakeF_OD_SdcIn 1;
BA_ "CANzero_SDO_AccessIfOperational" SG_ 1489 BrakeF_OD_SdcIn 1;
BA_ "CANzero_SDO_AccessType" SG_ 1489 BrakeF_OD_runtime 1;
BA_ "CANzero_SDO_AccessIfOperational" SG_ 1489 BrakeF_OD_runtime 1;
BA_ "CANzero_SDO_AccessType" SG_ 1489 BrakeF_OD_InputVoltage 1;
BA_ "CANzero_SDO_AccessIfOperational" SG_ 1489 BrakeF_OD_InputVoltage 1;
BA_ "CANzero_SDO_AccessType" SG_ 1489 BrakeF_OD_BoardTemp 1;
BA_ "CANzero_SDO_AccessIfOperational" SG_ 1489 BrakeF_OD_BoardTemp 1;
BA_ "GenSigStartValue" SG_ 1489 BrakeF_OD_BoardTemp 3000.0;
BA_ "CANzero_SDO_AccessType" SG_ 1489 BrakeF_OD_MemFree 1;
BA_ "CANzero_SDO_AccessIfOperational" SG_ 1489 BrakeF_OD_MemFree 1;
BA_ "CANzero_SDO_AccessType" SG_ 1489 BrakeF_OD_CpuUsage 1;
BA_ "CANzero_SDO_AccessIfOperational" SG_ 1489 BrakeF_OD_CpuUsage 1;
BA_ "CANzero_SDO_AccessIfOperational" SG_ 1489 BrakeF_OD_OdEntrySendInterval 1;
BA_ "GenSigStartValue" SG_ 1489 BrakeF_OD_OdEntrySendInterval 50.0;
BA_ "CANzero_SDO_Default" SG_ 1489 BrakeF_OD_OdEntrySendInterval 50;
BA_ "CANzero_SDO_AccessIfOperational" SG_ 1489 BrakeF_OD_SendOdOnBootup 1;
BA_ "CANzero_SDO_AccessIfOperational" SG_ 1489 BrakeF_OD_HeartbeatInterval 1;
BA_ "GenSigStartValue" SG_ 1489 BrakeF_OD_HeartbeatInterval 100.0;
BA_ "CANzero_SDO_Default" SG_ 1489 BrakeF_OD_HeartbeatInterval 100;
BA_ "CANzero_SDO_AccessType" SG_ 1489 BrakeF_OD_DbcVersion 1;
BA_ "CANzero_SDO_AccessIfOperational" SG_ 1489 BrakeF_OD_DbcVersion 1;
BA_ "CANzero_SDO_AccessType" SG_ 1489 BrakeF_OD_StackVersion 1;
BA_ "CANzero_SDO_AccessIfOperational" SG_ 1489 BrakeF_OD_StackVersion 1;
BA_ "CANzero_SDO_AccessType" SG_ 1489 BrakeF_OD_ProtocolVersion 1;
BA_ "CANzero_SDO_AccessIfOperational" SG_ 1489 BrakeF_OD_ProtocolVersion 1;
BA_ "GenSigStartValue" SG_ 1489 BrakeF_OD_ProtocolVersion 1.0;
BA_ "CANzero_SDO_Default" SG_ 1489 BrakeF_OD_ProtocolVersion 1;
BA_ "CANzero_SDO_AccessType" SG_ 1489 BrakeF_OD_NodeStatus 1;
BA_ "CANzero_SDO_AccessIfOperational" SG_ 1489 BrakeF_OD_NodeStatus 1;
BA_ "CANzero_SDO_AccessType" SG_ 1489 BrakeF_OD_NodeID 1;
BA_ "CANzero_SDO_AccessIfOperational" SG_ 1489 BrakeF_OD_NodeID 1;
BA_ "SystemSignalLongSymbol" SG_ 146 BrakeR_E5_retractUnsuccesful_ope "BrakeR_E5_retractUnsuccesful_openSDC";
BA_ "SystemSignalLongSymbol" SG_ 146 BrakeR_E4_retractUnsuccesful_not "BrakeR_E4_retractUnsuccesful_notEnabled";
BA_ "SystemSignalLongSymbol" SG_ 146 BrakeR_E3_retractUnsuccesful_err "BrakeR_E3_retractUnsuccesful_errorFlag";
BA_ "SystemSignalLongSymbol" SG_ 146 BrakeR_W1_highPressureRetracting "BrakeR_W1_highPressureRetractingChamber";
BA_ "SystemSignalLongSymbol" SG_ 146 BrakeR_W0_highPressureActingCham "BrakeR_W0_highPressureActingChamber";
BA_ "GenSigStartValue" SG_ 1106 BrakeR_TX_Pressure_Tank 400;
BA_ "GenSigStartValue" SG_ 1106 BrakeR_TX_Pressure_Retract 400;
BA_ "GenSigStartValue" SG_ 1106 BrakeR_TX_Pressure_Act 400;
BA_ "CANzero_SDO_AccessIfOperational" SG_ 1426 BrakeR_OD_valveUpperTolerance 1;
BA_ "GenSigStartValue" SG_ 1426 BrakeR_OD_valveUpperTolerance 2000.0;
BA_ "CANzero_SDO_Default" SG_ 1426 BrakeR_OD_valveUpperTolerance 10;
BA_ "CANzero_SDO_AccessIfOperational" SG_ 1426 BrakeR_OD_commWatchdog 1;
BA_ "GenSigStartValue" SG_ 1426 BrakeR_OD_commWatchdog 60.0;
BA_ "CANzero_SDO_Default" SG_ 1426 BrakeR_OD_commWatchdog 60;
BA_ "CANzero_SDO_AccessIfOperational" SG_ 1426 BrakeR_OD_counterLimit 1;
BA_ "GenSigStartValue" SG_ 1426 BrakeR_OD_counterLimit 5.0;
BA_ "CANzero_SDO_Default" SG_ 1426 BrakeR_OD_counterLimit 5;
BA_ "CANzero_SDO_AccessIfOperational" SG_ 1426 BrakeR_OD_delay 1;
BA_ "GenSigStartValue" SG_ 1426 BrakeR_OD_delay 10.0;
BA_ "CANzero_SDO_Default" SG_ 1426 BrakeR_OD_delay 5;
BA_ "CANzero_SDO_AccessIfOperational" SG_ 1426 BrakeR_OD_tankUpperControlLimit 1;
BA_ "GenSigStartValue" SG_ 1426 BrakeR_OD_tankUpperControlLimit 3800.0;
BA_ "CANzero_SDO_Default" SG_ 1426 BrakeR_OD_tankUpperControlLimit 19;
BA_ "CANzero_SDO_AccessIfOperational" SG_ 1426 BrakeR_OD_tankLowerControlLimit 1;
BA_ "GenSigStartValue" SG_ 1426 BrakeR_OD_tankLowerControlLimit 1400.0;
BA_ "CANzero_SDO_Default" SG_ 1426 BrakeR_OD_tankLowerControlLimit 7;
BA_ "CANzero_SDO_Group" SG_ 1426 BrakeR_OD_CAN2_DelayedTxMessages "CAN";
BA_ "CANzero_SDO_AccessType" SG_ 1426 BrakeR_OD_CAN2_DelayedTxMessages 1;
BA_ "CANzero_SDO_AccessIfOperational" SG_ 1426 BrakeR_OD_CAN2_DelayedTxMessages 1;
BA_ "CANzero_SDO_Group" SG_ 1426 BrakeR_OD_CAN2_ErrorStatus "CAN";
BA_ "CANzero_SDO_AccessType" SG_ 1426 BrakeR_OD_CAN2_ErrorStatus 1;
BA_ "CANzero_SDO_AccessIfOperational" SG_ 1426 BrakeR_OD_CAN2_ErrorStatus 1;
BA_ "CANzero_SDO_Group" SG_ 1426 BrakeR_OD_CAN2_DiscardedTxMessag "CAN";
BA_ "CANzero_SDO_AccessType" SG_ 1426 BrakeR_OD_CAN2_DiscardedTxMessag 1;
BA_ "CANzero_SDO_AccessIfOperational" SG_ 1426 BrakeR_OD_CAN2_DiscardedTxMessag 1;
BA_ "SystemSignalLongSymbol" SG_ 1426 BrakeR_OD_CAN2_DiscardedTxMessag "BrakeR_OD_CAN2_DiscardedTxMessages";
BA_ "CANzero_SDO_Group" SG_ 1426 BrakeR_OD_CAN2_Status "CAN";
BA_ "CANzero_SDO_AccessType" SG_ 1426 BrakeR_OD_CAN2_Status 1;
BA_ "CANzero_SDO_AccessIfOperational" SG_ 1426 BrakeR_OD_CAN2_Status 1;
BA_ "CANzero_SDO_Group" SG_ 1426 BrakeR_OD_CAN2_Baudrate "CAN";
BA_ "CANzero_SDO_AccessIfOperational" SG_ 1426 BrakeR_OD_CAN2_Baudrate 1;
BA_ "GenSigStartValue" SG_ 1426 BrakeR_OD_CAN2_Baudrate 1000.0;
BA_ "CANzero_SDO_Default" SG_ 1426 BrakeR_OD_CAN2_Baudrate 1000;
BA_ "CANzero_SDO_Group" SG_ 1426 BrakeR_OD_CAN2_autoErrorReset "CAN";
BA_ "CANzero_SDO_AccessIfOperational" SG_ 1426 BrakeR_OD_CAN2_autoErrorReset 1;
BA_ "GenSigStartValue" SG_ 1426 BrakeR_OD_CAN2_autoErrorReset 1.0;
BA_ "CANzero_SDO_Default" SG_ 1426 BrakeR_OD_CAN2_autoErrorReset 1;
BA_ "CANzero_SDO_Group" SG_ 1426 BrakeR_OD_CAN2_lastErrorCode "CAN";
BA_ "CANzero_SDO_AccessType" SG_ 1426 BrakeR_OD_CAN2_lastErrorCode 1;
BA_ "CANzero_SDO_AccessIfOperational" SG_ 1426 BrakeR_OD_CAN2_lastErrorCode 1;
BA_ "CANzero_SDO_Group" SG_ 1426 BrakeR_OD_CAN2_RxErrCnt "CAN";
BA_ "CANzero_SDO_AccessType" SG_ 1426 BrakeR_OD_CAN2_RxErrCnt 1;
BA_ "CANzero_SDO_AccessIfOperational" SG_ 1426 BrakeR_OD_CAN2_RxErrCnt 1;
BA_ "CANzero_SDO_Group" SG_ 1426 BrakeR_OD_CAN2_TxErrCnt "CAN";
BA_ "CANzero_SDO_AccessType" SG_ 1426 BrakeR_OD_CAN2_TxErrCnt 1;
BA_ "CANzero_SDO_AccessIfOperational" SG_ 1426 BrakeR_OD_CAN2_TxErrCnt 1;
BA_ "CANzero_SDO_Group" SG_ 1426 BrakeR_OD_CAN1_DelayedTxMessages "CAN";
BA_ "CANzero_SDO_AccessType" SG_ 1426 BrakeR_OD_CAN1_DelayedTxMessages 1;
BA_ "CANzero_SDO_AccessIfOperational" SG_ 1426 BrakeR_OD_CAN1_DelayedTxMessages 1;
BA_ "CANzero_SDO_Group" SG_ 1426 BrakeR_OD_CAN1_ErrorStatus "CAN";
BA_ "CANzero_SDO_AccessType" SG_ 1426 BrakeR_OD_CAN1_ErrorStatus 1;
BA_ "CANzero_SDO_AccessIfOperational" SG_ 1426 BrakeR_OD_CAN1_ErrorStatus 1;
BA_ "CANzero_SDO_Group" SG_ 1426 BrakeR_OD_CAN1_DiscardedTxMessag "CAN";
BA_ "CANzero_SDO_AccessType" SG_ 1426 BrakeR_OD_CAN1_DiscardedTxMessag 1;
BA_ "CANzero_SDO_AccessIfOperational" SG_ 1426 BrakeR_OD_CAN1_DiscardedTxMessag 1;
BA_ "SystemSignalLongSymbol" SG_ 1426 BrakeR_OD_CAN1_DiscardedTxMessag "BrakeR_OD_CAN1_DiscardedTxMessages";
BA_ "CANzero_SDO_Group" SG_ 1426 BrakeR_OD_CAN1_Status "CAN";
BA_ "CANzero_SDO_AccessType" SG_ 1426 BrakeR_OD_CAN1_Status 1;
BA_ "CANzero_SDO_AccessIfOperational" SG_ 1426 BrakeR_OD_CAN1_Status 1;
BA_ "CANzero_SDO_Group" SG_ 1426 BrakeR_OD_CAN1_Baudrate "CAN";
BA_ "CANzero_SDO_AccessIfOperational" SG_ 1426 BrakeR_OD_CAN1_Baudrate 1;
BA_ "GenSigStartValue" SG_ 1426 BrakeR_OD_CAN1_Baudrate 1000.0;
BA_ "CANzero_SDO_Default" SG_ 1426 BrakeR_OD_CAN1_Baudrate 1000;
BA_ "CANzero_SDO_Group" SG_ 1426 BrakeR_OD_CAN1_autoErrorReset "CAN";
BA_ "CANzero_SDO_AccessIfOperational" SG_ 1426 BrakeR_OD_CAN1_autoErrorReset 1;
BA_ "GenSigStartValue" SG_ 1426 BrakeR_OD_CAN1_autoErrorReset 1.0;
BA_ "CANzero_SDO_Default" SG_ 1426 BrakeR_OD_CAN1_autoErrorReset 1;
BA_ "CANzero_SDO_Group" SG_ 1426 BrakeR_OD_CAN1_lastErrorCode "CAN";
BA_ "CANzero_SDO_AccessType" SG_ 1426 BrakeR_OD_CAN1_lastErrorCode 1;
BA_ "CANzero_SDO_AccessIfOperational" SG_ 1426 BrakeR_OD_CAN1_lastErrorCode 1;
BA_ "CANzero_SDO_Group" SG_ 1426 BrakeR_OD_CAN1_RxErrCnt "CAN";
BA_ "CANzero_SDO_AccessType" SG_ 1426 BrakeR_OD_CAN1_RxErrCnt 1;
BA_ "CANzero_SDO_AccessIfOperational" SG_ 1426 BrakeR_OD_CAN1_RxErrCnt 1;
BA_ "CANzero_SDO_Group" SG_ 1426 BrakeR_OD_CAN1_TxErrCnt "CAN";
BA_ "CANzero_SDO_AccessType" SG_ 1426 BrakeR_OD_CAN1_TxErrCnt 1;
BA_ "CANzero_SDO_AccessIfOperational" SG_ 1426 BrakeR_OD_CAN1_TxErrCnt 1;
BA_ "CANzero_SDO_AccessType" SG_ 1426 BrakeR_OD_BuildTime 1;
BA_ "CANzero_SDO_AccessIfOperational" SG_ 1426 BrakeR_OD_BuildTime 1;
BA_ "CANzero_SDO_AccessType" SG_ 1426 BrakeR_OD_BuildDate 1;
BA_ "CANzero_SDO_AccessIfOperational" SG_ 1426 BrakeR_OD_BuildDate 1;
BA_ "CANzero_SDO_AccessType" SG_ 1426 BrakeR_OD_ChipUID2 1;
BA_ "CANzero_SDO_AccessIfOperational" SG_ 1426 BrakeR_OD_ChipUID2 1;
BA_ "CANzero_SDO_AccessType" SG_ 1426 BrakeR_OD_ChipUID1 1;
BA_ "CANzero_SDO_AccessIfOperational" SG_ 1426 BrakeR_OD_ChipUID1 1;
BA_ "CANzero_SDO_AccessType" SG_ 1426 BrakeR_OD_SdcOut 1;
BA_ "CANzero_SDO_AccessIfOperational" SG_ 1426 BrakeR_OD_SdcOut 1;
BA_ "CANzero_SDO_AccessType" SG_ 1426 BrakeR_OD_SdcIn 1;
BA_ "CANzero_SDO_AccessIfOperational" SG_ 1426 BrakeR_OD_SdcIn 1;
BA_ "CANzero_SDO_AccessType" SG_ 1426 BrakeR_OD_runtime 1;
BA_ "CANzero_SDO_AccessIfOperational" SG_ 1426 BrakeR_OD_runtime 1;
BA_ "CANzero_SDO_AccessType" SG_ 1426 BrakeR_OD_InputVoltage 1;
BA_ "CANzero_SDO_AccessIfOperational" SG_ 1426 BrakeR_OD_InputVoltage 1;
BA_ "CANzero_SDO_AccessType" SG_ 1426 BrakeR_OD_BoardTemp 1;
BA_ "CANzero_SDO_AccessIfOperational" SG_ 1426 BrakeR_OD_BoardTemp 1;
BA_ "GenSigStartValue" SG_ 1426 BrakeR_OD_BoardTemp 3000.0;
BA_ "CANzero_SDO_AccessType" SG_ 1426 BrakeR_OD_MemFree 1;
BA_ "CANzero_SDO_AccessIfOperational" SG_ 1426 BrakeR_OD_MemFree 1;
BA_ "CANzero_SDO_AccessType" SG_ 1426 BrakeR_OD_CpuUsage 1;
BA_ "CANzero_SDO_AccessIfOperational" SG_ 1426 BrakeR_OD_CpuUsage 1;
BA_ "CANzero_SDO_AccessIfOperational" SG_ 1426 BrakeR_OD_OdEntrySendInterval 1;
BA_ "GenSigStartValue" SG_ 1426 BrakeR_OD_OdEntrySendInterval 50.0;
BA_ "CANzero_SDO_Default" SG_ 1426 BrakeR_OD_OdEntrySendInterval 50;
BA_ "CANzero_SDO_AccessIfOperational" SG_ 1426 BrakeR_OD_SendOdOnBootup 1;
BA_ "CANzero_SDO_AccessIfOperational" SG_ 1426 BrakeR_OD_HeartbeatInterval 1;
BA_ "GenSigStartValue" SG_ 1426 BrakeR_OD_HeartbeatInterval 100.0;
BA_ "CANzero_SDO_Default" SG_ 1426 BrakeR_OD_HeartbeatInterval 100;
BA_ "CANzero_SDO_AccessType" SG_ 1426 BrakeR_OD_DbcVersion 1;
BA_ "CANzero_SDO_AccessIfOperational" SG_ 1426 BrakeR_OD_DbcVersion 1;
BA_ "CANzero_SDO_AccessType" SG_ 1426 BrakeR_OD_StackVersion 1;
BA_ "CANzero_SDO_AccessIfOperational" SG_ 1426 BrakeR_OD_StackVersion 1;
BA_ "CANzero_SDO_AccessType" SG_ 1426 BrakeR_OD_ProtocolVersion 1;
BA_ "CANzero_SDO_AccessIfOperational" SG_ 1426 BrakeR_OD_ProtocolVersion 1;
BA_ "GenSigStartValue" SG_ 1426 BrakeR_OD_ProtocolVersion 1.0;
BA_ "CANzero_SDO_Default" SG_ 1426 BrakeR_OD_ProtocolVersion 1;
BA_ "CANzero_SDO_AccessType" SG_ 1426 BrakeR_OD_NodeStatus 1;
BA_ "CANzero_SDO_AccessIfOperational" SG_ 1426 BrakeR_OD_NodeStatus 1;
BA_ "CANzero_SDO_AccessType" SG_ 1426 BrakeR_OD_NodeID 1;
BA_ "CANzero_SDO_AccessIfOperational" SG_ 1426 BrakeR_OD_NodeID 1;
BA_ "CANzero_SDO_AccessIfOperational" SG_ 1490 BrakeR_OD_valveUpperTolerance 1;
BA_ "GenSigStartValue" SG_ 1490 BrakeR_OD_valveUpperTolerance 2000.0;
BA_ "CANzero_SDO_Default" SG_ 1490 BrakeR_OD_valveUpperTolerance 10;
BA_ "CANzero_SDO_AccessIfOperational" SG_ 1490 BrakeR_OD_commWatchdog 1;
BA_ "GenSigStartValue" SG_ 1490 BrakeR_OD_commWatchdog 60.0;
BA_ "CANzero_SDO_Default" SG_ 1490 BrakeR_OD_commWatchdog 60;
BA_ "CANzero_SDO_AccessIfOperational" SG_ 1490 BrakeR_OD_counterLimit 1;
BA_ "GenSigStartValue" SG_ 1490 BrakeR_OD_counterLimit 5.0;
BA_ "CANzero_SDO_Default" SG_ 1490 BrakeR_OD_counterLimit 5;
BA_ "CANzero_SDO_AccessIfOperational" SG_ 1490 BrakeR_OD_delay 1;
BA_ "GenSigStartValue" SG_ 1490 BrakeR_OD_delay 10.0;
BA_ "CANzero_SDO_Default" SG_ 1490 BrakeR_OD_delay 5;
BA_ "CANzero_SDO_AccessIfOperational" SG_ 1490 BrakeR_OD_tankUpperControlLimit 1;
BA_ "GenSigStartValue" SG_ 1490 BrakeR_OD_tankUpperControlLimit 3800.0;
BA_ "CANzero_SDO_Default" SG_ 1490 BrakeR_OD_tankUpperControlLimit 19;
BA_ "CANzero_SDO_AccessIfOperational" SG_ 1490 BrakeR_OD_tankLowerControlLimit 1;
BA_ "GenSigStartValue" SG_ 1490 BrakeR_OD_tankLowerControlLimit 1400.0;
BA_ "CANzero_SDO_Default" SG_ 1490 BrakeR_OD_tankLowerControlLimit 7;
BA_ "CANzero_SDO_Group" SG_ 1490 BrakeR_OD_CAN2_DelayedTxMessages "CAN";
BA_ "CANzero_SDO_AccessType" SG_ 1490 BrakeR_OD_CAN2_DelayedTxMessages 1;
BA_ "CANzero_SDO_AccessIfOperational" SG_ 1490 BrakeR_OD_CAN2_DelayedTxMessages 1;
BA_ "CANzero_SDO_Group" SG_ 1490 BrakeR_OD_CAN2_ErrorStatus "CAN";
BA_ "CANzero_SDO_AccessType" SG_ 1490 BrakeR_OD_CAN2_ErrorStatus 1;
BA_ "CANzero_SDO_AccessIfOperational" SG_ 1490 BrakeR_OD_CAN2_ErrorStatus 1;
BA_ "CANzero_SDO_Group" SG_ 1490 BrakeR_OD_CAN2_DiscardedTxM_0000 "CAN";
BA_ "CANzero_SDO_AccessType" SG_ 1490 BrakeR_OD_CAN2_DiscardedTxM_0000 1;
BA_ "CANzero_SDO_AccessIfOperational" SG_ 1490 BrakeR_OD_CAN2_DiscardedTxM_0000 1;
BA_ "SystemSignalLongSymbol" SG_ 1490 BrakeR_OD_CAN2_DiscardedTxM_0000 "BrakeR_OD_CAN2_DiscardedTxMessages";
BA_ "CANzero_SDO_Group" SG_ 1490 BrakeR_OD_CAN2_Status "CAN";
BA_ "CANzero_SDO_AccessType" SG_ 1490 BrakeR_OD_CAN2_Status 1;
BA_ "CANzero_SDO_AccessIfOperational" SG_ 1490 BrakeR_OD_CAN2_Status 1;
BA_ "CANzero_SDO_Group" SG_ 1490 BrakeR_OD_CAN2_Baudrate "CAN";
BA_ "CANzero_SDO_AccessIfOperational" SG_ 1490 BrakeR_OD_CAN2_Baudrate 1;
BA_ "GenSigStartValue" SG_ 1490 BrakeR_OD_CAN2_Baudrate 1000.0;
BA_ "CANzero_SDO_Default" SG_ 1490 BrakeR_OD_CAN2_Baudrate 1000;
BA_ "CANzero_SDO_Group" SG_ 1490 BrakeR_OD_CAN2_autoErrorReset "CAN";
BA_ "CANzero_SDO_AccessIfOperational" SG_ 1490 BrakeR_OD_CAN2_autoErrorReset 1;
BA_ "GenSigStartValue" SG_ 1490 BrakeR_OD_CAN2_autoErrorReset 1.0;
BA_ "CANzero_SDO_Default" SG_ 1490 BrakeR_OD_CAN2_autoErrorReset 1;
BA_ "CANzero_SDO_Group" SG_ 1490 BrakeR_OD_CAN2_lastErrorCode "CAN";
BA_ "CANzero_SDO_AccessType" SG_ 1490 BrakeR_OD_CAN2_lastErrorCode 1;
BA_ "CANzero_SDO_AccessIfOperational" SG_ 1490 BrakeR_OD_CAN2_lastErrorCode 1;
BA_ "CANzero_SDO_Group" SG_ 1490 BrakeR_OD_CAN2_RxErrCnt "CAN";
BA_ "CANzero_SDO_AccessType" SG_ 1490 BrakeR_OD_CAN2_RxErrCnt 1;
BA_ "CANzero_SDO_AccessIfOperational" SG_ 1490 BrakeR_OD_CAN2_RxErrCnt 1;
BA_ "CANzero_SDO_Group" SG_ 1490 BrakeR_OD_CAN2_TxErrCnt "CAN";
BA_ "CANzero_SDO_AccessType" SG_ 1490 BrakeR_OD_CAN2_TxErrCnt 1;
BA_ "CANzero_SDO_AccessIfOperational" SG_ 1490 BrakeR_OD_CAN2_TxErrCnt 1;
BA_ "CANzero_SDO_Group" SG_ 1490 BrakeR_OD_CAN1_DelayedTxMessages "CAN";
BA_ "CANzero_SDO_AccessType" SG_ 1490 BrakeR_OD_CAN1_DelayedTxMessages 1;
BA_ "CANzero_SDO_AccessIfOperational" SG_ 1490 BrakeR_OD_CAN1_DelayedTxMessages 1;
BA_ "CANzero_SDO_Group" SG_ 1490 BrakeR_OD_CAN1_ErrorStatus "CAN";
BA_ "CANzero_SDO_AccessType" SG_ 1490 BrakeR_OD_CAN1_ErrorStatus 1;
BA_ "CANzero_SDO_AccessIfOperational" SG_ 1490 BrakeR_OD_CAN1_ErrorStatus 1;
BA_ "CANzero_SDO_Group" SG_ 1490 BrakeR_OD_CAN1_DiscardedTxM_0000 "CAN";
BA_ "CANzero_SDO_AccessType" SG_ 1490 BrakeR_OD_CAN1_DiscardedTxM_0000 1;
BA_ "CANzero_SDO_AccessIfOperational" SG_ 1490 BrakeR_OD_CAN1_DiscardedTxM_0000 1;
BA_ "SystemSignalLongSymbol" SG_ 1490 BrakeR_OD_CAN1_DiscardedTxM_0000 "BrakeR_OD_CAN1_DiscardedTxMessages";
BA_ "CANzero_SDO_Group" SG_ 1490 BrakeR_OD_CAN1_Status "CAN";
BA_ "CANzero_SDO_AccessType" SG_ 1490 BrakeR_OD_CAN1_Status 1;
BA_ "CANzero_SDO_AccessIfOperational" SG_ 1490 BrakeR_OD_CAN1_Status 1;
BA_ "CANzero_SDO_Group" SG_ 1490 BrakeR_OD_CAN1_Baudrate "CAN";
BA_ "CANzero_SDO_AccessIfOperational" SG_ 1490 BrakeR_OD_CAN1_Baudrate 1;
BA_ "GenSigStartValue" SG_ 1490 BrakeR_OD_CAN1_Baudrate 1000.0;
BA_ "CANzero_SDO_Default" SG_ 1490 BrakeR_OD_CAN1_Baudrate 1000;
BA_ "CANzero_SDO_Group" SG_ 1490 BrakeR_OD_CAN1_autoErrorReset "CAN";
BA_ "CANzero_SDO_AccessIfOperational" SG_ 1490 BrakeR_OD_CAN1_autoErrorReset 1;
BA_ "GenSigStartValue" SG_ 1490 BrakeR_OD_CAN1_autoErrorReset 1.0;
BA_ "CANzero_SDO_Default" SG_ 1490 BrakeR_OD_CAN1_autoErrorReset 1;
BA_ "CANzero_SDO_Group" SG_ 1490 BrakeR_OD_CAN1_lastErrorCode "CAN";
BA_ "CANzero_SDO_AccessType" SG_ 1490 BrakeR_OD_CAN1_lastErrorCode 1;
BA_ "CANzero_SDO_AccessIfOperational" SG_ 1490 BrakeR_OD_CAN1_lastErrorCode 1;
BA_ "CANzero_SDO_Group" SG_ 1490 BrakeR_OD_CAN1_RxErrCnt "CAN";
BA_ "CANzero_SDO_AccessType" SG_ 1490 BrakeR_OD_CAN1_RxErrCnt 1;
BA_ "CANzero_SDO_AccessIfOperational" SG_ 1490 BrakeR_OD_CAN1_RxErrCnt 1;
BA_ "CANzero_SDO_Group" SG_ 1490 BrakeR_OD_CAN1_TxErrCnt "CAN";
BA_ "CANzero_SDO_AccessType" SG_ 1490 BrakeR_OD_CAN1_TxErrCnt 1;
BA_ "CANzero_SDO_AccessIfOperational" SG_ 1490 BrakeR_OD_CAN1_TxErrCnt 1;
BA_ "CANzero_SDO_AccessType" SG_ 1490 BrakeR_OD_BuildTime 1;
BA_ "CANzero_SDO_AccessIfOperational" SG_ 1490 BrakeR_OD_BuildTime 1;
BA_ "CANzero_SDO_AccessType" SG_ 1490 BrakeR_OD_BuildDate 1;
BA_ "CANzero_SDO_AccessIfOperational" SG_ 1490 BrakeR_OD_BuildDate 1;
BA_ "CANzero_SDO_AccessType" SG_ 1490 BrakeR_OD_ChipUID2 1;
BA_ "CANzero_SDO_AccessIfOperational" SG_ 1490 BrakeR_OD_ChipUID2 1;
BA_ "CANzero_SDO_AccessType" SG_ 1490 BrakeR_OD_ChipUID1 1;
BA_ "CANzero_SDO_AccessIfOperational" SG_ 1490 BrakeR_OD_ChipUID1 1;
BA_ "CANzero_SDO_AccessType" SG_ 1490 BrakeR_OD_SdcOut 1;
BA_ "CANzero_SDO_AccessIfOperational" SG_ 1490 BrakeR_OD_SdcOut 1;
BA_ "CANzero_SDO_AccessType" SG_ 1490 BrakeR_OD_SdcIn 1;
BA_ "CANzero_SDO_AccessIfOperational" SG_ 1490 BrakeR_OD_SdcIn 1;
BA_ "CANzero_SDO_AccessType" SG_ 1490 BrakeR_OD_runtime 1;
BA_ "CANzero_SDO_AccessIfOperational" SG_ 1490 BrakeR_OD_runtime 1;
BA_ "CANzero_SDO_AccessType" SG_ 1490 BrakeR_OD_InputVoltage 1;
BA_ "CANzero_SDO_AccessIfOperational" SG_ 1490 BrakeR_OD_InputVoltage 1;
BA_ "CANzero_SDO_AccessType" SG_ 1490 BrakeR_OD_BoardTemp 1;
BA_ "CANzero_SDO_AccessIfOperational" SG_ 1490 BrakeR_OD_BoardTemp 1;
BA_ "GenSigStartValue" SG_ 1490 BrakeR_OD_BoardTemp 3000.0;
BA_ "CANzero_SDO_AccessType" SG_ 1490 BrakeR_OD_MemFree 1;
BA_ "CANzero_SDO_AccessIfOperational" SG_ 1490 BrakeR_OD_MemFree 1;
BA_ "CANzero_SDO_AccessType" SG_ 1490 BrakeR_OD_CpuUsage 1;
BA_ "CANzero_SDO_AccessIfOperational" SG_ 1490 BrakeR_OD_CpuUsage 1;
BA_ "CANzero_SDO_AccessIfOperational" SG_ 1490 BrakeR_OD_OdEntrySendInterval 1;
BA_ "GenSigStartValue" SG_ 1490 BrakeR_OD_OdEntrySendInterval 50.0;
BA_ "CANzero_SDO_Default" SG_ 1490 BrakeR_OD_OdEntrySendInterval 50;
BA_ "CANzero_SDO_AccessIfOperational" SG_ 1490 BrakeR_OD_SendOdOnBootup 1;
BA_ "CANzero_SDO_AccessIfOperational" SG_ 1490 BrakeR_OD_HeartbeatInterval 1;
BA_ "GenSigStartValue" SG_ 1490 BrakeR_OD_HeartbeatInterval 100.0;
BA_ "CANzero_SDO_Default" SG_ 1490 BrakeR_OD_HeartbeatInterval 100;
BA_ "CANzero_SDO_AccessType" SG_ 1490 BrakeR_OD_DbcVersion 1;
BA_ "CANzero_SDO_AccessIfOperational" SG_ 1490 BrakeR_OD_DbcVersion 1;
BA_ "CANzero_SDO_AccessType" SG_ 1490 BrakeR_OD_StackVersion 1;
BA_ "CANzero_SDO_AccessIfOperational" SG_ 1490 BrakeR_OD_StackVersion 1;
BA_ "CANzero_SDO_AccessType" SG_ 1490 BrakeR_OD_ProtocolVersion 1;
BA_ "CANzero_SDO_AccessIfOperational" SG_ 1490 BrakeR_OD_ProtocolVersion 1;
BA_ "GenSigStartValue" SG_ 1490 BrakeR_OD_ProtocolVersion 1.0;
BA_ "CANzero_SDO_Default" SG_ 1490 BrakeR_OD_ProtocolVersion 1;
BA_ "CANzero_SDO_AccessType" SG_ 1490 BrakeR_OD_NodeStatus 1;
BA_ "CANzero_SDO_AccessIfOperational" SG_ 1490 BrakeR_OD_NodeStatus 1;
BA_ "CANzero_SDO_AccessType" SG_ 1490 BrakeR_OD_NodeID 1;
BA_ "CANzero_SDO_AccessIfOperational" SG_ 1490 BrakeR_OD_NodeID 1;
BA_ "GenSigStartValue" SG_ 602 PDU_LPCh9_Dutycycle 200;
BA_ "GenSigStartValue" SG_ 602 PDU_LPCh8_Dutycycle 200;
BA_ "GenSigStartValue" SG_ 602 PDU_LPCh3_Dutycycle 200;
BA_ "GenSigStartValue" SG_ 602 PDU_LPCh2_Dutycycle 200;
BA_ "GenSigStartValue" SG_ 602 PDU_LPCh10_Dutycycle 200;
BA_ "GenSigStartValue" SG_ 602 PDU_LPCh1_Dutycycle 200;
BA_ "GenSigStartValue" SG_ 730 PDU_D4_Dutycycle 200;
BA_ "GenSigStartValue" SG_ 730 PDU_D3_Dutycycle 200;
BA_ "GenSigStartValue" SG_ 730 PDU_D2_Dutycycle 200;
BA_ "GenSigStartValue" SG_ 730 PDU_D1_Dutycycle 200;
BA_ "GenSigStartValue" SG_ 730 PDU_HPCh2_Dutycycle 200;
BA_ "GenSigStartValue" SG_ 730 PDU_HPCh1_Dutycycle 200;
BA_ "CANzero_SDO_AccessIfOperational" SG_ 1434 PDU_OD_CoolingPumpEnabled 1;
BA_ "GenSigStartValue" SG_ 1434 PDU_OD_CoolingPumpEnabled 1.0;
BA_ "CANzero_SDO_Default" SG_ 1434 PDU_OD_CoolingPumpEnabled 1;
BA_ "CANzero_SDO_AccessIfOperational" SG_ 1434 PDU_OD_LedCommands 1;
BA_ "GenSigStartValue" SG_ 1434 PDU_OD_LedCommands 1.0;
BA_ "CANzero_SDO_Default" SG_ 1434 PDU_OD_LedCommands 1;
BA_ "CANzero_SDO_AccessIfOperational" SG_ 1434 PDU_OD_projectXXEnabled 1;
BA_ "GenSigStartValue" SG_ 1434 PDU_OD_projectXXEnabled 1.0;
BA_ "CANzero_SDO_Default" SG_ 1434 PDU_OD_projectXXEnabled 1;
BA_ "CANzero_SDO_AccessIfOperational" SG_ 1434 PDU_OD_watchdogTimeout 1;
BA_ "GenSigStartValue" SG_ 1434 PDU_OD_watchdogTimeout 25.0;
BA_ "CANzero_SDO_Default" SG_ 1434 PDU_OD_watchdogTimeout 25;
BA_ "CANzero_SDO_AccessIfOperational" SG_ 1434 PDU_OD_statusSendInterval 1;
BA_ "GenSigStartValue" SG_ 1434 PDU_OD_statusSendInterval 20.0;
BA_ "CANzero_SDO_Default" SG_ 1434 PDU_OD_statusSendInterval 20;
BA_ "CANzero_SDO_AccessIfOperational" SG_ 1434 PDU_OD_currentReadInterval 1;
BA_ "GenSigStartValue" SG_ 1434 PDU_OD_currentReadInterval 100.0;
BA_ "CANzero_SDO_Default" SG_ 1434 PDU_OD_currentReadInterval 100;
BA_ "CANzero_SDO_AccessIfOperational" SG_ 1434 PDU_OD_batteryOvercurrent 1;
BA_ "GenSigStartValue" SG_ 1434 PDU_OD_batteryOvercurrent 1500.0;
BA_ "CANzero_SDO_Default" SG_ 1434 PDU_OD_batteryOvercurrent 15;
BA_ "CANzero_SDO_AccessIfOperational" SG_ 1434 PDU_OD_overTempCritical 1;
BA_ "GenSigStartValue" SG_ 1434 PDU_OD_overTempCritical 700.0;
BA_ "CANzero_SDO_Default" SG_ 1434 PDU_OD_overTempCritical 70;
BA_ "CANzero_SDO_AccessIfOperational" SG_ 1434 PDU_OD_overTempWarn 1;
BA_ "GenSigStartValue" SG_ 1434 PDU_OD_overTempWarn 400.0;
BA_ "CANzero_SDO_Default" SG_ 1434 PDU_OD_overTempWarn 40;
BA_ "CANzero_SDO_AccessIfOperational" SG_ 1434 PDU_OD_batterVoltageCritical 1;
BA_ "GenSigStartValue" SG_ 1434 PDU_OD_batterVoltageCritical 2100.0;
BA_ "CANzero_SDO_Default" SG_ 1434 PDU_OD_batterVoltageCritical 21.0;
BA_ "CANzero_SDO_AccessIfOperational" SG_ 1434 PDU_OD_batterVoltageLow 1;
BA_ "GenSigStartValue" SG_ 1434 PDU_OD_batterVoltageLow 2220.0;
BA_ "CANzero_SDO_Default" SG_ 1434 PDU_OD_batterVoltageLow 22.2;
BA_ "CANzero_SDO_Group" SG_ 1434 PDU_OD_CAN2_DelayedTxMessages "CAN";
BA_ "CANzero_SDO_AccessType" SG_ 1434 PDU_OD_CAN2_DelayedTxMessages 1;
BA_ "CANzero_SDO_AccessIfOperational" SG_ 1434 PDU_OD_CAN2_DelayedTxMessages 1;
BA_ "CANzero_SDO_Group" SG_ 1434 PDU_OD_CAN2_ErrorStatus "CAN";
BA_ "CANzero_SDO_AccessType" SG_ 1434 PDU_OD_CAN2_ErrorStatus 1;
BA_ "CANzero_SDO_AccessIfOperational" SG_ 1434 PDU_OD_CAN2_ErrorStatus 1;
BA_ "CANzero_SDO_Group" SG_ 1434 PDU_OD_CAN2_DiscardedTxMessages "CAN";
BA_ "CANzero_SDO_AccessType" SG_ 1434 PDU_OD_CAN2_DiscardedTxMessages 1;
BA_ "CANzero_SDO_AccessIfOperational" SG_ 1434 PDU_OD_CAN2_DiscardedTxMessages 1;
BA_ "CANzero_SDO_Group" SG_ 1434 PDU_OD_CAN2_Status "CAN";
BA_ "CANzero_SDO_AccessType" SG_ 1434 PDU_OD_CAN2_Status 1;
BA_ "CANzero_SDO_AccessIfOperational" SG_ 1434 PDU_OD_CAN2_Status 1;
BA_ "CANzero_SDO_Group" SG_ 1434 PDU_OD_CAN2_Baudrate "CAN";
BA_ "CANzero_SDO_AccessIfOperational" SG_ 1434 PDU_OD_CAN2_Baudrate 1;
BA_ "GenSigStartValue" SG_ 1434 PDU_OD_CAN2_Baudrate 1000.0;
BA_ "CANzero_SDO_Default" SG_ 1434 PDU_OD_CAN2_Baudrate 1000;
BA_ "CANzero_SDO_Group" SG_ 1434 PDU_OD_CAN2_autoErrorReset "CAN";
BA_ "CANzero_SDO_AccessIfOperational" SG_ 1434 PDU_OD_CAN2_autoErrorReset 1;
BA_ "GenSigStartValue" SG_ 1434 PDU_OD_CAN2_autoErrorReset 1.0;
BA_ "CANzero_SDO_Default" SG_ 1434 PDU_OD_CAN2_autoErrorReset 1;
BA_ "CANzero_SDO_Group" SG_ 1434 PDU_OD_CAN2_lastErrorCode "CAN";
BA_ "CANzero_SDO_AccessType" SG_ 1434 PDU_OD_CAN2_lastErrorCode 1;
BA_ "CANzero_SDO_AccessIfOperational" SG_ 1434 PDU_OD_CAN2_lastErrorCode 1;
BA_ "CANzero_SDO_Group" SG_ 1434 PDU_OD_CAN2_RxErrCnt "CAN";
BA_ "CANzero_SDO_AccessType" SG_ 1434 PDU_OD_CAN2_RxErrCnt 1;
BA_ "CANzero_SDO_AccessIfOperational" SG_ 1434 PDU_OD_CAN2_RxErrCnt 1;
BA_ "CANzero_SDO_Group" SG_ 1434 PDU_OD_CAN2_TxErrCnt "CAN";
BA_ "CANzero_SDO_AccessType" SG_ 1434 PDU_OD_CAN2_TxErrCnt 1;
BA_ "CANzero_SDO_AccessIfOperational" SG_ 1434 PDU_OD_CAN2_TxErrCnt 1;
BA_ "CANzero_SDO_Group" SG_ 1434 PDU_OD_CAN1_DelayedTxMessages "CAN";
BA_ "CANzero_SDO_AccessType" SG_ 1434 PDU_OD_CAN1_DelayedTxMessages 1;
BA_ "CANzero_SDO_AccessIfOperational" SG_ 1434 PDU_OD_CAN1_DelayedTxMessages 1;
BA_ "CANzero_SDO_Group" SG_ 1434 PDU_OD_CAN1_ErrorStatus "CAN";
BA_ "CANzero_SDO_AccessType" SG_ 1434 PDU_OD_CAN1_ErrorStatus 1;
BA_ "CANzero_SDO_AccessIfOperational" SG_ 1434 PDU_OD_CAN1_ErrorStatus 1;
BA_ "CANzero_SDO_Group" SG_ 1434 PDU_OD_CAN1_DiscardedTxMessages "CAN";
BA_ "CANzero_SDO_AccessType" SG_ 1434 PDU_OD_CAN1_DiscardedTxMessages 1;
BA_ "CANzero_SDO_AccessIfOperational" SG_ 1434 PDU_OD_CAN1_DiscardedTxMessages 1;
BA_ "CANzero_SDO_Group" SG_ 1434 PDU_OD_CAN1_Status "CAN";
BA_ "CANzero_SDO_AccessType" SG_ 1434 PDU_OD_CAN1_Status 1;
BA_ "CANzero_SDO_AccessIfOperational" SG_ 1434 PDU_OD_CAN1_Status 1;
BA_ "CANzero_SDO_Group" SG_ 1434 PDU_OD_CAN1_Baudrate "CAN";
BA_ "CANzero_SDO_AccessIfOperational" SG_ 1434 PDU_OD_CAN1_Baudrate 1;
BA_ "GenSigStartValue" SG_ 1434 PDU_OD_CAN1_Baudrate 1000.0;
BA_ "CANzero_SDO_Default" SG_ 1434 PDU_OD_CAN1_Baudrate 1000;
BA_ "CANzero_SDO_Group" SG_ 1434 PDU_OD_CAN1_autoErrorReset "CAN";
BA_ "CANzero_SDO_AccessIfOperational" SG_ 1434 PDU_OD_CAN1_autoErrorReset 1;
BA_ "GenSigStartValue" SG_ 1434 PDU_OD_CAN1_autoErrorReset 1.0;
BA_ "CANzero_SDO_Default" SG_ 1434 PDU_OD_CAN1_autoErrorReset 1;
BA_ "CANzero_SDO_Group" SG_ 1434 PDU_OD_CAN1_lastErrorCode "CAN";
BA_ "CANzero_SDO_AccessType" SG_ 1434 PDU_OD_CAN1_lastErrorCode 1;
BA_ "CANzero_SDO_AccessIfOperational" SG_ 1434 PDU_OD_CAN1_lastErrorCode 1;
BA_ "CANzero_SDO_Group" SG_ 1434 PDU_OD_CAN1_RxErrCnt "CAN";
BA_ "CANzero_SDO_AccessType" SG_ 1434 PDU_OD_CAN1_RxErrCnt 1;
BA_ "CANzero_SDO_AccessIfOperational" SG_ 1434 PDU_OD_CAN1_RxErrCnt 1;
BA_ "CANzero_SDO_Group" SG_ 1434 PDU_OD_CAN1_TxErrCnt "CAN";
BA_ "CANzero_SDO_AccessType" SG_ 1434 PDU_OD_CAN1_TxErrCnt 1;
BA_ "CANzero_SDO_AccessIfOperational" SG_ 1434 PDU_OD_CAN1_TxErrCnt 1;
BA_ "CANzero_SDO_AccessType" SG_ 1434 PDU_OD_BuildTime 1;
BA_ "CANzero_SDO_AccessIfOperational" SG_ 1434 PDU_OD_BuildTime 1;
BA_ "CANzero_SDO_AccessType" SG_ 1434 PDU_OD_BuildDate 1;
BA_ "CANzero_SDO_AccessIfOperational" SG_ 1434 PDU_OD_BuildDate 1;
BA_ "CANzero_SDO_AccessType" SG_ 1434 PDU_OD_ChipUID2 1;
BA_ "CANzero_SDO_AccessIfOperational" SG_ 1434 PDU_OD_ChipUID2 1;
BA_ "CANzero_SDO_AccessType" SG_ 1434 PDU_OD_ChipUID1 1;
BA_ "CANzero_SDO_AccessIfOperational" SG_ 1434 PDU_OD_ChipUID1 1;
BA_ "CANzero_SDO_AccessType" SG_ 1434 PDU_OD_SdcOut 1;
BA_ "CANzero_SDO_AccessIfOperational" SG_ 1434 PDU_OD_SdcOut 1;
BA_ "CANzero_SDO_AccessType" SG_ 1434 PDU_OD_SdcIn 1;
BA_ "CANzero_SDO_AccessIfOperational" SG_ 1434 PDU_OD_SdcIn 1;
BA_ "CANzero_SDO_AccessType" SG_ 1434 PDU_OD_runtime 1;
BA_ "CANzero_SDO_AccessIfOperational" SG_ 1434 PDU_OD_runtime 1;
BA_ "CANzero_SDO_AccessType" SG_ 1434 PDU_OD_InputVoltage 1;
BA_ "CANzero_SDO_AccessIfOperational" SG_ 1434 PDU_OD_InputVoltage 1;
BA_ "CANzero_SDO_AccessType" SG_ 1434 PDU_OD_BoardTemp 1;
BA_ "CANzero_SDO_AccessIfOperational" SG_ 1434 PDU_OD_BoardTemp 1;
BA_ "GenSigStartValue" SG_ 1434 PDU_OD_BoardTemp 3000.0;
BA_ "CANzero_SDO_AccessType" SG_ 1434 PDU_OD_MemFree 1;
BA_ "CANzero_SDO_AccessIfOperational" SG_ 1434 PDU_OD_MemFree 1;
BA_ "CANzero_SDO_AccessType" SG_ 1434 PDU_OD_CpuUsage 1;
BA_ "CANzero_SDO_AccessIfOperational" SG_ 1434 PDU_OD_CpuUsage 1;
BA_ "CANzero_SDO_AccessIfOperational" SG_ 1434 PDU_OD_OdEntrySendInterval 1;
BA_ "GenSigStartValue" SG_ 1434 PDU_OD_OdEntrySendInterval 50.0;
BA_ "CANzero_SDO_Default" SG_ 1434 PDU_OD_OdEntrySendInterval 50;
BA_ "CANzero_SDO_AccessIfOperational" SG_ 1434 PDU_OD_SendOdOnBootup 1;
BA_ "CANzero_SDO_AccessIfOperational" SG_ 1434 PDU_OD_HeartbeatInterval 1;
BA_ "GenSigStartValue" SG_ 1434 PDU_OD_HeartbeatInterval 250.0;
BA_ "CANzero_SDO_Default" SG_ 1434 PDU_OD_HeartbeatInterval 250;
BA_ "CANzero_SDO_AccessType" SG_ 1434 PDU_OD_DbcVersion 1;
BA_ "CANzero_SDO_AccessIfOperational" SG_ 1434 PDU_OD_DbcVersion 1;
BA_ "CANzero_SDO_AccessType" SG_ 1434 PDU_OD_StackVersion 1;
BA_ "CANzero_SDO_AccessIfOperational" SG_ 1434 PDU_OD_StackVersion 1;
BA_ "CANzero_SDO_AccessType" SG_ 1434 PDU_OD_ProtocolVersion 1;
BA_ "CANzero_SDO_AccessIfOperational" SG_ 1434 PDU_OD_ProtocolVersion 1;
BA_ "GenSigStartValue" SG_ 1434 PDU_OD_ProtocolVersion 1.0;
BA_ "CANzero_SDO_Default" SG_ 1434 PDU_OD_ProtocolVersion 1;
BA_ "CANzero_SDO_AccessType" SG_ 1434 PDU_OD_NodeStatus 1;
BA_ "CANzero_SDO_AccessIfOperational" SG_ 1434 PDU_OD_NodeStatus 1;
BA_ "CANzero_SDO_AccessType" SG_ 1434 PDU_OD_NodeID 1;
BA_ "CANzero_SDO_AccessIfOperational" SG_ 1434 PDU_OD_NodeID 1;
VAL_ 1474 SensorR_OD_StripeMode 0 "Left" 1 "Right" 2 "Both" ;
VAL_ 1474 SensorR_OD_opc_brakeFlag 0 "None" 1 "Braked" ;
VAL_ 1474 SensorR_OD_AdaptModelByCurrent 0 "Const" 1 "UseCurrent" ;
VAL_ 1474 SensorR_OD_VelocityController 0 "CC" 1 "CVFF" 2 "CVFB" 3 "CAS" 4 "FAST" ;
VAL_ 1474 SensorR_OD_SetFinish 0 "None" 1 "Finish" ;
VAL_ 1474 SensorR_OD_RunMode 0 "Dynamic" 1 "Levitation" 2 "Manual" ;
VAL_ 1474 SensorR_OD_EncoderResetPosition 0 "None" 1 "Reset" ;
VAL_ 1474 SensorR_OD_CAN2_ErrorStatus 0 "Ok" 1 "Warn" 2 "Error Passive" 3 "Bus Off" ;
VAL_ 1474 SensorR_OD_CAN2_Status 0 "Reset" 1 "Ready" 2 "Listening" 3 "Sleep_Pending" 4 "Sleep_Active" 5 "ERROR" ;
VAL_ 1474 SensorR_OD_CAN2_autoErrorReset 0 "Disabled" 1 "Enabled" ;
VAL_ 1474 SensorR_OD_CAN2_lastErrorCode 0 "No Error" 1 "Stuff Error" 2 "Form Error" 3 "Ack Error" 4 "Bit recessive Error" 5 "Bit dominant Error" 6 "CRC Error" ;
VAL_ 1474 SensorR_OD_CAN1_ErrorStatus 0 "Ok" 1 "Warn" 2 "Error Passive" 3 "Bus Off" ;
VAL_ 1474 SensorR_OD_CAN1_Status 0 "Reset" 1 "Ready" 2 "Listening" 3 "Sleep_Pending" 4 "Sleep_Active" 5 "ERROR" ;
VAL_ 1474 SensorR_OD_CAN1_autoErrorReset 0 "Disabled" 1 "Enabled" ;
VAL_ 1474 SensorR_OD_CAN1_lastErrorCode 0 "No Error" 1 "Stuff Error" 2 "Form Error" 3 "Ack Error" 4 "Bit recessive Error" 5 "Bit dominant Error" 6 "CRC Error" ;
VAL_ 1474 SensorR_OD_SendOdOnBootup 0 "Disabled" 1 "Enabled" ;
VAL_ 1474 SensorR_OD_NodeStatus 0 "Bootup" 4 "Stopped" 5 "Operational" 127 "Pre-Operational" 128 "Reset" ;
VAL_ 1474 SensorR_SDO_ID 0 "Reserved" 1 "NodeID" 2 "NodeStatus" 3 "ProtocolVersion" 4 "StackVersion" 5 "DbcVersion" 16 "HeartbeatInterval" 32 "SendOdOnBootup" 33 "OdEntrySendInterval" 1040 "CpuUsage" 1041 "MemFree" 1042 "BoardTemp" 1043 "InputVoltage" 1044 "runtime" 1045 "SdcIn" 1046 "SdcOut" 1056 "ChipUID1" 1057 "ChipUID2" 1072 "BuildDate" 1073 "BuildTime" 1104 "CAN1_TxErrCnt" 1105 "CAN1_RxErrCnt" 1106 "CAN1_lastErrorCode" 1107 "CAN1_autoErrorReset" 1108 "CAN1_Baudrate" 1110 "CAN1_Status" 1111 "CAN1_DiscardedTxMessages" 1112 "CAN1_ErrorStatus" 1113 "CAN1_DelayedTxMessages" 1120 "CAN2_TxErrCnt" 1121 "CAN2_RxErrCnt" 1122 "CAN2_lastErrorCode" 1123 "CAN2_autoErrorReset" 1124 "CAN2_Baudrate" 1126 "CAN2_Status" 1127 "CAN2_DiscardedTxMessages" 1128 "CAN2_ErrorStatus" 1129 "CAN2_DelayedTxMessages" 2048 "samplingInterval" 2576 "EncoderWheelDiameter" 2586 "EncoderResetPosition" 2592 "IMU_number" 2597 "IMU1_Temperature" 2598 "IMU2_Temperature" 2599 "IMU3_Temperature" 2608 "ExecTimeOverall" 2609 "ExecTimeStateEst" 2610 "ExecTimeControl" 2611 "ExecTimeReadSensors" 2624 "OpcKp" 2625 "OpcKi" 2626 "CtrlMode" 2627 "CurrentReq" 2628 "PodMass" 2629 "FmaxCtrl" 2630 "FminCtrl" 2631 "MaxCtrlError" 2632 "MaxCtrlErrorDuration" 2633 "WarningThreshholdForLimModelOutOfBoundaries" 2634 "MaxRequiredVelocity" 2635 "VdcReduceFactor" 2636 "RunMode" 2637 "SetFinish" 2816 "RunProfile_T0" 2817 "RunProfile_V0" 2818 "RunProfile_T1" 2819 "RunProfile_V1" 2820 "RunProfile_T2" 2821 "RunProfile_V2" 2822 "RunProfile_T3" 2823 "RunProfile_V3" 2824 "RunProfile_T4" 2825 "RunProfile_V4" 2826 "EstimatedRunLength" 3072 "TC_I" 3073 "TC_f" 3074 "VelocityController" 3075 "CVOPCImax" 3076 "CVOPCTcf" 3077 "CVOPCTcI" 3078 "CVOPCSmoothingDeltaVelocity" 3079 "CVOPCDeltaVelHigherCurrent" 3080 "CVOPCReduceCurrentWhileCruising" 3081 "CVOPCHystereseF" 3088 "AccAtCurrentMeasured" 3089 "CurrentForConstantVelocity" 3090 "CascadedMaxSetForceDelta" 3091 "CascadedFreqCurUpdate" 3092 "CascadedKpIncreaseCurrent" 3093 "CascadedKpDecreaseCurrent" 3094 "CVOPCImin" 3095 "CVOPCTcFreq" 3096 "AdaptModelByCurrent" 3097 "Current4Stopping" 3104 "FinishedDelay" 3105 "maxRunDistance" 3106 "opc_ratelimiter_f" 3107 "DebugCascadedIreq" 3108 "DebugCVOPCfreq" 3109 "opc_brakeFlag" 3110 "opc_t_run_max" 3111 "opc_F_max" 3112 "opc_T_acc" 3113 "opc_v_max" 3120 "opc_v_threshold" 3121 "opc_F_decrease" 3122 "opc_lowpass_Tcf" 3123 "opc_lowpass_TcI" 3329 "StripeMode" 3330 "ReflectorDistance" 3331 "PositionGlitch" 3332 "EnableSignalGeneration" 3585 "accDeviation" 3586 "velDeviationEncoder" 3587 "velDeviationOptic" 3588 "posDeviationEncoder" 3589 "posDeviationOptic" ;
VAL_ 1538 SensorR_SDO_ID 0 "Reserved" 1 "NodeID" 2 "NodeStatus" 3 "ProtocolVersion" 4 "StackVersion" 5 "DbcVersion" 16 "HeartbeatInterval" 32 "SendOdOnBootup" 33 "OdEntrySendInterval" 1040 "CpuUsage" 1041 "MemFree" 1042 "BoardTemp" 1043 "InputVoltage" 1044 "runtime" 1045 "SdcIn" 1046 "SdcOut" 1056 "ChipUID1" 1057 "ChipUID2" 1072 "BuildDate" 1073 "BuildTime" 1104 "CAN1_TxErrCnt" 1105 "CAN1_RxErrCnt" 1106 "CAN1_lastErrorCode" 1107 "CAN1_autoErrorReset" 1108 "CAN1_Baudrate" 1110 "CAN1_Status" 1111 "CAN1_DiscardedTxMessages" 1112 "CAN1_ErrorStatus" 1113 "CAN1_DelayedTxMessages" 1120 "CAN2_TxErrCnt" 1121 "CAN2_RxErrCnt" 1122 "CAN2_lastErrorCode" 1123 "CAN2_autoErrorReset" 1124 "CAN2_Baudrate" 1126 "CAN2_Status" 1127 "CAN2_DiscardedTxMessages" 1128 "CAN2_ErrorStatus" 1129 "CAN2_DelayedTxMessages" 2048 "samplingInterval" 2576 "EncoderWheelDiameter" 2586 "EncoderResetPosition" 2592 "IMU_number" 2597 "IMU1_Temperature" 2598 "IMU2_Temperature" 2599 "IMU3_Temperature" 2608 "ExecTimeOverall" 2609 "ExecTimeStateEst" 2610 "ExecTimeControl" 2611 "ExecTimeReadSensors" 2624 "OpcKp" 2625 "OpcKi" 2626 "CtrlMode" 2627 "CurrentReq" 2628 "PodMass" 2629 "FmaxCtrl" 2630 "FminCtrl" 2631 "MaxCtrlError" 2632 "MaxCtrlErrorDuration" 2633 "WarningThreshholdForLimModelOutOfBoundaries" 2634 "MaxRequiredVelocity" 2635 "VdcReduceFactor" 2636 "RunMode" 2637 "SetFinish" 2816 "RunProfile_T0" 2817 "RunProfile_V0" 2818 "RunProfile_T1" 2819 "RunProfile_V1" 2820 "RunProfile_T2" 2821 "RunProfile_V2" 2822 "RunProfile_T3" 2823 "RunProfile_V3" 2824 "RunProfile_T4" 2825 "RunProfile_V4" 2826 "EstimatedRunLength" 3072 "TC_I" 3073 "TC_f" 3074 "VelocityController" 3075 "CVOPCImax" 3076 "CVOPCTcf" 3077 "CVOPCTcI" 3078 "CVOPCSmoothingDeltaVelocity" 3079 "CVOPCDeltaVelHigherCurrent" 3080 "CVOPCReduceCurrentWhileCruising" 3081 "CVOPCHystereseF" 3088 "AccAtCurrentMeasured" 3089 "CurrentForConstantVelocity" 3090 "CascadedMaxSetForceDelta" 3091 "CascadedFreqCurUpdate" 3092 "CascadedKpIncreaseCurrent" 3093 "CascadedKpDecreaseCurrent" 3094 "CVOPCImin" 3095 "CVOPCTcFreq" 3096 "AdaptModelByCurrent" 3097 "Current4Stopping" 3104 "FinishedDelay" 3105 "maxRunDistance" 3106 "opc_ratelimiter_f" 3107 "DebugCascadedIreq" 3108 "DebugCVOPCfreq" 3109 "opc_brakeFlag" 3110 "opc_t_run_max" 3111 "opc_F_max" 3112 "opc_T_acc" 3113 "opc_v_max" 3120 "opc_v_threshold" 3121 "opc_F_decrease" 3122 "opc_lowpass_Tcf" 3123 "opc_lowpass_TcI" 3329 "StripeMode" 3330 "ReflectorDistance" 3331 "PositionGlitch" 3332 "EnableSignalGeneration" 3585 "accDeviation" 3586 "velDeviationEncoder" 3587 "velDeviationOptic" 3588 "posDeviationEncoder" 3589 "posDeviationOptic" ;
VAL_ 1794 SensorR_NodeState 0 "Bootup" 4 "Stopped" 5 "Operational" 127 "Pre-Operational" ;
VAL_ 145 BrakeF_E5_retractUnsuccesful_ope 0 "Ok" 1 "ERR" ;
VAL_ 145 BrakeF_E4_retractUnsuccesful_not 0 "Ok" 1 "ERR" ;
VAL_ 145 BrakeF_E3_retractUnsuccesful_err 0 "Ok" 1 "ERR" ;
VAL_ 145 BrakeF_E2_commWatchdogTimeout 0 "Ok" 1 "ERR" ;
VAL_ 145 BrakeF_E1_pressureTooLow 0 "Ok" 1 "ERR" ;
VAL_ 145 BrakeF_E0_pressureTooHigh 0 "Ok" 1 "ERR" ;
VAL_ 145 BrakeF_W3_externalError 0 "Ok" 1 "WARN" ;
VAL_ 145 BrakeF_W2_enableWithAnError 0 "Ok" 1 "WARN" ;
VAL_ 145 BrakeF_W1_highPressureRetracting 0 "Ok" 1 "WARN" ;
VAL_ 145 BrakeF_W0_highPressureActingCham 0 "Ok" 1 "WARN" ;
VAL_ 401 BrakeF_TX_SDC_Input 1 "Closed" 0 "Open" ;
VAL_ 401 BrakeF_TX_ErrorFlag 1 "Error" 0 "No Error" ;
VAL_ 401 BrakeF_TX_Enabled 1 "Enabled" 0 "Disabled" ;
VAL_ 401 BrakeF_TX_Status 2 "EngagedService" 1 "EngagedEmergency" 0 "Disengaged" ;
VAL_ 465 BrakeF_RX_Engage 2 "EngageService" 1 "EngageEmergency" 0 "Disengage" ;
VAL_ 465 BrakeF_RX_Enable 1 "Enable" 0 "Disable" ;
VAL_ 465 BrakeF_RX_ErrorReset 1 "Reset" 0 "No Reset" ;
VAL_ 1425 BrakeF_OD_BrakeStatus 0 "Disengaged" 1 "Engaged" ;
VAL_ 1425 BrakeF_OD_CAN2_ErrorStatus 0 "Ok" 1 "Warn" 2 "Error Passive" 3 "Bus Off" ;
VAL_ 1425 BrakeF_OD_CAN2_Status 0 "Reset" 1 "Ready" 2 "Listening" 3 "Sleep_Pending" 4 "Sleep_Active" 5 "ERROR" ;
VAL_ 1425 BrakeF_OD_CAN2_autoErrorReset 0 "Disabled" 1 "Enabled" ;
VAL_ 1425 BrakeF_OD_CAN2_lastErrorCode 0 "No Error" 1 "Stuff Error" 2 "Form Error" 3 "Ack Error" 4 "Bit recessive Error" 5 "Bit dominant Error" 6 "CRC Error" ;
VAL_ 1425 BrakeF_OD_CAN1_ErrorStatus 0 "Ok" 1 "Warn" 2 "Error Passive" 3 "Bus Off" ;
VAL_ 1425 BrakeF_OD_CAN1_Status 0 "Reset" 1 "Ready" 2 "Listening" 3 "Sleep_Pending" 4 "Sleep_Active" 5 "ERROR" ;
VAL_ 1425 BrakeF_OD_CAN1_autoErrorReset 0 "Disabled" 1 "Enabled" ;
VAL_ 1425 BrakeF_OD_CAN1_lastErrorCode 0 "No Error" 1 "Stuff Error" 2 "Form Error" 3 "Ack Error" 4 "Bit recessive Error" 5 "Bit dominant Error" 6 "CRC Error" ;
VAL_ 1425 BrakeF_OD_SendOdOnBootup 0 "Disabled" 1 "Enabled" ;
VAL_ 1425 BrakeF_OD_NodeStatus 0 "Bootup" 4 "Stopped" 5 "Operational" 127 "Pre-Operational" 128 "Reset" ;
VAL_ 1425 BrakeF_SDO_RespCode 5 "ERR: Out of range" 4 "ERR: No access in this state" 3 "ERR: Read only object" 2 "ERR: Write only object" 1 "ERR: Non existing object" 0 "OK" ;
VAL_ 1425 BrakeF_SDO_ID 0 "Reserved" 1 "NodeID" 2 "NodeStatus" 3 "ProtocolVersion" 4 "StackVersion" 5 "DbcVersion" 16 "HeartbeatInterval" 32 "SendOdOnBootup" 33 "OdEntrySendInterval" 1040 "CpuUsage" 1041 "MemFree" 1042 "BoardTemp" 1043 "InputVoltage" 1044 "runtime" 1045 "SdcIn" 1046 "SdcOut" 1056 "ChipUID1" 1057 "ChipUID2" 1072 "BuildDate" 1073 "BuildTime" 1104 "CAN1_TxErrCnt" 1105 "CAN1_RxErrCnt" 1106 "CAN1_lastErrorCode" 1107 "CAN1_autoErrorReset" 1108 "CAN1_Baudrate" 1110 "CAN1_Status" 1111 "CAN1_DiscardedTxMessages" 1112 "CAN1_ErrorStatus" 1113 "CAN1_DelayedTxMessages" 1120 "CAN2_TxErrCnt" 1121 "CAN2_RxErrCnt" 1122 "CAN2_lastErrorCode" 1123 "CAN2_autoErrorReset" 1124 "CAN2_Baudrate" 1126 "CAN2_Status" 1127 "CAN2_DiscardedTxMessages" 1128 "CAN2_ErrorStatus" 1129 "CAN2_DelayedTxMessages" 2048 "tankLowerControlLimit" 2049 "tankUpperControlLimit" 2050 "delay" 2051 "counterLimit" 2052 "commWatchdog" 2053 "valveUpperTolerance" 2816 "CoolingPressure" 2304 "BrakeStatus" ;
VAL_ 1489 BrakeF_OD_BrakeStatus 0 "Disengaged" 1 "Engaged" ;
VAL_ 1489 BrakeF_OD_CAN2_ErrorStatus 0 "Ok" 1 "Warn" 2 "Error Passive" 3 "Bus Off" ;
VAL_ 1489 BrakeF_OD_CAN2_Status 0 "Reset" 1 "Ready" 2 "Listening" 3 "Sleep_Pending" 4 "Sleep_Active" 5 "ERROR" ;
VAL_ 1489 BrakeF_OD_CAN2_autoErrorReset 0 "Disabled" 1 "Enabled" ;
VAL_ 1489 BrakeF_OD_CAN2_lastErrorCode 0 "No Error" 1 "Stuff Error" 2 "Form Error" 3 "Ack Error" 4 "Bit recessive Error" 5 "Bit dominant Error" 6 "CRC Error" ;
VAL_ 1489 BrakeF_OD_CAN1_ErrorStatus 0 "Ok" 1 "Warn" 2 "Error Passive" 3 "Bus Off" ;
VAL_ 1489 BrakeF_OD_CAN1_Status 0 "Reset" 1 "Ready" 2 "Listening" 3 "Sleep_Pending" 4 "Sleep_Active" 5 "ERROR" ;
VAL_ 1489 BrakeF_OD_CAN1_autoErrorReset 0 "Disabled" 1 "Enabled" ;
VAL_ 1489 BrakeF_OD_CAN1_lastErrorCode 0 "No Error" 1 "Stuff Error" 2 "Form Error" 3 "Ack Error" 4 "Bit recessive Error" 5 "Bit dominant Error" 6 "CRC Error" ;
VAL_ 1489 BrakeF_OD_SendOdOnBootup 0 "Disabled" 1 "Enabled" ;
VAL_ 1489 BrakeF_OD_NodeStatus 0 "Bootup" 4 "Stopped" 5 "Operational" 127 "Pre-Operational" 128 "Reset" ;
VAL_ 1489 BrakeF_SDO_ID 0 "Reserved" 1 "NodeID" 2 "NodeStatus" 3 "ProtocolVersion" 4 "StackVersion" 5 "DbcVersion" 16 "HeartbeatInterval" 32 "SendOdOnBootup" 33 "OdEntrySendInterval" 1040 "CpuUsage" 1041 "MemFree" 1042 "BoardTemp" 1043 "InputVoltage" 1044 "runtime" 1045 "SdcIn" 1046 "SdcOut" 1056 "ChipUID1" 1057 "ChipUID2" 1072 "BuildDate" 1073 "BuildTime" 1104 "CAN1_TxErrCnt" 1105 "CAN1_RxErrCnt" 1106 "CAN1_lastErrorCode" 1107 "CAN1_autoErrorReset" 1108 "CAN1_Baudrate" 1110 "CAN1_Status" 1111 "CAN1_DiscardedTxMessages" 1112 "CAN1_ErrorStatus" 1113 "CAN1_DelayedTxMessages" 1120 "CAN2_TxErrCnt" 1121 "CAN2_RxErrCnt" 1122 "CAN2_lastErrorCode" 1123 "CAN2_autoErrorReset" 1124 "CAN2_Baudrate" 1126 "CAN2_Status" 1127 "CAN2_DiscardedTxMessages" 1128 "CAN2_ErrorStatus" 1129 "CAN2_DelayedTxMessages" 2048 "tankLowerControlLimit" 2049 "tankUpperControlLimit" 2050 "delay" 2051 "counterLimit" 2052 "commWatchdog" 2053 "valveUpperTolerance" 2816 "CoolingPressure" 2304 "BrakeStatus" ;
VAL_ 1553 BrakeF_SDO_ID 0 "Reserved" 1 "NodeID" 2 "NodeStatus" 3 "ProtocolVersion" 4 "StackVersion" 5 "DbcVersion" 16 "HeartbeatInterval" 32 "SendOdOnBootup" 33 "OdEntrySendInterval" 1040 "CpuUsage" 1041 "MemFree" 1042 "BoardTemp" 1043 "InputVoltage" 1044 "runtime" 1045 "SdcIn" 1046 "SdcOut" 1056 "ChipUID1" 1057 "ChipUID2" 1072 "BuildDate" 1073 "BuildTime" 1104 "CAN1_TxErrCnt" 1105 "CAN1_RxErrCnt" 1106 "CAN1_lastErrorCode" 1107 "CAN1_autoErrorReset" 1108 "CAN1_Baudrate" 1110 "CAN1_Status" 1111 "CAN1_DiscardedTxMessages" 1112 "CAN1_ErrorStatus" 1113 "CAN1_DelayedTxMessages" 1120 "CAN2_TxErrCnt" 1121 "CAN2_RxErrCnt" 1122 "CAN2_lastErrorCode" 1123 "CAN2_autoErrorReset" 1124 "CAN2_Baudrate" 1126 "CAN2_Status" 1127 "CAN2_DiscardedTxMessages" 1128 "CAN2_ErrorStatus" 1129 "CAN2_DelayedTxMessages" 2048 "tankLowerControlLimit" 2049 "tankUpperControlLimit" 2050 "delay" 2051 "counterLimit" 2052 "commWatchdog" 2053 "valveUpperTolerance" 2816 "CoolingPressure" 2304 "BrakeStatus" ;
VAL_ 1809 BrakeF_NodeState 0 "Bootup" 4 "Stopped" 5 "Operational" 127 "Pre-Operational" ;
VAL_ 146 BrakeR_E5_retractUnsuccesful_ope 0 "Ok" 1 "ERR" ;
VAL_ 146 BrakeR_E4_retractUnsuccesful_not 0 "Ok" 1 "ERR" ;
VAL_ 146 BrakeR_E3_retractUnsuccesful_err 0 "Ok" 1 "ERR" ;
VAL_ 146 BrakeR_E2_commWatchdogTimeout 0 "Ok" 1 "ERR" ;
VAL_ 146 BrakeR_E1_pressureTooLow 0 "Ok" 1 "ERR" ;
VAL_ 146 BrakeR_E0_pressureTooHigh 0 "Ok" 1 "ERR" ;
VAL_ 146 BrakeR_W3_externalError 0 "Ok" 1 "WARN" ;
VAL_ 146 BrakeR_W2_enableWithAnError 0 "Ok" 1 "WARN" ;
VAL_ 146 BrakeR_W1_highPressureRetracting 0 "Ok" 1 "WARN" ;
VAL_ 146 BrakeR_W0_highPressureActingCham 0 "Ok" 1 "WARN" ;
VAL_ 402 BrakeR_TX_SDC_Input 1 "Closed" 0 "Open" ;
VAL_ 402 BrakeR_TX_ErrorFlag 1 "Error" 0 "No Error" ;
VAL_ 402 BrakeR_TX_Enabled 1 "Enabled" 0 "Disabled" ;
VAL_ 402 BrakeR_TX_Status 2 "EngagedService" 1 "EngagedEmergency" 0 "Disengaged" ;
VAL_ 466 BrakeR_RX_Engage 2 "EngageService" 1 "EngageEmergency" 0 "Disengage" ;
VAL_ 466 BrakeR_RX_Enable 1 "Enable" 0 "Disable" ;
VAL_ 466 BrakeR_RX_ErrorReset 1 "Reset" 0 "No Reset" ;
VAL_ 1426 BrakeR_OD_CAN2_ErrorStatus 0 "Ok" 1 "Warn" 2 "Error Passive" 3 "Bus Off" ;
VAL_ 1426 BrakeR_OD_CAN2_Status 0 "Reset" 1 "Ready" 2 "Listening" 3 "Sleep_Pending" 4 "Sleep_Active" 5 "ERROR" ;
VAL_ 1426 BrakeR_OD_CAN2_autoErrorReset 0 "Disabled" 1 "Enabled" ;
VAL_ 1426 BrakeR_OD_CAN2_lastErrorCode 0 "No Error" 1 "Stuff Error" 2 "Form Error" 3 "Ack Error" 4 "Bit recessive Error" 5 "Bit dominant Error" 6 "CRC Error" ;
VAL_ 1426 BrakeR_OD_CAN1_ErrorStatus 0 "Ok" 1 "Warn" 2 "Error Passive" 3 "Bus Off" ;
VAL_ 1426 BrakeR_OD_CAN1_Status 0 "Reset" 1 "Ready" 2 "Listening" 3 "Sleep_Pending" 4 "Sleep_Active" 5 "ERROR" ;
VAL_ 1426 BrakeR_OD_CAN1_autoErrorReset 0 "Disabled" 1 "Enabled" ;
VAL_ 1426 BrakeR_OD_CAN1_lastErrorCode 0 "No Error" 1 "Stuff Error" 2 "Form Error" 3 "Ack Error" 4 "Bit recessive Error" 5 "Bit dominant Error" 6 "CRC Error" ;
VAL_ 1426 BrakeR_OD_SendOdOnBootup 0 "Disabled" 1 "Enabled" ;
VAL_ 1426 BrakeR_OD_NodeStatus 0 "Bootup" 4 "Stopped" 5 "Operational" 127 "Pre-Operational" 128 "Reset" ;
VAL_ 1426 BrakeR_SDO_RespCode 5 "ERR: Out of range" 4 "ERR: No access in this state" 3 "ERR: Read only object" 2 "ERR: Write only object" 1 "ERR: Non existing object" 0 "OK" ;
VAL_ 1426 BrakeR_SDO_ID 0 "Reserved" 1 "NodeID" 2 "NodeStatus" 3 "ProtocolVersion" 4 "StackVersion" 5 "DbcVersion" 16 "HeartbeatInterval" 32 "SendOdOnBootup" 33 "OdEntrySendInterval" 1040 "CpuUsage" 1041 "MemFree" 1042 "BoardTemp" 1043 "InputVoltage" 1044 "runtime" 1045 "SdcIn" 1046 "SdcOut" 1056 "ChipUID1" 1057 "ChipUID2" 1072 "BuildDate" 1073 "BuildTime" 1104 "CAN1_TxErrCnt" 1105 "CAN1_RxErrCnt" 1106 "CAN1_lastErrorCode" 1107 "CAN1_autoErrorReset" 1108 "CAN1_Baudrate" 1110 "CAN1_Status" 1111 "CAN1_DiscardedTxMessages" 1112 "CAN1_ErrorStatus" 1113 "CAN1_DelayedTxMessages" 1120 "CAN2_TxErrCnt" 1121 "CAN2_RxErrCnt" 1122 "CAN2_lastErrorCode" 1123 "CAN2_autoErrorReset" 1124 "CAN2_Baudrate" 1126 "CAN2_Status" 1127 "CAN2_DiscardedTxMessages" 1128 "CAN2_ErrorStatus" 1129 "CAN2_DelayedTxMessages" 2048 "tankLowerControlLimit" 2049 "tankUpperControlLimit" 2050 "delay" 2051 "counterLimit" 2052 "commWatchdog" 2053 "valveUpperTolerance" ;
VAL_ 1490 BrakeR_OD_CAN2_ErrorStatus 0 "Ok" 1 "Warn" 2 "Error Passive" 3 "Bus Off" ;
VAL_ 1490 BrakeR_OD_CAN2_Status 0 "Reset" 1 "Ready" 2 "Listening" 3 "Sleep_Pending" 4 "Sleep_Active" 5 "ERROR" ;
VAL_ 1490 BrakeR_OD_CAN2_autoErrorReset 0 "Disabled" 1 "Enabled" ;
VAL_ 1490 BrakeR_OD_CAN2_lastErrorCode 0 "No Error" 1 "Stuff Error" 2 "Form Error" 3 "Ack Error" 4 "Bit recessive Error" 5 "Bit dominant Error" 6 "CRC Error" ;
VAL_ 1490 BrakeR_OD_CAN1_ErrorStatus 0 "Ok" 1 "Warn" 2 "Error Passive" 3 "Bus Off" ;
VAL_ 1490 BrakeR_OD_CAN1_Status 0 "Reset" 1 "Ready" 2 "Listening" 3 "Sleep_Pending" 4 "Sleep_Active" 5 "ERROR" ;
VAL_ 1490 BrakeR_OD_CAN1_autoErrorReset 0 "Disabled" 1 "Enabled" ;
VAL_ 1490 BrakeR_OD_CAN1_lastErrorCode 0 "No Error" 1 "Stuff Error" 2 "Form Error" 3 "Ack Error" 4 "Bit recessive Error" 5 "Bit dominant Error" 6 "CRC Error" ;
VAL_ 1490 BrakeR_OD_SendOdOnBootup 0 "Disabled" 1 "Enabled" ;
VAL_ 1490 BrakeR_OD_NodeStatus 0 "Bootup" 4 "Stopped" 5 "Operational" 127 "Pre-Operational" 128 "Reset" ;
VAL_ 1490 BrakeR_SDO_ID 0 "Reserved" 1 "NodeID" 2 "NodeStatus" 3 "ProtocolVersion" 4 "StackVersion" 5 "DbcVersion" 16 "HeartbeatInterval" 32 "SendOdOnBootup" 33 "OdEntrySendInterval" 1040 "CpuUsage" 1041 "MemFree" 1042 "BoardTemp" 1043 "InputVoltage" 1044 "runtime" 1045 "SdcIn" 1046 "SdcOut" 1056 "ChipUID1" 1057 "ChipUID2" 1072 "BuildDate" 1073 "BuildTime" 1104 "CAN1_TxErrCnt" 1105 "CAN1_RxErrCnt" 1106 "CAN1_lastErrorCode" 1107 "CAN1_autoErrorReset" 1108 "CAN1_Baudrate" 1110 "CAN1_Status" 1111 "CAN1_DiscardedTxMessages" 1112 "CAN1_ErrorStatus" 1113 "CAN1_DelayedTxMessages" 1120 "CAN2_TxErrCnt" 1121 "CAN2_RxErrCnt" 1122 "CAN2_lastErrorCode" 1123 "CAN2_autoErrorReset" 1124 "CAN2_Baudrate" 1126 "CAN2_Status" 1127 "CAN2_DiscardedTxMessages" 1128 "CAN2_ErrorStatus" 1129 "CAN2_DelayedTxMessages" 2048 "tankLowerControlLimit" 2049 "tankUpperControlLimit" 2050 "delay" 2051 "counterLimit" 2052 "commWatchdog" 2053 "valveUpperTolerance" ;
VAL_ 1554 BrakeR_SDO_ID 0 "Reserved" 1 "NodeID" 2 "NodeStatus" 3 "ProtocolVersion" 4 "StackVersion" 5 "DbcVersion" 16 "HeartbeatInterval" 32 "SendOdOnBootup" 33 "OdEntrySendInterval" 1040 "CpuUsage" 1041 "MemFree" 1042 "BoardTemp" 1043 "InputVoltage" 1044 "runtime" 1045 "SdcIn" 1046 "SdcOut" 1056 "ChipUID1" 1057 "ChipUID2" 1072 "BuildDate" 1073 "BuildTime" 1104 "CAN1_TxErrCnt" 1105 "CAN1_RxErrCnt" 1106 "CAN1_lastErrorCode" 1107 "CAN1_autoErrorReset" 1108 "CAN1_Baudrate" 1110 "CAN1_Status" 1111 "CAN1_DiscardedTxMessages" 1112 "CAN1_ErrorStatus" 1113 "CAN1_DelayedTxMessages" 1120 "CAN2_TxErrCnt" 1121 "CAN2_RxErrCnt" 1122 "CAN2_lastErrorCode" 1123 "CAN2_autoErrorReset" 1124 "CAN2_Baudrate" 1126 "CAN2_Status" 1127 "CAN2_DiscardedTxMessages" 1128 "CAN2_ErrorStatus" 1129 "CAN2_DelayedTxMessages" 2048 "tankLowerControlLimit" 2049 "tankUpperControlLimit" 2050 "delay" 2051 "counterLimit" 2052 "commWatchdog" 2053 "valveUpperTolerance" ;
VAL_ 1810 BrakeR_NodeState 0 "Bootup" 4 "Stopped" 5 "Operational" 127 "Pre-Operational" ;
VAL_ 154 PDU_E4_watchdogStateMachine 0 "Ok" 1 "ERR" ;
VAL_ 154 PDU_E3_batterTempCritical 0 "Ok" 1 "ERR" ;
VAL_ 154 PDU_E2_batteryOvercurrent 0 "Ok" 1 "ERR" ;
VAL_ 154 PDU_E1_batterVoltageCritical 0 "Ok" 1 "ERR" ;
VAL_ 154 PDU_E0_OtherError 0 "Ok" 1 "ERR" ;
VAL_ 154 PDU_W2_batterTempHigh 0 "Ok" 1 "WARN" ;
VAL_ 154 PDU_W1_batterVoltageLow 0 "Ok" 1 "WARN" ;
VAL_ 154 PDU_W0_OtherWarning 0 "Ok" 1 "WARN" ;
VAL_ 410 PDU_TX_PEHWEnabled 1 "Enabled" 0 "Disabled" ;
VAL_ 410 PDU_TX_ErrorFlag 1 "Error" 0 "No Error" ;
VAL_ 410 PDU_TX_Enabled 1 "Enabled" 0 "Disabled" ;
VAL_ 474 PDU_RX_PEHWEnable 1 "Enable" 0 "Disable" ;
VAL_ 474 PDU_RX_ErrorReset 1 "Reset" 0 "No Reset" ;
VAL_ 474 PDU_RX_Enable 1 "Enable" 0 "Disable" ;
VAL_ 1178 PDU_LPCh1_State 3 "External Voltage" 2 "Output Short Circuit" 1 "Status Change Pending" 0 "OK" ;
VAL_ 1434 PDU_OD_CoolingPumpEnabled 0 "Disable" 1 "Enable" ;
VAL_ 1434 PDU_OD_LedCommands 0 "None" 1 "whipeanimation" 2 "mugreenanimation" 3 "rainbowanimation" 4 "flashlights" 5 "snakeanimation" 6 "blinkpink" 7 "multiwhipe" 8 "Emergency" ;
VAL_ 1434 PDU_OD_projectXXEnabled 0 "Disable" 1 "Enable" ;
VAL_ 1434 PDU_OD_CAN2_ErrorStatus 0 "Ok" 1 "Warn" 2 "Error Passive" 3 "Bus Off" ;
VAL_ 1434 PDU_OD_CAN2_Status 0 "Reset" 1 "Ready" 2 "Listening" 3 "Sleep_Pending" 4 "Sleep_Active" 5 "ERROR" ;
VAL_ 1434 PDU_OD_CAN2_autoErrorReset 0 "Disabled" 1 "Enabled" ;
VAL_ 1434 PDU_OD_CAN2_lastErrorCode 0 "No Error" 1 "Stuff Error" 2 "Form Error" 3 "Ack Error" 4 "Bit recessive Error" 5 "Bit dominant Error" 6 "CRC Error" ;
VAL_ 1434 PDU_OD_CAN1_ErrorStatus 0 "Ok" 1 "Warn" 2 "Error Passive" 3 "Bus Off" ;
VAL_ 1434 PDU_OD_CAN1_Status 0 "Reset" 1 "Ready" 2 "Listening" 3 "Sleep_Pending" 4 "Sleep_Active" 5 "ERROR" ;
VAL_ 1434 PDU_OD_CAN1_autoErrorReset 0 "Disabled" 1 "Enabled" ;
VAL_ 1434 PDU_OD_CAN1_lastErrorCode 0 "No Error" 1 "Stuff Error" 2 "Form Error" 3 "Ack Error" 4 "Bit recessive Error" 5 "Bit dominant Error" 6 "CRC Error" ;
VAL_ 1434 PDU_OD_SendOdOnBootup 0 "Disabled" 1 "Enabled" ;
VAL_ 1434 PDU_OD_NodeStatus 0 "Bootup" 4 "Stopped" 5 "Operational" 127 "Pre-Operational" 128 "Reset" ;
VAL_ 1434 PDU_SDO_RespCode 5 "ERR: Out of range" 4 "ERR: No access in this state" 3 "ERR: Read only object" 2 "ERR: Write only object" 1 "ERR: Non existing object" 0 "OK" ;
VAL_ 1434 PDU_SDO_ID 0 "Reserved" 1 "NodeID" 2 "NodeStatus" 3 "ProtocolVersion" 4 "StackVersion" 5 "DbcVersion" 16 "HeartbeatInterval" 32 "SendOdOnBootup" 33 "OdEntrySendInterval" 1040 "CpuUsage" 1041 "MemFree" 1042 "BoardTemp" 1043 "InputVoltage" 1044 "runtime" 1045 "SdcIn" 1046 "SdcOut" 1056 "ChipUID1" 1057 "ChipUID2" 1072 "BuildDate" 1073 "BuildTime" 1104 "CAN1_TxErrCnt" 1105 "CAN1_RxErrCnt" 1106 "CAN1_lastErrorCode" 1107 "CAN1_autoErrorReset" 1108 "CAN1_Baudrate" 1110 "CAN1_Status" 1111 "CAN1_DiscardedTxMessages" 1112 "CAN1_ErrorStatus" 1113 "CAN1_DelayedTxMessages" 1120 "CAN2_TxErrCnt" 1121 "CAN2_RxErrCnt" 1122 "CAN2_lastErrorCode" 1123 "CAN2_autoErrorReset" 1124 "CAN2_Baudrate" 1126 "CAN2_Status" 1127 "CAN2_DiscardedTxMessages" 1128 "CAN2_ErrorStatus" 1129 "CAN2_DelayedTxMessages" 2048 "batterVoltageLow" 2049 "batterVoltageCritical" 2050 "overTempWarn" 2051 "overTempCritical" 2128 "batteryOvercurrent" 2304 "currentReadInterval" 2305 "statusSendInterval" 2306 "watchdogTimeout" 2560 "projectXXEnabled" 2562 "LedCommands" 2816 "CoolingPumpEnabled" ;
